[part 1 of 5: packages /E3_1_2_Premium to /Cluster]
AUTOSAR XML (schema 4-3-0)
package /E3_1_2_Premium
  system System: pnc-vector-length=7, pnc-vector-offset=1
package /ECU
  ecu instance BMC_HV:  # HV Batterie Management Control DFL-Kürzel: Hybrid_01
    associated-com-i-pdu-group=[BMC_HV_XIX_HCP5_CANFD01_Tx, BMC_HV_XIX_HCP5_CANFD01_Rx, BMC_HV_XIX_BMC_CAN01_Tx, BMC_HV_XIX_BMC_CAN01_Rx, BMC_HV_XIX_PNC_01_CarWakeUp_Tx, BMC_HV_XIX_PNC_02_Basefunction_Powertrain_Rx, BMC_HV_XIX_PNC_07_Basefunction_CrossSection_Rx, BMC_HV_XIX_PNC_06_Basefunction_ComfortLight_Rx, BMC_HV_XIX_PNC_10_Powertrain_Rx, BMC_HV_XIX_PNC_11_Chassis_Rx, BMC_HV_XIX_PNC_13_Airbag_Rx, BMC_HV_XIX_PNC_24_ThermoManagement_Rx, BMC_HV_XIX_PNC_26_HighVoltage_Charging_Tx, BMC_HV_XIX_PNC_26_HighVoltage_Charging_Rx, BMC_HV_XIX_PNC_30_EnergyManagement_Tx, BMC_HV_XIX_PNC_30_EnergyManagement_Rx, BMC_HV_XIX_PNC_27_Timemaster_Timer_Rx, BMC_HV_XIX_PNC_40_Diagnosis_Energy_Tx, BMC_HV_XIX_PNC_40_Diagnosis_Energy_Rx, PduGroup_afac5c56b3b64c7983bb0f7ebfc92c5a_Tx, PduGroup_7d6a32fb6b5340f18c0d3a0826764630_Tx, PduGroup_bd14174e250b400999f7534078763f9f_Rx]
    diagnostic-address=140
    pn-reset-time=0.5
    pnc-prepare-sleep-timer=0
    sleep-mode-supported=true
    wake-up-over-bus-supported=true
    can communication controller CT_HCP5_CANFD01: wake-up-by-controller-supported=true, can-controller-attributes=can-controller-configuration-requirements={can-controller-fd-requirements={max-number-of-time-quanta-per-bit=20, max-sample-point=70, max-sync-jump-width=30, max-trcv-delay-compensation-offset=3.5E-7, min-number-of-time-quanta-per-bit=20, min-sample-point=70, min-sync-jump-width=30, min-trcv-delay-compensation-offset=3.5E-7, tx-bit-rate-switch=true}, max-number-of-time-quanta-per-bit=80, max-sample-point=80, max-sync-jump-width=20, min-number-of-time-quanta-per-bit=80, min-sample-point=80, min-sync-jump-width=20}
    can communication controller CT_BMC_CAN01: wake-up-by-controller-supported=true, can-controller-attributes=can-controller-configuration-requirements={max-number-of-time-quanta-per-bit=20, max-sample-point=84, max-sync-jump-width=20, min-number-of-time-quanta-per-bit=10, min-sample-point=80, min-sync-jump-width=20}
    can communication connector CN_HCP5_CANFD01: comm-controller=CT_HCP5_CANFD01, pnc-gateway-type=NONE
    can communication connector CN_BMC_CAN01: comm-controller=CT_BMC_CAN01
package /Cluster
  can cluster HCP5_CANFD01: baudrate=500000, protocol-name=CAN, protocol-version=2.0, bus-off-recovery={bor-counter-l-1-to-l-2=1, bor-time-l-1=0.05, bor-time-l-2=0.2}, can-fd-baudrate=2000000  # HV
    can physical channel CHNL: comm-connectors=CN_HCP5_CANFD01
      frame Airbag_10_XIX_HCP5_CANFD01: id 0x11F, to BMC_HV, frame-length=20, can-addressing-mode=STANDARD, can-frame-rx-behavior=CAN-FD, can-frame-tx-behavior=CAN-FD
        pdu Airbag_10_XIX_HCP5_CANFD01: length=16, minimum-delay=0.01, transmission-mode-true-timing={cyclic-timing={time-offset=0, time-period=0.04}, event-controlled-timing={number-of-repetitions=5, repetition-period=0.01}}, unused-bit-pattern=0
          signal Airbag_10_CRC_XIX_Airbag_10_XIX_HCP5_CANFD01: start 0, 8 bit, little-endian, data-type-policy=OVERRIDE, i-signal-type=PRIMITIVE, init-value=0, base-type=BT_Airbag_10_CRC, compu-method=CM_Airbag_10_CRC, data-constr=DC_Airbag_10_CRC, transfer-property=PENDING  # Für MLB: Berechnung siehe Lastenheft "Kommunikationsabsicherung für FlexRay und CAN" Ab MQB und MLBevo: Berechnung siehe Lastenheft "End-to-End Kommunikationsabsicherung" Endwerte siehe Begleitdokument "S-PDU Kennungsfolgen"
          signal Airbag_10_BZ_XIX_Airbag_10_XIX_HCP5_CANFD01: start 8, 4 bit, little-endian, data-type-policy=OVERRIDE, i-signal-type=PRIMITIVE, init-value=0, base-type=BT_Airbag_10_BZ, compu-method=CM_Airbag_10_BZ, data-constr=DC_Airbag_10_BZ, transfer-property=PENDING  # 4bit-Botschaftszaehler, wird in jeder Sendebotschaft inkrementiert
          signal AB_VRU_Crash_XIX_Airbag_10_XIX_HCP5_CANFD01: start 12, 1 bit, little-endian, data-type-policy=OVERRIDE, i-signal-type=PRIMITIVE, init-value=0, base-type=BT_AB_VRU_Crash, compu-method=CM_AB_VRU_Crash, data-constr=DC_AB_VRU_Crash, transfer-property=TRIGGERED-ON-CHANGE  # Anprall eines Passanten erkannt
          signal AB_Lampe_XIX_Airbag_10_XIX_HCP5_CANFD01: start 13, 1 bit, little-endian, data-type-policy=OVERRIDE, i-signal-type=PRIMITIVE, init-value=1, base-type=BT_AB_Lampe, compu-method=CM_AB_Lampe, data-constr=DC_AB_Lampe, transfer-property=PENDING  # Sicherheitswarnlampe im Kombi wird vom Airbag-SG angesteuert; Zustand der Lampe wird auf dem CAN-Bus ausgegeben (auch Blinkinformation).
          signal AB_Front_Crash_XIX_Airbag_10_XIX_HCP5_CANFD01: start 14, 1 bit, little-endian, data-type-policy=OVERRIDE, i-signal-type=PRIMITIVE, init-value=0, base-type=BT_AB_Front_Crash, compu-method=CM_AB_Front_Crash, data-constr=DC_AB_Front_Crash, transfer-property=TRIGGERED-ON-CHANGE  # Bit wird bei Überschreitung der Gurtstraffer-, US- und RdW-Schwelle gesetzt
          signal AB_Heck_Crash_XIX_Airbag_10_XIX_HCP5_CANFD01: start 15, 1 bit, little-endian, data-type-policy=OVERRIDE, i-signal-type=PRIMITIVE, init-value=0, base-type=BT_AB_Heck_Crash, compu-method=CM_AB_Heck_Crash, data-constr=DC_AB_Heck_Crash, transfer-property=TRIGGERED-ON-CHANGE  # Wird für alle neu anlaufenden Projekte umgesetzt: AB8.4, Audi8/VW8
          signal AB_SF_Crash_XIX_Airbag_10_XIX_HCP5_CANFD01: start 16, 1 bit, little-endian, data-type-policy=OVERRIDE, i-signal-type=PRIMITIVE, init-value=0, base-type=BT_AB_SF_Crash, compu-method=CM_AB_SF_Crash, data-constr=DC_AB_SF_Crash, transfer-property=TRIGGERED-ON-CHANGE  # Z.Zt. nur in Verbindung mit Crash-Intensität >= 100b (Kraftstoffpumpenabschaltung) verwendet.
          signal AB_SB_Crash_XIX_Airbag_10_XIX_HCP5_CANFD01: start 17, 1 bit, little-endian, data-type-policy=OVERRIDE, i-signal-type=PRIMITIVE, init-value=0, base-type=BT_AB_SB_Crash, compu-method=CM_AB_SB_Crash, data-constr=DC_AB_SB_Crash, transfer-property=TRIGGERED-ON-CHANGE  # Z.Zt. nur in Verbindung mit Crash-Intensität >= 100b (Kraftstoffpumpenabschaltung) verwendet.
          signal AB_Rollover_Crash_XIX_Airbag_10_XIX_HCP5_CANFD01: start 18, 1 bit, little-endian, data-type-policy=OVERRIDE, i-signal-type=PRIMITIVE, init-value=0, base-type=BT_AB_Rollover_Crash, compu-method=CM_AB_Rollover_Crash, data-constr=DC_AB_Rollover_Crash, transfer-property=TRIGGERED-ON-CHANGE  # Wird im B6/B7 Cabrio und New Beetle Cabrio bedient.
          signal AB_Crash_Int_XIX_Airbag_10_XIX_HCP5_CANFD01: start 19, 3 bit, little-endian, data-type-policy=OVERRIDE, i-signal-type=PRIMITIVE, init-value=0, base-type=BT_AB_Crash_Int, compu-method=CM_AB_Crash_Int, data-constr=DC_AB_Crash_Int, transfer-property=TRIGGERED-ON-CHANGE  # Crash_Intensität_1 = fahrzeugabhängige Reaktionen im Crash Crash_Intensität_2 = fahrzeugabhängige Reaktionen im Crash Crash_Intensität_3 = fahrzeugabhängige Reaktionen im Crash Die jeweiligen fahrzeugabhängigen Reaktionen im Crash sind in einem separaten Doors Modul im Airbag-SG beschrieben. Die Information bleibt bei jeder Schwellwert-überschreitung für ~10 s bestehen (Achtung: Energiereserve bei abgetrennter Batterie reicht worstcase nur für 150 ms)
          signal AB_Systemfehler_XIX_Airbag_10_XIX_HCP5_CANFD01: start 22, 1 bit, little-endian, data-type-policy=OVERRIDE, i-signal-type=PRIMITIVE, init-value=0, base-type=BT_AB_Systemfehler, compu-method=CM_AB_Systemfehler, data-constr=DC_AB_Systemfehler, transfer-property=PENDING  # Systemfehler Ggf. wird Warnlampe dauernd eingeschaltet.
          signal AB_Stellgliedtest_XIX_Airbag_10_XIX_HCP5_CANFD01: start 23, 1 bit, little-endian, data-type-policy=OVERRIDE, i-signal-type=PRIMITIVE, init-value=0, base-type=BT_AB_Stellgliedtest, compu-method=CM_AB_Stellgliedtest, data-constr=DC_AB_Stellgliedtest, transfer-property=PENDING  # Information, ob Airbag im Stellgliedtest ist, um eine Notrufauflösung beim Stellgliedtest zu verhindern
          signal AB_Erh_Auf_VB_XIX_Airbag_10_XIX_HCP5_CANFD01: start 24, 2 bit, little-endian, data-type-policy=OVERRIDE, i-signal-type=PRIMITIVE, init-value=0, base-type=BT_AB_Erh_Auf_VB, compu-method=CM_AB_Erh_Auf_VB, data-constr=DC_AB_Erh_Auf_VB, transfer-property=PENDING  # Der Fahrer soll bei einem Statuswechsel des Beifahrerairbags (ausgelöst durch die Beifahrerinsassenerkennung oder den Schlüsselschloßschalter) aufmerksam gemacht werden durch eine Anzeige im Kombi. Nur Audi: gültig für: AB2 (4-Türer AU352), B7, C6, D3
          signal AB_Gurtwarn_VF_XIX_Airbag_10_XIX_HCP5_CANFD01: start 26, 1 bit, little-endian, data-type-policy=OVERRIDE, i-signal-type=PRIMITIVE, init-value=0, base-type=BT_AB_Gurtwarn_VF, compu-method=CM_AB_Gurtwarn_VF, data-constr=DC_AB_Gurtwarn_VF, transfer-property=TRIGGERED-ON-CHANGE-WITHOUT-REPETITION  # Fahrer hat Gurt nicht gesteckt, Anzeige im Kombi
          signal AB_Gurtwarn_VB_XIX_Airbag_10_XIX_HCP5_CANFD01: start 27, 1 bit, little-endian, data-type-policy=OVERRIDE, i-signal-type=PRIMITIVE, init-value=0, base-type=BT_AB_Gurtwarn_VB, compu-method=CM_AB_Gurtwarn_VB, data-constr=DC_AB_Gurtwarn_VB, transfer-property=TRIGGERED-ON-CHANGE-WITHOUT-REPETITION  # Beifahrer hat Gurt nicht gesteckt, Anzeige im Kombi
          signal AB_Anzeige_Fussg_XIX_Airbag_10_XIX_HCP5_CANFD01: start 28, 2 bit, little-endian, data-type-policy=OVERRIDE, i-signal-type=PRIMITIVE, init-value=0, base-type=BT_AB_Anzeige_Fussg, compu-method=CM_AB_Anzeige_Fussg, data-constr=DC_AB_Anzeige_Fussg, transfer-property=PENDING  # Anzeige für ausgelöste Fussgängerschutz-Aktuatorik
          signal AB_Belegung_VB_XIX_Airbag_10_XIX_HCP5_CANFD01: start 30, 2 bit, little-endian, data-type-policy=OVERRIDE, i-signal-type=PRIMITIVE, init-value=0, base-type=BT_AB_Belegung_VB, invalid-value=Invalid_AB_Belegung_VB_XIX_Airbag_10_XIX_HCP5_CANFD01:1, compu-method=CM_AB_Belegung_VB, data-constr=DC_AB_Belegung_VB, transfer-property=TRIGGERED-ON-CHANGE-WITHOUT-REPETITION  # Belegungserkennung vorne Beifahrer. Wird in US-Steuergeräten über Bladder-Matte bedient, optional bei RdW, falls SBE_EuroNCAP entschieden wird.
          signal AB_Versorgungsspannung_XIX_Airbag_10_XIX_HCP5_CANFD01: start 32, 1 bit, little-endian, data-type-policy=OVERRIDE, i-signal-type=PRIMITIVE, init-value=0, base-type=BT_AB_Versorgungsspannung, compu-method=CM_AB_Versorgungsspannung, data-constr=DC_AB_Versorgungsspannung, transfer-property=TRIGGERED-ON-CHANGE-WITHOUT-REPETITION  # Übertragung der Plausibilitätsinformation Kl.15-Last vs. Kl.15-CAN. Bedienung im Fall Kl.15-Last "EIN" und Kl.15-CAN "AUS" mit Ausgabe Warnung/Akustik im Kombi.
          signal AB_Sitzpos_Sens_BF_XIX_Airbag_10_XIX_HCP5_CANFD01: start 33, 2 bit, little-endian, data-type-policy=OVERRIDE, i-signal-type=PRIMITIVE, init-value=0, base-type=BT_AB_Sitzpos_Sens_BF, invalid-value=Invalid_AB_Sitzpos_Sens_BF_XIX_Airbag_10_XIX_HCP5_CANFD01:1, compu-method=CM_AB_Sitzpos_Sens_BF, data-constr=DC_AB_Sitzpos_Sens_BF, transfer-property=PENDING  # Ausgabe Sitzposition Beifahrer
          signal AB_Sitzpos_Sens_FA_XIX_Airbag_10_XIX_HCP5_CANFD01: start 35, 2 bit, little-endian, data-type-policy=OVERRIDE, i-signal-type=PRIMITIVE, init-value=0, base-type=BT_AB_Sitzpos_Sens_FA, invalid-value=Invalid_AB_Sitzpos_Sens_FA_XIX_Airbag_10_XIX_HCP5_CANFD01:1, compu-method=CM_AB_Sitzpos_Sens_FA, data-constr=DC_AB_Sitzpos_Sens_FA, transfer-property=PENDING  # Ausgabe Sitzposition Fahrer
          signal AB_Gurtschloss_FA_ext_XIX_Airbag_10_XIX_HCP5_CANFD01: start 37, 3 bit, little-endian, data-type-policy=OVERRIDE, i-signal-type=PRIMITIVE, init-value=6, base-type=BT_AB_Gurtschloss_FA_ext, invalid-value=Invalid_AB_Gurtschloss_FA_ext_XIX_Airbag_10_XIX_HCP5_CANFD01:7, compu-method=CM_AB_Gurtschloss_FA_ext, data-constr=DC_AB_Gurtschloss_FA_ext, transfer-property=TRIGGERED-ON-CHANGE-WITHOUT-REPETITION  # Das Ergebnis der Basisfunktion "Plausibilisierung Gurtschloss" des Verlassenskonzepts wird im Signal dargestellt.
          signal AB_Gurtschloss_FA_ext_aktiv_XIX_Airbag_10_XIX_HCP5_CANFD01: start 40, 1 bit, little-endian, data-type-policy=OVERRIDE, i-signal-type=PRIMITIVE, init-value=0, base-type=BT_AB_Gurtschloss_FA_ext_aktiv, compu-method=CM_AB_Gurtschloss_FA_ext_aktiv, data-constr=DC_AB_Gurtschloss_FA_ext_aktiv, transfer-property=TRIGGERED-ON-CHANGE-WITHOUT-REPETITION  # Über dieses Signal wird signalisiert ob die Erweiterte Gurtdiagnose (Ergebnis wird im Signal AB_Gurtschloss_FA_ext dargestellt) aktiviert oder deaktiviert ist.
          signal AB_Gurtschloss_BF_XIX_Airbag_10_XIX_HCP5_CANFD01: start 41, 2 bit, little-endian, data-type-policy=OVERRIDE, i-signal-type=PRIMITIVE, init-value=1, base-type=BT_AB_Gurtschloss_BF, compu-method=CM_AB_Gurtschloss_BF, data-constr=DC_AB_Gurtschloss_BF, transfer-property=TRIGGERED-ON-CHANGE-WITHOUT-REPETITION  # Gurtschlossstatus Beifahrerseite
          signal AB_Gurtschloss_FA_XIX_Airbag_10_XIX_HCP5_CANFD01: start 43, 2 bit, little-endian, data-type-policy=OVERRIDE, i-signal-type=PRIMITIVE, init-value=1, base-type=BT_AB_Gurtschloss_FA, compu-method=CM_AB_Gurtschloss_FA, data-constr=DC_AB_Gurtschloss_FA, transfer-property=TRIGGERED-ON-CHANGE-WITHOUT-REPETITION  # Gurtschlosstatatus Fahrerseite
          signal AB_Gurtschloss_Reihe3_BF_XIX_Airbag_10_XIX_HCP5_CANFD01: start 45, 2 bit, little-endian, data-type-policy=OVERRIDE, i-signal-type=PRIMITIVE, init-value=1, base-type=BT_AB_Gurtschloss_Reihe3_BF, compu-method=CM_AB_Gurtschloss_Reihe3_BF, data-constr=DC_AB_Gurtschloss_Reihe3_BF, transfer-property=TRIGGERED-ON-CHANGE-WITHOUT-REPETITION  # Gurtschlossstatus 3. Reihe Beifahrerseite, Mehrausstattung
          signal AB_Gurtschloss_Reihe2_BF_XIX_Airbag_10_XIX_HCP5_CANFD01: start 47, 2 bit, little-endian, data-type-policy=OVERRIDE, i-signal-type=PRIMITIVE, init-value=1, base-type=BT_AB_Gurtschloss_Reihe2_BF, compu-method=CM_AB_Gurtschloss_Reihe2_BF, data-constr=DC_AB_Gurtschloss_Reihe2_BF, transfer-property=TRIGGERED-ON-CHANGE-WITHOUT-REPETITION  # Gurtschlossstatus 2. Reihe Beifahrerseite, Mehrausstattung
          signal AB_Gurtschloss_Reihe2_FA_XIX_Airbag_10_XIX_HCP5_CANFD01: start 49, 2 bit, little-endian, data-type-policy=OVERRIDE, i-signal-type=PRIMITIVE, init-value=1, base-type=BT_AB_Gurtschloss_Reihe2_FA, compu-method=CM_AB_Gurtschloss_Reihe2_FA, data-constr=DC_AB_Gurtschloss_Reihe2_FA, transfer-property=TRIGGERED-ON-CHANGE-WITHOUT-REPETITION  # Gurtschlossstatus 2. Reihe Fahrerseite, Mehrausstattung
          signal AB_Gurtschloss_Reihe2_MI_XIX_Airbag_10_XIX_HCP5_CANFD01: start 51, 2 bit, little-endian, data-type-policy=OVERRIDE, i-signal-type=PRIMITIVE, init-value=1, base-type=BT_AB_Gurtschloss_Reihe2_MI, compu-method=CM_AB_Gurtschloss_Reihe2_MI, data-constr=DC_AB_Gurtschloss_Reihe2_MI, transfer-property=TRIGGERED-ON-CHANGE-WITHOUT-REPETITION  # Gurtschlossstatus 2. Reihe Mitte, Mehrausstattung
          signal AB_Gurtschloss_Reihe4_FA_XIX_Airbag_10_XIX_HCP5_CANFD01: start 53, 2 bit, little-endian, data-type-policy=OVERRIDE, i-signal-type=PRIMITIVE, init-value=1, base-type=BT_AB_Gurtschloss_Reihe4_FA, compu-method=CM_AB_Gurtschloss_Reihe4_FA, data-constr=DC_AB_Gurtschloss_Reihe4_FA, transfer-property=TRIGGERED-ON-CHANGE-WITHOUT-REPETITION  # Gurtschlossstatus 4. Reihe Fahrerseite, Mehrausstattung
          signal AB_Gurtschloss_Reihe3_FA_XIX_Airbag_10_XIX_HCP5_CANFD01: start 55, 2 bit, little-endian, data-type-policy=OVERRIDE, i-signal-type=PRIMITIVE, init-value=1, base-type=BT_AB_Gurtschloss_Reihe3_FA, compu-method=CM_AB_Gurtschloss_Reihe3_FA, data-constr=DC_AB_Gurtschloss_Reihe3_FA, transfer-property=TRIGGERED-ON-CHANGE-WITHOUT-REPETITION  # Gurtschlossstatus 3. Reihe Fahrerseite, Mehrausstattung
          signal AB_Gurtschloss_Reihe3_MI_XIX_Airbag_10_XIX_HCP5_CANFD01: start 57, 2 bit, little-endian, data-type-policy=OVERRIDE, i-signal-type=PRIMITIVE, init-value=1, base-type=BT_AB_Gurtschloss_Reihe3_MI, compu-method=CM_AB_Gurtschloss_Reihe3_MI, data-constr=DC_AB_Gurtschloss_Reihe3_MI, transfer-property=TRIGGERED-ON-CHANGE-WITHOUT-REPETITION  # Gurtschlossstatus 3. Reihe Mitte, Mehrausstattung
          signal AB_Gurtschloss_Reihe4_BF_XIX_Airbag_10_XIX_HCP5_CANFD01: start 59, 2 bit, little-endian, data-type-policy=OVERRIDE, i-signal-type=PRIMITIVE, init-value=1, base-type=BT_AB_Gurtschloss_Reihe4_BF, compu-method=CM_AB_Gurtschloss_Reihe4_BF, data-constr=DC_AB_Gurtschloss_Reihe4_BF, transfer-property=TRIGGERED-ON-CHANGE-WITHOUT-REPETITION  # Gurtschlossstatus 4. Reihe Beifahrerseite, Mehrausstattung
          signal AB_Gurtwarn_Reihe2_MI_XIX_Airbag_10_XIX_HCP5_CANFD01: start 61, 2 bit, little-endian, data-type-policy=OVERRIDE, i-signal-type=PRIMITIVE, init-value=0, base-type=BT_AB_Gurtwarn_Reihe2_MI, compu-method=CM_AB_Gurtwarn_Reihe2_MI, data-constr=DC_AB_Gurtwarn_Reihe2_MI, transfer-property=TRIGGERED-ON-CHANGE-WITHOUT-REPETITION  # Status Gurtwarnung 2. Sitzreihe Mitte
          signal AB_Gurtschloss_Reihe4_MI_XIX_Airbag_10_XIX_HCP5_CANFD01: start 63, 2 bit, little-endian, data-type-policy=OVERRIDE, i-signal-type=PRIMITIVE, init-value=1, base-type=BT_AB_Gurtschloss_Reihe4_MI, compu-method=CM_AB_Gurtschloss_Reihe4_MI, data-constr=DC_AB_Gurtschloss_Reihe4_MI, transfer-property=TRIGGERED-ON-CHANGE-WITHOUT-REPETITION  # Gurtschlossstatus 4. Reihe Mitte, Mehrausstattung
          signal AB_Gurtwarn_Reihe2_BF_XIX_Airbag_10_XIX_HCP5_CANFD01: start 65, 2 bit, little-endian, data-type-policy=OVERRIDE, i-signal-type=PRIMITIVE, init-value=0, base-type=BT_AB_Gurtwarn_Reihe2_BF, compu-method=CM_AB_Gurtwarn_Reihe2_BF, data-constr=DC_AB_Gurtwarn_Reihe2_BF, transfer-property=TRIGGERED-ON-CHANGE-WITHOUT-REPETITION  # Status Gurtwarnung 2. Sitzreihe Beifahrerseite
          signal AB_Gurtwarn_Reihe2_FA_XIX_Airbag_10_XIX_HCP5_CANFD01: start 67, 2 bit, little-endian, data-type-policy=OVERRIDE, i-signal-type=PRIMITIVE, init-value=0, base-type=BT_AB_Gurtwarn_Reihe2_FA, compu-method=CM_AB_Gurtwarn_Reihe2_FA, data-constr=DC_AB_Gurtwarn_Reihe2_FA, transfer-property=TRIGGERED-ON-CHANGE-WITHOUT-REPETITION  # Status Gurtwarnung 2. Sitzreihe Fahrerseite
          signal AB_Belegung_VF_ext_aktiv_XIX_Airbag_10_XIX_HCP5_CANFD01: start 69, 1 bit, little-endian, data-type-policy=OVERRIDE, i-signal-type=PRIMITIVE, init-value=0, base-type=BT_AB_Belegung_VF_ext_aktiv, compu-method=CM_AB_Belegung_VF_ext_aktiv, data-constr=DC_AB_Belegung_VF_ext_aktiv, transfer-property=PENDING  # Kennzeichnet aktive Funktion "Erweiterte Sitzbelegdiagnose" für Signal AB_Belegung_VF_ext
          signal AB_Belegung_VF_ext_XIX_Airbag_10_XIX_HCP5_CANFD01: start 70, 3 bit, little-endian, data-type-policy=OVERRIDE, i-signal-type=PRIMITIVE, init-value=6, base-type=BT_AB_Belegung_VF_ext, invalid-value=Invalid_AB_Belegung_VF_ext_XIX_Airbag_10_XIX_HCP5_CANFD01:7, compu-method=CM_AB_Belegung_VF_ext, data-constr=DC_AB_Belegung_VF_ext, transfer-property=TRIGGERED-ON-CHANGE-WITHOUT-REPETITION  # Das Signal kommuniziert den Status des Sitzbelegsensors Fahrer incl. dauerhafter Zustände mit Signalqualität ASIL A.
          signal AB_Abschaltanf_SIH_BF_XIX_Airbag_10_XIX_HCP5_CANFD01: start 73, 1 bit, little-endian, data-type-policy=OVERRIDE, i-signal-type=PRIMITIVE, init-value=0, base-type=BT_AB_Abschaltanf_SIH_BF, compu-method=CM_AB_Abschaltanf_SIH_BF, data-constr=DC_AB_Abschaltanf_SIH_BF, transfer-property=TRIGGERED-ON-CHANGE-WITHOUT-REPETITION  # Die Insassenerkennung auf der Beifahrerseite fordert bei Übertemperatur eine Abschaltung der Sitzheizung an. Die Übertemperatur kann bei niederohmigen Nebenschlüssen der Sitzheizungsmatte als Folge von zu hohem resultierenden Strom auftreten.
          signal AB_Gurtwarn_Reihe3_BF_XIX_Airbag_10_XIX_HCP5_CANFD01: start 74, 2 bit, little-endian, data-type-policy=OVERRIDE, i-signal-type=PRIMITIVE, init-value=0, base-type=BT_AB_Gurtwarn_Reihe3_BF, compu-method=CM_AB_Gurtwarn_Reihe3_BF, data-constr=DC_AB_Gurtwarn_Reihe3_BF, transfer-property=TRIGGERED-ON-CHANGE-WITHOUT-REPETITION  # Status Gurtwarnung 3. Sitzreihe Beifahrerseite
          signal AB_Gurtwarn_Reihe3_FA_XIX_Airbag_10_XIX_HCP5_CANFD01: start 76, 2 bit, little-endian, data-type-policy=OVERRIDE, i-signal-type=PRIMITIVE, init-value=0, base-type=BT_AB_Gurtwarn_Reihe3_FA, compu-method=CM_AB_Gurtwarn_Reihe3_FA, data-constr=DC_AB_Gurtwarn_Reihe3_FA, transfer-property=TRIGGERED-ON-CHANGE-WITHOUT-REPETITION  # Status Gurtwarnung 3. Sitzreihe Fahrerseite
          signal AB_Gurtwarn_Reihe3_MI_XIX_Airbag_10_XIX_HCP5_CANFD01: start 78, 2 bit, little-endian, data-type-policy=OVERRIDE, i-signal-type=PRIMITIVE, init-value=0, base-type=BT_AB_Gurtwarn_Reihe3_MI, compu-method=CM_AB_Gurtwarn_Reihe3_MI, data-constr=DC_AB_Gurtwarn_Reihe3_MI, transfer-property=TRIGGERED-ON-CHANGE-WITHOUT-REPETITION  # Status Gurtwarnung 3. Sitzreihe Mitte
          signal AB_PSS_SollZustand_XIX_Airbag_10_XIX_HCP5_CANFD01: start 80, 1 bit, little-endian, data-type-policy=OVERRIDE, i-signal-type=PRIMITIVE, init-value=0, base-type=BT_AB_PSS_SollZustand, compu-method=CM_AB_PSS_SollZustand, data-constr=DC_AB_PSS_SollZustand, transfer-property=TRIGGERED-ON-CHANGE  # Erwartete Auslösefähigkeit
          signal AB_EDR_Trigger_XIX_Airbag_10_XIX_HCP5_CANFD01: start 81, 2 bit, little-endian, data-type-policy=OVERRIDE, i-signal-type=PRIMITIVE, init-value=0, base-type=BT_AB_EDR_Trigger, compu-method=CM_AB_EDR_Trigger, data-constr=DC_AB_EDR_Trigger, transfer-property=TRIGGERED-ON-CHANGE-WITHOUT-REPETITION  # Triggerbedingung zur dezentralen Aufzeichnung unfallrelevanter Daten im Event Data Recorder
          signal AB_Deaktivierung_HV_XIX_Airbag_10_XIX_HCP5_CANFD01: start 83, 3 bit, little-endian, data-type-policy=OVERRIDE, i-signal-type=PRIMITIVE, init-value=0, base-type=BT_AB_Deaktivierung_HV, invalid-value=Invalid_AB_Deaktivierung_HV_XIX_Airbag_10_XIX_HCP5_CANFD01:7, compu-method=CM_AB_Deaktivierung_HV, data-constr=DC_AB_Deaktivierung_HV, transfer-property=TRIGGERED, to BMC_HV(timeout 0.5 s)  # Deaktivierung des HV-Systems und der HV-Teilnehmer im Crash (u.a. Hybrid- und Elektrofahrzeuge)
          signal AB_Belegung_VF_XIX_Airbag_10_XIX_HCP5_CANFD01: start 86, 2 bit, little-endian, data-type-policy=OVERRIDE, i-signal-type=PRIMITIVE, init-value=0, base-type=BT_AB_Belegung_VF, invalid-value=Invalid_AB_Belegung_VF_XIX_Airbag_10_XIX_HCP5_CANFD01:1, compu-method=CM_AB_Belegung_VF, data-constr=DC_AB_Belegung_VF, transfer-property=TRIGGERED-ON-CHANGE-WITHOUT-REPETITION  # Belegungserkennung vorne Fahrer.
          signal AB_SBR_hinten_verbau_XIX_Airbag_10_XIX_HCP5_CANFD01: start 88, 2 bit, little-endian, data-type-policy=OVERRIDE, i-signal-type=PRIMITIVE, init-value=3, base-type=BT_AB_SBR_hinten_verbau, compu-method=CM_AB_SBR_hinten_verbau, data-constr=DC_AB_SBR_hinten_verbau, transfer-property=PENDING  # Verbauinformation Sitzbelegungssensor hinten (2. und 3. Sitzreihe)
          signal MKB_ScndCllsnMtgtn_StAbo_XIX_Airbag_10_XIX_HCP5_CANFD01: start 90, 1 bit, little-endian, data-type-policy=OVERRIDE, i-signal-type=PRIMITIVE, init-value=0, base-type=BT_MKB_ScndCllsnMtgtn_StAbo, compu-method=CM_MKB_ScndCllsnMtgtn_StAbo, data-constr=DC_MKB_ScndCllsnMtgtn_StAbo, transfer-property=TRIGGERED-ON-CHANGE  # Request to abort second collision mitigation
          signal MKB_ScndCllsnMtgtn_StReq_XIX_Airbag_10_XIX_HCP5_CANFD01: start 91, 1 bit, little-endian, data-type-policy=OVERRIDE, i-signal-type=PRIMITIVE, init-value=0, base-type=BT_MKB_ScndCllsnMtgtn_StReq, compu-method=CM_MKB_ScndCllsnMtgtn_StReq, data-constr=DC_MKB_ScndCllsnMtgtn_StReq, transfer-property=TRIGGERED-ON-CHANGE  # Request to trigger second collision mitigation
          signal AB_DeltaV_X_eCall_XIX_Airbag_10_XIX_HCP5_CANFD01: start 92, 8 bit, little-endian, data-type-policy=OVERRIDE, i-signal-type=PRIMITIVE, init-value=0, base-type=BT_AB_DeltaV_X_eCall, compu-method=CM_AB_DeltaV_X_eCall, data-constr=DC_AB_DeltaV_X_eCall, unit=Unit_Unit_KiloMeterPerHour, transfer-property=TRIGGERED-ON-CHANGE-WITHOUT-REPETITION  # Transmission of the DeltaV longitudinal during Crash (0-250ms) as additional information for eCall
          signal AB_DeltaV_Y_eCall_XIX_Airbag_10_XIX_HCP5_CANFD01: start 100, 8 bit, little-endian, data-type-policy=OVERRIDE, i-signal-type=PRIMITIVE, init-value=0, base-type=BT_AB_DeltaV_Y_eCall, compu-method=CM_AB_DeltaV_Y_eCall, data-constr=DC_AB_DeltaV_Y_eCall, unit=Unit_Unit_KiloMeterPerHour, transfer-property=TRIGGERED-ON-CHANGE-WITHOUT-REPETITION  # Transmission of the DeltaV lateral during Crash (0-250ms) as additional information for eCall
      frame BMC_CMC_Temperatur_01_XIX_HCP5_CANFD01: id 0x1A55562A, from BMC_HV, frame-length=64, can-addressing-mode=EXTENDED, can-frame-rx-behavior=CAN-FD, can-frame-tx-behavior=CAN-FD
        pdu BMC_CMC_Temperatur_01_XIX_HCP5_CANFD01: length=64, transmission-mode-true-timing=cyclic-timing={time-offset=0, time-period=1}, unused-bit-pattern=0
          signal BMC_CMC_Temperatur_001_XIX_BMC_CMC_Temperatur_01_XIX_HCP5_CANFD01: start 16, 8 bit, little-endian, data-type-policy=OVERRIDE, i-signal-type=PRIMITIVE, init-value=254, base-type=BT_BMC_CMC_Temperatur_001, invalid-value=Invalid_BMC_CMC_Temperatur_001_XIX_BMC_CMC_Temperatur_01_XIX_HCP5_CANFD01:255, compu-method=CM_BMC_CMC_Temperatur_001, data-constr=DC_BMC_CMC_Temperatur_001, unit=Unit_Unit_DegreCelsi, transfer-property=PENDING  # Temperatur Zellmodul fuer die Uebertragung per RTM
          signal BMC_CMC_Temperatur_002_XIX_BMC_CMC_Temperatur_01_XIX_HCP5_CANFD01: start 24, 8 bit, little-endian, data-type-policy=OVERRIDE, i-signal-type=PRIMITIVE, init-value=254, base-type=BT_BMC_CMC_Temperatur_002, invalid-value=Invalid_BMC_CMC_Temperatur_002_XIX_BMC_CMC_Temperatur_01_XIX_HCP5_CANFD01:255, compu-method=CM_BMC_CMC_Temperatur_002, data-constr=DC_BMC_CMC_Temperatur_002, unit=Unit_Unit_DegreCelsi, transfer-property=PENDING  # Temperatur Zellmodul fuer die Uebertragung per RTM
          signal BMC_CMC_Temperatur_003_XIX_BMC_CMC_Temperatur_01_XIX_HCP5_CANFD01: start 32, 8 bit, little-endian, data-type-policy=OVERRIDE, i-signal-type=PRIMITIVE, init-value=254, base-type=BT_BMC_CMC_Temperatur_003, invalid-value=Invalid_BMC_CMC_Temperatur_003_XIX_BMC_CMC_Temperatur_01_XIX_HCP5_CANFD01:255, compu-method=CM_BMC_CMC_Temperatur_003, data-constr=DC_BMC_CMC_Temperatur_003, unit=Unit_Unit_DegreCelsi, transfer-property=PENDING  # Temperatur Zellmodul fuer die Uebertragung per RTM
          signal BMC_CMC_Temperatur_004_XIX_BMC_CMC_Temperatur_01_XIX_HCP5_CANFD01: start 40, 8 bit, little-endian, data-type-policy=OVERRIDE, i-signal-type=PRIMITIVE, init-value=254, base-type=BT_BMC_CMC_Temperatur_004, invalid-value=Invalid_BMC_CMC_Temperatur_004_XIX_BMC_CMC_Temperatur_01_XIX_HCP5_CANFD01:255, compu-method=CM_BMC_CMC_Temperatur_004, data-constr=DC_BMC_CMC_Temperatur_004, unit=Unit_Unit_DegreCelsi, transfer-property=PENDING  # Temperatur Zellmodul fuer die Uebertragung per RTM
          signal BMC_CMC_Temperatur_005_XIX_BMC_CMC_Temperatur_01_XIX_HCP5_CANFD01: start 48, 8 bit, little-endian, data-type-policy=OVERRIDE, i-signal-type=PRIMITIVE, init-value=254, base-type=BT_BMC_CMC_Temperatur_005, invalid-value=Invalid_BMC_CMC_Temperatur_005_XIX_BMC_CMC_Temperatur_01_XIX_HCP5_CANFD01:255, compu-method=CM_BMC_CMC_Temperatur_005, data-constr=DC_BMC_CMC_Temperatur_005, unit=Unit_Unit_DegreCelsi, transfer-property=PENDING  # Temperatur Zellmodul fuer die Uebertragung per RTM
          signal BMC_CMC_Temperatur_006_XIX_BMC_CMC_Temperatur_01_XIX_HCP5_CANFD01: start 56, 8 bit, little-endian, data-type-policy=OVERRIDE, i-signal-type=PRIMITIVE, init-value=254, base-type=BT_BMC_CMC_Temperatur_006, invalid-value=Invalid_BMC_CMC_Temperatur_006_XIX_BMC_CMC_Temperatur_01_XIX_HCP5_CANFD01:255, compu-method=CM_BMC_CMC_Temperatur_006, data-constr=DC_BMC_CMC_Temperatur_006, unit=Unit_Unit_DegreCelsi, transfer-property=PENDING  # Temperatur Zellmodul fuer die Uebertragung per RTM
          signal BMC_CMC_Temperatur_007_XIX_BMC_CMC_Temperatur_01_XIX_HCP5_CANFD01: start 64, 8 bit, little-endian, data-type-policy=OVERRIDE, i-signal-type=PRIMITIVE, init-value=254, base-type=BT_BMC_CMC_Temperatur_007, invalid-value=Invalid_BMC_CMC_Temperatur_007_XIX_BMC_CMC_Temperatur_01_XIX_HCP5_CANFD01:255, compu-method=CM_BMC_CMC_Temperatur_007, data-constr=DC_BMC_CMC_Temperatur_007, unit=Unit_Unit_DegreCelsi, transfer-property=PENDING  # Temperatur Zellmodul fuer die Uebertragung per RTM
          signal BMC_CMC_Temperatur_008_XIX_BMC_CMC_Temperatur_01_XIX_HCP5_CANFD01: start 72, 8 bit, little-endian, data-type-policy=OVERRIDE, i-signal-type=PRIMITIVE, init-value=254, base-type=BT_BMC_CMC_Temperatur_008, invalid-value=Invalid_BMC_CMC_Temperatur_008_XIX_BMC_CMC_Temperatur_01_XIX_HCP5_CANFD01:255, compu-method=CM_BMC_CMC_Temperatur_008, data-constr=DC_BMC_CMC_Temperatur_008, unit=Unit_Unit_DegreCelsi, transfer-property=PENDING  # Temperatur Zellmodul fuer die Uebertragung per RTM
          signal BMC_CMC_Temperatur_009_XIX_BMC_CMC_Temperatur_01_XIX_HCP5_CANFD01: start 80, 8 bit, little-endian, data-type-policy=OVERRIDE, i-signal-type=PRIMITIVE, init-value=254, base-type=BT_BMC_CMC_Temperatur_009, invalid-value=Invalid_BMC_CMC_Temperatur_009_XIX_BMC_CMC_Temperatur_01_XIX_HCP5_CANFD01:255, compu-method=CM_BMC_CMC_Temperatur_009, data-constr=DC_BMC_CMC_Temperatur_009, unit=Unit_Unit_DegreCelsi, transfer-property=PENDING  # Temperatur Zellmodul fuer die Uebertragung per RTM
          signal BMC_CMC_Temperatur_010_XIX_BMC_CMC_Temperatur_01_XIX_HCP5_CANFD01: start 88, 8 bit, little-endian, data-type-policy=OVERRIDE, i-signal-type=PRIMITIVE, init-value=254, base-type=BT_BMC_CMC_Temperatur_010, invalid-value=Invalid_BMC_CMC_Temperatur_010_XIX_BMC_CMC_Temperatur_01_XIX_HCP5_CANFD01:255, compu-method=CM_BMC_CMC_Temperatur_010, data-constr=DC_BMC_CMC_Temperatur_010, unit=Unit_Unit_DegreCelsi, transfer-property=PENDING  # Temperatur Zellmodul fuer die Uebertragung per RTM
          signal BMC_CMC_Temperatur_011_XIX_BMC_CMC_Temperatur_01_XIX_HCP5_CANFD01: start 96, 8 bit, little-endian, data-type-policy=OVERRIDE, i-signal-type=PRIMITIVE, init-value=254, base-type=BT_BMC_CMC_Temperatur_011, invalid-value=Invalid_BMC_CMC_Temperatur_011_XIX_BMC_CMC_Temperatur_01_XIX_HCP5_CANFD01:255, compu-method=CM_BMC_CMC_Temperatur_011, data-constr=DC_BMC_CMC_Temperatur_011, unit=Unit_Unit_DegreCelsi, transfer-property=PENDING  # Temperatur Zellmodul fuer die Uebertragung per RTM
          signal BMC_CMC_Temperatur_012_XIX_BMC_CMC_Temperatur_01_XIX_HCP5_CANFD01: start 104, 8 bit, little-endian, data-type-policy=OVERRIDE, i-signal-type=PRIMITIVE, init-value=254, base-type=BT_BMC_CMC_Temperatur_012, invalid-value=Invalid_BMC_CMC_Temperatur_012_XIX_BMC_CMC_Temperatur_01_XIX_HCP5_CANFD01:255, compu-method=CM_BMC_CMC_Temperatur_012, data-constr=DC_BMC_CMC_Temperatur_012, unit=Unit_Unit_DegreCelsi, transfer-property=PENDING  # Temperatur Zellmodul fuer die Uebertragung per RTM
          signal BMC_CMC_Temperatur_013_XIX_BMC_CMC_Temperatur_01_XIX_HCP5_CANFD01: start 112, 8 bit, little-endian, data-type-policy=OVERRIDE, i-signal-type=PRIMITIVE, init-value=254, base-type=BT_BMC_CMC_Temperatur_013, invalid-value=Invalid_BMC_CMC_Temperatur_013_XIX_BMC_CMC_Temperatur_01_XIX_HCP5_CANFD01:255, compu-method=CM_BMC_CMC_Temperatur_013, data-constr=DC_BMC_CMC_Temperatur_013, unit=Unit_Unit_DegreCelsi, transfer-property=PENDING  # Temperatur Zellmodul fuer die Uebertragung per RTM
          signal BMC_CMC_Temperatur_014_XIX_BMC_CMC_Temperatur_01_XIX_HCP5_CANFD01: start 120, 8 bit, little-endian, data-type-policy=OVERRIDE, i-signal-type=PRIMITIVE, init-value=254, base-type=BT_BMC_CMC_Temperatur_014, invalid-value=Invalid_BMC_CMC_Temperatur_014_XIX_BMC_CMC_Temperatur_01_XIX_HCP5_CANFD01:255, compu-method=CM_BMC_CMC_Temperatur_014, data-constr=DC_BMC_CMC_Temperatur_014, unit=Unit_Unit_DegreCelsi, transfer-property=PENDING  # Temperatur Zellmodul fuer die Uebertragung per RTM
          signal BMC_CMC_Temperatur_015_XIX_BMC_CMC_Temperatur_01_XIX_HCP5_CANFD01: start 128, 8 bit, little-endian, data-type-policy=OVERRIDE, i-signal-type=PRIMITIVE, init-value=254, base-type=BT_BMC_CMC_Temperatur_015, invalid-value=Invalid_BMC_CMC_Temperatur_015_XIX_BMC_CMC_Temperatur_01_XIX_HCP5_CANFD01:255, compu-method=CM_BMC_CMC_Temperatur_015, data-constr=DC_BMC_CMC_Temperatur_015, unit=Unit_Unit_DegreCelsi, transfer-property=PENDING  # Temperatur Zellmodul fuer die Uebertragung per RTM
          signal BMC_CMC_Temperatur_016_XIX_BMC_CMC_Temperatur_01_XIX_HCP5_CANFD01: start 136, 8 bit, little-endian, data-type-policy=OVERRIDE, i-signal-type=PRIMITIVE, init-value=254, base-type=BT_BMC_CMC_Temperatur_016, invalid-value=Invalid_BMC_CMC_Temperatur_016_XIX_BMC_CMC_Temperatur_01_XIX_HCP5_CANFD01:255, compu-method=CM_BMC_CMC_Temperatur_016, data-constr=DC_BMC_CMC_Temperatur_016, unit=Unit_Unit_DegreCelsi, transfer-property=PENDING  # Temperatur Zellmodul fuer die Uebertragung per RTM
          signal BMC_CMC_Temperatur_017_XIX_BMC_CMC_Temperatur_01_XIX_HCP5_CANFD01: start 144, 8 bit, little-endian, data-type-policy=OVERRIDE, i-signal-type=PRIMITIVE, init-value=254, base-type=BT_BMC_CMC_Temperatur_017, invalid-value=Invalid_BMC_CMC_Temperatur_017_XIX_BMC_CMC_Temperatur_01_XIX_HCP5_CANFD01:255, compu-method=CM_BMC_CMC_Temperatur_017, data-constr=DC_BMC_CMC_Temperatur_017, unit=Unit_Unit_DegreCelsi, transfer-property=PENDING  # Temperatur Zellmodul fuer die Uebertragung per RTM
          signal BMC_CMC_Temperatur_018_XIX_BMC_CMC_Temperatur_01_XIX_HCP5_CANFD01: start 152, 8 bit, little-endian, data-type-policy=OVERRIDE, i-signal-type=PRIMITIVE, init-value=254, base-type=BT_BMC_CMC_Temperatur_018, invalid-value=Invalid_BMC_CMC_Temperatur_018_XIX_BMC_CMC_Temperatur_01_XIX_HCP5_CANFD01:255, compu-method=CM_BMC_CMC_Temperatur_018, data-constr=DC_BMC_CMC_Temperatur_018, unit=Unit_Unit_DegreCelsi, transfer-property=PENDING  # Temperatur Zellmodul fuer die Uebertragung per RTM
          signal BMC_CMC_Temperatur_019_XIX_BMC_CMC_Temperatur_01_XIX_HCP5_CANFD01: start 160, 8 bit, little-endian, data-type-policy=OVERRIDE, i-signal-type=PRIMITIVE, init-value=254, base-type=BT_BMC_CMC_Temperatur_019, invalid-value=Invalid_BMC_CMC_Temperatur_019_XIX_BMC_CMC_Temperatur_01_XIX_HCP5_CANFD01:255, compu-method=CM_BMC_CMC_Temperatur_019, data-constr=DC_BMC_CMC_Temperatur_019, unit=Unit_Unit_DegreCelsi, transfer-property=PENDING  # Temperatur Zellmodul fuer die Uebertragung per RTM
          signal BMC_CMC_Temperatur_020_XIX_BMC_CMC_Temperatur_01_XIX_HCP5_CANFD01: start 168, 8 bit, little-endian, data-type-policy=OVERRIDE, i-signal-type=PRIMITIVE, init-value=254, base-type=BT_BMC_CMC_Temperatur_020, invalid-value=Invalid_BMC_CMC_Temperatur_020_XIX_BMC_CMC_Temperatur_01_XIX_HCP5_CANFD01:255, compu-method=CM_BMC_CMC_Temperatur_020, data-constr=DC_BMC_CMC_Temperatur_020, unit=Unit_Unit_DegreCelsi, transfer-property=PENDING  # Temperatur Zellmodul fuer die Uebertragung per RTM
          signal BMC_CMC_Temperatur_021_XIX_BMC_CMC_Temperatur_01_XIX_HCP5_CANFD01: start 176, 8 bit, little-endian, data-type-policy=OVERRIDE, i-signal-type=PRIMITIVE, init-value=254, base-type=BT_BMC_CMC_Temperatur_021, invalid-value=Invalid_BMC_CMC_Temperatur_021_XIX_BMC_CMC_Temperatur_01_XIX_HCP5_CANFD01:255, compu-method=CM_BMC_CMC_Temperatur_021, data-constr=DC_BMC_CMC_Temperatur_021, unit=Unit_Unit_DegreCelsi, transfer-property=PENDING  # Temperatur Zellmodul fuer die Uebertragung per RTM
          signal BMC_CMC_Temperatur_022_XIX_BMC_CMC_Temperatur_01_XIX_HCP5_CANFD01: start 184, 8 bit, little-endian, data-type-policy=OVERRIDE, i-signal-type=PRIMITIVE, init-value=254, base-type=BT_BMC_CMC_Temperatur_022, invalid-value=Invalid_BMC_CMC_Temperatur_022_XIX_BMC_CMC_Temperatur_01_XIX_HCP5_CANFD01:255, compu-method=CM_BMC_CMC_Temperatur_022, data-constr=DC_BMC_CMC_Temperatur_022, unit=Unit_Unit_DegreCelsi, transfer-property=PENDING  # Temperatur Zellmodul fuer die Uebertragung per RTM
          signal BMC_CMC_Temperatur_023_XIX_BMC_CMC_Temperatur_01_XIX_HCP5_CANFD01: start 192, 8 bit, little-endian, data-type-policy=OVERRIDE, i-signal-type=PRIMITIVE, init-value=254, base-type=BT_BMC_CMC_Temperatur_023, invalid-value=Invalid_BMC_CMC_Temperatur_023_XIX_BMC_CMC_Temperatur_01_XIX_HCP5_CANFD01:255, compu-method=CM_BMC_CMC_Temperatur_023, data-constr=DC_BMC_CMC_Temperatur_023, unit=Unit_Unit_DegreCelsi, transfer-property=PENDING  # Temperatur Zellmodul fuer die Uebertragung per RTM
          signal BMC_CMC_Temperatur_024_XIX_BMC_CMC_Temperatur_01_XIX_HCP5_CANFD01: start 200, 8 bit, little-endian, data-type-policy=OVERRIDE, i-signal-type=PRIMITIVE, init-value=254, base-type=BT_BMC_CMC_Temperatur_024, invalid-value=Invalid_BMC_CMC_Temperatur_024_XIX_BMC_CMC_Temperatur_01_XIX_HCP5_CANFD01:255, compu-method=CM_BMC_CMC_Temperatur_024, data-constr=DC_BMC_CMC_Temperatur_024, unit=Unit_Unit_DegreCelsi, transfer-property=PENDING  # Temperatur Zellmodul fuer die Uebertragung per RTM
          signal BMC_CMC_Temperatur_025_XIX_BMC_CMC_Temperatur_01_XIX_HCP5_CANFD01: start 208, 8 bit, little-endian, data-type-policy=OVERRIDE, i-signal-type=PRIMITIVE, init-value=254, base-type=BT_BMC_CMC_Temperatur_025, invalid-value=Invalid_BMC_CMC_Temperatur_025_XIX_BMC_CMC_Temperatur_01_XIX_HCP5_CANFD01:255, compu-method=CM_BMC_CMC_Temperatur_025, data-constr=DC_BMC_CMC_Temperatur_025, unit=Unit_Unit_DegreCelsi, transfer-property=PENDING  # Temperatur Zellmodul fuer die Uebertragung per RTM
          signal BMC_CMC_Temperatur_026_XIX_BMC_CMC_Temperatur_01_XIX_HCP5_CANFD01: start 216, 8 bit, little-endian, data-type-policy=OVERRIDE, i-signal-type=PRIMITIVE, init-value=254, base-type=BT_BMC_CMC_Temperatur_026, invalid-value=Invalid_BMC_CMC_Temperatur_026_XIX_BMC_CMC_Temperatur_01_XIX_HCP5_CANFD01:255, compu-method=CM_BMC_CMC_Temperatur_026, data-constr=DC_BMC_CMC_Temperatur_026, unit=Unit_Unit_DegreCelsi, transfer-property=PENDING  # Temperatur Zellmodul fuer die Uebertragung per RTM
          signal BMC_CMC_Temperatur_027_XIX_BMC_CMC_Temperatur_01_XIX_HCP5_CANFD01: start 224, 8 bit, little-endian, data-type-policy=OVERRIDE, i-signal-type=PRIMITIVE, init-value=254, base-type=BT_BMC_CMC_Temperatur_027, invalid-value=Invalid_BMC_CMC_Temperatur_027_XIX_BMC_CMC_Temperatur_01_XIX_HCP5_CANFD01:255, compu-method=CM_BMC_CMC_Temperatur_027, data-constr=DC_BMC_CMC_Temperatur_027, unit=Unit_Unit_DegreCelsi, transfer-property=PENDING  # Temperatur Zellmodul fuer die Uebertragung per RTM
          signal BMC_CMC_Temperatur_028_XIX_BMC_CMC_Temperatur_01_XIX_HCP5_CANFD01: start 232, 8 bit, little-endian, data-type-policy=OVERRIDE, i-signal-type=PRIMITIVE, init-value=254, base-type=BT_BMC_CMC_Temperatur_028, invalid-value=Invalid_BMC_CMC_Temperatur_028_XIX_BMC_CMC_Temperatur_01_XIX_HCP5_CANFD01:255, compu-method=CM_BMC_CMC_Temperatur_028, data-constr=DC_BMC_CMC_Temperatur_028, unit=Unit_Unit_DegreCelsi, transfer-property=PENDING  # Temperatur Zellmodul fuer die Uebertragung per RTM
          signal BMC_CMC_Temperatur_029_XIX_BMC_CMC_Temperatur_01_XIX_HCP5_CANFD01: start 240, 8 bit, little-endian, data-type-policy=OVERRIDE, i-signal-type=PRIMITIVE, init-value=254, base-type=BT_BMC_CMC_Temperatur_029, invalid-value=Invalid_BMC_CMC_Temperatur_029_XIX_BMC_CMC_Temperatur_01_XIX_HCP5_CANFD01:255, compu-method=CM_BMC_CMC_Temperatur_029, data-constr=DC_BMC_CMC_Temperatur_029, unit=Unit_Unit_DegreCelsi, transfer-property=PENDING  # Temperatur Zellmodul fuer die Uebertragung per RTM
          signal BMC_CMC_Temperatur_030_XIX_BMC_CMC_Temperatur_01_XIX_HCP5_CANFD01: start 248, 8 bit, little-endian, data-type-policy=OVERRIDE, i-signal-type=PRIMITIVE, init-value=254, base-type=BT_BMC_CMC_Temperatur_030, invalid-value=Invalid_BMC_CMC_Temperatur_030_XIX_BMC_CMC_Temperatur_01_XIX_HCP5_CANFD01:255, compu-method=CM_BMC_CMC_Temperatur_030, data-constr=DC_BMC_CMC_Temperatur_030, unit=Unit_Unit_DegreCelsi, transfer-property=PENDING  # Temperatur Zellmodul fuer die Uebertragung per RTM
          signal BMC_CMC_Temperatur_031_XIX_BMC_CMC_Temperatur_01_XIX_HCP5_CANFD01: start 256, 8 bit, little-endian, data-type-policy=OVERRIDE, i-signal-type=PRIMITIVE, init-value=254, base-type=BT_BMC_CMC_Temperatur_031, invalid-value=Invalid_BMC_CMC_Temperatur_031_XIX_BMC_CMC_Temperatur_01_XIX_HCP5_CANFD01:255, compu-method=CM_BMC_CMC_Temperatur_031, data-constr=DC_BMC_CMC_Temperatur_031, unit=Unit_Unit_DegreCelsi, transfer-property=PENDING  # Temperatur Zellmodul fuer die Uebertragung per RTM
          signal BMC_CMC_Temperatur_032_XIX_BMC_CMC_Temperatur_01_XIX_HCP5_CANFD01: start 264, 8 bit, little-endian, data-type-policy=OVERRIDE, i-signal-type=PRIMITIVE, init-value=254, base-type=BT_BMC_CMC_Temperatur_032, invalid-value=Invalid_BMC_CMC_Temperatur_032_XIX_BMC_CMC_Temperatur_01_XIX_HCP5_CANFD01:255, compu-method=CM_BMC_CMC_Temperatur_032, data-constr=DC_BMC_CMC_Temperatur_032, unit=Unit_Unit_DegreCelsi, transfer-property=PENDING  # Temperatur Zellmodul fuer die Uebertragung per RTM
          signal BMC_CMC_Temperatur_033_XIX_BMC_CMC_Temperatur_01_XIX_HCP5_CANFD01: start 272, 8 bit, little-endian, data-type-policy=OVERRIDE, i-signal-type=PRIMITIVE, init-value=254, base-type=BT_BMC_CMC_Temperatur_033, invalid-value=Invalid_BMC_CMC_Temperatur_033_XIX_BMC_CMC_Temperatur_01_XIX_HCP5_CANFD01:255, compu-method=CM_BMC_CMC_Temperatur_033, data-constr=DC_BMC_CMC_Temperatur_033, unit=Unit_Unit_DegreCelsi, transfer-property=PENDING  # Temperatur Zellmodul fuer die Uebertragung per RTM
          signal BMC_CMC_Temperatur_034_XIX_BMC_CMC_Temperatur_01_XIX_HCP5_CANFD01: start 280, 8 bit, little-endian, data-type-policy=OVERRIDE, i-signal-type=PRIMITIVE, init-value=254, base-type=BT_BMC_CMC_Temperatur_034, invalid-value=Invalid_BMC_CMC_Temperatur_034_XIX_BMC_CMC_Temperatur_01_XIX_HCP5_CANFD01:255, compu-method=CM_BMC_CMC_Temperatur_034, data-constr=DC_BMC_CMC_Temperatur_034, unit=Unit_Unit_DegreCelsi, transfer-property=PENDING  # Temperatur Zellmodul fuer die Uebertragung per RTM
          signal BMC_CMC_Temperatur_035_XIX_BMC_CMC_Temperatur_01_XIX_HCP5_CANFD01: start 288, 8 bit, little-endian, data-type-policy=OVERRIDE, i-signal-type=PRIMITIVE, init-value=254, base-type=BT_BMC_CMC_Temperatur_035, invalid-value=Invalid_BMC_CMC_Temperatur_035_XIX_BMC_CMC_Temperatur_01_XIX_HCP5_CANFD01:255, compu-method=CM_BMC_CMC_Temperatur_035, data-constr=DC_BMC_CMC_Temperatur_035, unit=Unit_Unit_DegreCelsi, transfer-property=PENDING  # Temperatur Zellmodul fuer die Uebertragung per RTM
          signal BMC_CMC_Temperatur_036_XIX_BMC_CMC_Temperatur_01_XIX_HCP5_CANFD01: start 296, 8 bit, little-endian, data-type-policy=OVERRIDE, i-signal-type=PRIMITIVE, init-value=254, base-type=BT_BMC_CMC_Temperatur_036, invalid-value=Invalid_BMC_CMC_Temperatur_036_XIX_BMC_CMC_Temperatur_01_XIX_HCP5_CANFD01:255, compu-method=CM_BMC_CMC_Temperatur_036, data-constr=DC_BMC_CMC_Temperatur_036, unit=Unit_Unit_DegreCelsi, transfer-property=PENDING  # Temperatur Zellmodul fuer die Uebertragung per RTM
          signal BMC_CMC_Temperatur_037_XIX_BMC_CMC_Temperatur_01_XIX_HCP5_CANFD01: start 304, 8 bit, little-endian, data-type-policy=OVERRIDE, i-signal-type=PRIMITIVE, init-value=254, base-type=BT_BMC_CMC_Temperatur_037, invalid-value=Invalid_BMC_CMC_Temperatur_037_XIX_BMC_CMC_Temperatur_01_XIX_HCP5_CANFD01:255, compu-method=CM_BMC_CMC_Temperatur_037, data-constr=DC_BMC_CMC_Temperatur_037, unit=Unit_Unit_DegreCelsi, transfer-property=PENDING  # Temperatur Zellmodul fuer die Uebertragung per RTM
          signal BMC_CMC_Temperatur_038_XIX_BMC_CMC_Temperatur_01_XIX_HCP5_CANFD01: start 312, 8 bit, little-endian, data-type-policy=OVERRIDE, i-signal-type=PRIMITIVE, init-value=254, base-type=BT_BMC_CMC_Temperatur_038, invalid-value=Invalid_BMC_CMC_Temperatur_038_XIX_BMC_CMC_Temperatur_01_XIX_HCP5_CANFD01:255, compu-method=CM_BMC_CMC_Temperatur_038, data-constr=DC_BMC_CMC_Temperatur_038, unit=Unit_Unit_DegreCelsi, transfer-property=PENDING  # Temperatur Zellmodul fuer die Uebertragung per RTM
          signal BMC_CMC_Temperatur_039_XIX_BMC_CMC_Temperatur_01_XIX_HCP5_CANFD01: start 320, 8 bit, little-endian, data-type-policy=OVERRIDE, i-signal-type=PRIMITIVE, init-value=254, base-type=BT_BMC_CMC_Temperatur_039, invalid-value=Invalid_BMC_CMC_Temperatur_039_XIX_BMC_CMC_Temperatur_01_XIX_HCP5_CANFD01:255, compu-method=CM_BMC_CMC_Temperatur_039, data-constr=DC_BMC_CMC_Temperatur_039, unit=Unit_Unit_DegreCelsi, transfer-property=PENDING  # Temperatur Zellmodul fuer die Uebertragung per RTM
          signal BMC_CMC_Temperatur_040_XIX_BMC_CMC_Temperatur_01_XIX_HCP5_CANFD01: start 328, 8 bit, little-endian, data-type-policy=OVERRIDE, i-signal-type=PRIMITIVE, init-value=254, base-type=BT_BMC_CMC_Temperatur_040, invalid-value=Invalid_BMC_CMC_Temperatur_040_XIX_BMC_CMC_Temperatur_01_XIX_HCP5_CANFD01:255, compu-method=CM_BMC_CMC_Temperatur_040, data-constr=DC_BMC_CMC_Temperatur_040, unit=Unit_Unit_DegreCelsi, transfer-property=PENDING  # Temperatur Zellmodul fuer die Uebertragung per RTM
          signal BMC_CMC_Temperatur_041_XIX_BMC_CMC_Temperatur_01_XIX_HCP5_CANFD01: start 336, 8 bit, little-endian, data-type-policy=OVERRIDE, i-signal-type=PRIMITIVE, init-value=254, base-type=BT_BMC_CMC_Temperatur_041, invalid-value=Invalid_BMC_CMC_Temperatur_041_XIX_BMC_CMC_Temperatur_01_XIX_HCP5_CANFD01:255, compu-method=CM_BMC_CMC_Temperatur_041, data-constr=DC_BMC_CMC_Temperatur_041, unit=Unit_Unit_DegreCelsi, transfer-property=PENDING  # Temperatur Zellmodul fuer die Uebertragung per RTM
          signal BMC_CMC_Temperatur_042_XIX_BMC_CMC_Temperatur_01_XIX_HCP5_CANFD01: start 344, 8 bit, little-endian, data-type-policy=OVERRIDE, i-signal-type=PRIMITIVE, init-value=254, base-type=BT_BMC_CMC_Temperatur_042, invalid-value=Invalid_BMC_CMC_Temperatur_042_XIX_BMC_CMC_Temperatur_01_XIX_HCP5_CANFD01:255, compu-method=CM_BMC_CMC_Temperatur_042, data-constr=DC_BMC_CMC_Temperatur_042, unit=Unit_Unit_DegreCelsi, transfer-property=PENDING  # Temperatur Zellmodul fuer die Uebertragung per RTM
          signal BMC_CMC_Temperatur_043_XIX_BMC_CMC_Temperatur_01_XIX_HCP5_CANFD01: start 352, 8 bit, little-endian, data-type-policy=OVERRIDE, i-signal-type=PRIMITIVE, init-value=254, base-type=BT_BMC_CMC_Temperatur_043, invalid-value=Invalid_BMC_CMC_Temperatur_043_XIX_BMC_CMC_Temperatur_01_XIX_HCP5_CANFD01:255, compu-method=CM_BMC_CMC_Temperatur_043, data-constr=DC_BMC_CMC_Temperatur_043, unit=Unit_Unit_DegreCelsi, transfer-property=PENDING  # Temperatur Zellmodul fuer die Uebertragung per RTM
          signal BMC_CMC_Temperatur_044_XIX_BMC_CMC_Temperatur_01_XIX_HCP5_CANFD01: start 360, 8 bit, little-endian, data-type-policy=OVERRIDE, i-signal-type=PRIMITIVE, init-value=254, base-type=BT_BMC_CMC_Temperatur_044, invalid-value=Invalid_BMC_CMC_Temperatur_044_XIX_BMC_CMC_Temperatur_01_XIX_HCP5_CANFD01:255, compu-method=CM_BMC_CMC_Temperatur_044, data-constr=DC_BMC_CMC_Temperatur_044, unit=Unit_Unit_DegreCelsi, transfer-property=PENDING  # Temperatur Zellmodul fuer die Uebertragung per RTM
          signal BMC_CMC_Temperatur_045_XIX_BMC_CMC_Temperatur_01_XIX_HCP5_CANFD01: start 368, 8 bit, little-endian, data-type-policy=OVERRIDE, i-signal-type=PRIMITIVE, init-value=254, base-type=BT_BMC_CMC_Temperatur_045, invalid-value=Invalid_BMC_CMC_Temperatur_045_XIX_BMC_CMC_Temperatur_01_XIX_HCP5_CANFD01:255, compu-method=CM_BMC_CMC_Temperatur_045, data-constr=DC_BMC_CMC_Temperatur_045, unit=Unit_Unit_DegreCelsi, transfer-property=PENDING  # Temperatur Zellmodul fuer die Uebertragung per RTM
          signal BMC_CMC_Temperatur_046_XIX_BMC_CMC_Temperatur_01_XIX_HCP5_CANFD01: start 376, 8 bit, little-endian, data-type-policy=OVERRIDE, i-signal-type=PRIMITIVE, init-value=254, base-type=BT_BMC_CMC_Temperatur_046, invalid-value=Invalid_BMC_CMC_Temperatur_046_XIX_BMC_CMC_Temperatur_01_XIX_HCP5_CANFD01:255, compu-method=CM_BMC_CMC_Temperatur_046, data-constr=DC_BMC_CMC_Temperatur_046, unit=Unit_Unit_DegreCelsi, transfer-property=PENDING  # Temperatur Zellmodul fuer die Uebertragung per RTM
          signal BMC_CMC_Temperatur_047_XIX_BMC_CMC_Temperatur_01_XIX_HCP5_CANFD01: start 384, 8 bit, little-endian, data-type-policy=OVERRIDE, i-signal-type=PRIMITIVE, init-value=254, base-type=BT_BMC_CMC_Temperatur_047, invalid-value=Invalid_BMC_CMC_Temperatur_047_XIX_BMC_CMC_Temperatur_01_XIX_HCP5_CANFD01:255, compu-method=CM_BMC_CMC_Temperatur_047, data-constr=DC_BMC_CMC_Temperatur_047, unit=Unit_Unit_DegreCelsi, transfer-property=PENDING  # Temperatur Zellmodul fuer die Uebertragung per RTM
          signal BMC_CMC_Temperatur_048_XIX_BMC_CMC_Temperatur_01_XIX_HCP5_CANFD01: start 392, 8 bit, little-endian, data-type-policy=OVERRIDE, i-signal-type=PRIMITIVE, init-value=254, base-type=BT_BMC_CMC_Temperatur_048, invalid-value=Invalid_BMC_CMC_Temperatur_048_XIX_BMC_CMC_Temperatur_01_XIX_HCP5_CANFD01:255, compu-method=CM_BMC_CMC_Temperatur_048, data-constr=DC_BMC_CMC_Temperatur_048, unit=Unit_Unit_DegreCelsi, transfer-property=PENDING  # Temperatur Zellmodul fuer die Uebertragung per RTM
          signal BMC_CMC_Temperatur_049_XIX_BMC_CMC_Temperatur_01_XIX_HCP5_CANFD01: start 400, 8 bit, little-endian, data-type-policy=OVERRIDE, i-signal-type=PRIMITIVE, init-value=254, base-type=BT_BMC_CMC_Temperatur_049, invalid-value=Invalid_BMC_CMC_Temperatur_049_XIX_BMC_CMC_Temperatur_01_XIX_HCP5_CANFD01:255, compu-method=CM_BMC_CMC_Temperatur_049, data-constr=DC_BMC_CMC_Temperatur_049, unit=Unit_Unit_DegreCelsi, transfer-property=PENDING  # Temperatur Zellmodul fuer die Uebertragung per RTM
          signal BMC_CMC_Temperatur_050_XIX_BMC_CMC_Temperatur_01_XIX_HCP5_CANFD01: start 408, 8 bit, little-endian, data-type-policy=OVERRIDE, i-signal-type=PRIMITIVE, init-value=254, base-type=BT_BMC_CMC_Temperatur_050, invalid-value=Invalid_BMC_CMC_Temperatur_050_XIX_BMC_CMC_Temperatur_01_XIX_HCP5_CANFD01:255, compu-method=CM_BMC_CMC_Temperatur_050, data-constr=DC_BMC_CMC_Temperatur_050, unit=Unit_Unit_DegreCelsi, transfer-property=PENDING  # Temperatur Zellmodul fuer die Uebertragung per RTM
          signal BMC_CMC_Temperatur_051_XIX_BMC_CMC_Temperatur_01_XIX_HCP5_CANFD01: start 416, 8 bit, little-endian, data-type-policy=OVERRIDE, i-signal-type=PRIMITIVE, init-value=254, base-type=BT_BMC_CMC_Temperatur_051, invalid-value=Invalid_BMC_CMC_Temperatur_051_XIX_BMC_CMC_Temperatur_01_XIX_HCP5_CANFD01:255, compu-method=CM_BMC_CMC_Temperatur_051, data-constr=DC_BMC_CMC_Temperatur_051, unit=Unit_Unit_DegreCelsi, transfer-property=PENDING  # Temperatur Zellmodul fuer die Uebertragung per RTM
          signal BMC_CMC_Temperatur_052_XIX_BMC_CMC_Temperatur_01_XIX_HCP5_CANFD01: start 424, 8 bit, little-endian, data-type-policy=OVERRIDE, i-signal-type=PRIMITIVE, init-value=254, base-type=BT_BMC_CMC_Temperatur_052, invalid-value=Invalid_BMC_CMC_Temperatur_052_XIX_BMC_CMC_Temperatur_01_XIX_HCP5_CANFD01:255, compu-method=CM_BMC_CMC_Temperatur_052, data-constr=DC_BMC_CMC_Temperatur_052, unit=Unit_Unit_DegreCelsi, transfer-property=PENDING  # Temperatur Zellmodul fuer die Uebertragung per RTM
          signal BMC_CMC_Temperatur_053_XIX_BMC_CMC_Temperatur_01_XIX_HCP5_CANFD01: start 432, 8 bit, little-endian, data-type-policy=OVERRIDE, i-signal-type=PRIMITIVE, init-value=254, base-type=BT_BMC_CMC_Temperatur_053, invalid-value=Invalid_BMC_CMC_Temperatur_053_XIX_BMC_CMC_Temperatur_01_XIX_HCP5_CANFD01:255, compu-method=CM_BMC_CMC_Temperatur_053, data-constr=DC_BMC_CMC_Temperatur_053, unit=Unit_Unit_DegreCelsi, transfer-property=PENDING  # Temperatur Zellmodul fuer die Uebertragung per RTM
          signal BMC_CMC_Temperatur_054_XIX_BMC_CMC_Temperatur_01_XIX_HCP5_CANFD01: start 440, 8 bit, little-endian, data-type-policy=OVERRIDE, i-signal-type=PRIMITIVE, init-value=254, base-type=BT_BMC_CMC_Temperatur_054, invalid-value=Invalid_BMC_CMC_Temperatur_054_XIX_BMC_CMC_Temperatur_01_XIX_HCP5_CANFD01:255, compu-method=CM_BMC_CMC_Temperatur_054, data-constr=DC_BMC_CMC_Temperatur_054, unit=Unit_Unit_DegreCelsi, transfer-property=PENDING  # Temperatur Zellmodul fuer die Uebertragung per RTM
          signal BMC_CMC_Temperatur_055_XIX_BMC_CMC_Temperatur_01_XIX_HCP5_CANFD01: start 448, 8 bit, little-endian, data-type-policy=OVERRIDE, i-signal-type=PRIMITIVE, init-value=254, base-type=BT_BMC_CMC_Temperatur_055, invalid-value=Invalid_BMC_CMC_Temperatur_055_XIX_BMC_CMC_Temperatur_01_XIX_HCP5_CANFD01:255, compu-method=CM_BMC_CMC_Temperatur_055, data-constr=DC_BMC_CMC_Temperatur_055, unit=Unit_Unit_DegreCelsi, transfer-property=PENDING  # Temperatur Zellmodul fuer die Uebertragung per RTM
          signal BMC_CMC_Temperatur_056_XIX_BMC_CMC_Temperatur_01_XIX_HCP5_CANFD01: start 456, 8 bit, little-endian, data-type-policy=OVERRIDE, i-signal-type=PRIMITIVE, init-value=254, base-type=BT_BMC_CMC_Temperatur_056, invalid-value=Invalid_BMC_CMC_Temperatur_056_XIX_BMC_CMC_Temperatur_01_XIX_HCP5_CANFD01:255, compu-method=CM_BMC_CMC_Temperatur_056, data-constr=DC_BMC_CMC_Temperatur_056, unit=Unit_Unit_DegreCelsi, transfer-property=PENDING  # Temperatur Zellmodul fuer die Uebertragung per RTM
          signal BMC_CMC_Temperatur_057_XIX_BMC_CMC_Temperatur_01_XIX_HCP5_CANFD01: start 464, 8 bit, little-endian, data-type-policy=OVERRIDE, i-signal-type=PRIMITIVE, init-value=254, base-type=BT_BMC_CMC_Temperatur_057, invalid-value=Invalid_BMC_CMC_Temperatur_057_XIX_BMC_CMC_Temperatur_01_XIX_HCP5_CANFD01:255, compu-method=CM_BMC_CMC_Temperatur_057, data-constr=DC_BMC_CMC_Temperatur_057, unit=Unit_Unit_DegreCelsi, transfer-property=PENDING  # Temperatur Zellmodul fuer die Uebertragung per RTM
          signal BMC_CMC_Temperatur_058_XIX_BMC_CMC_Temperatur_01_XIX_HCP5_CANFD01: start 472, 8 bit, little-endian, data-type-policy=OVERRIDE, i-signal-type=PRIMITIVE, init-value=254, base-type=BT_BMC_CMC_Temperatur_058, invalid-value=Invalid_BMC_CMC_Temperatur_058_XIX_BMC_CMC_Temperatur_01_XIX_HCP5_CANFD01:255, compu-method=CM_BMC_CMC_Temperatur_058, data-constr=DC_BMC_CMC_Temperatur_058, unit=Unit_Unit_DegreCelsi, transfer-property=PENDING  # Temperatur Zellmodul fuer die Uebertragung per RTM
          signal BMC_CMC_Temperatur_01_Messzeit_XIX_BMC_CMC_Temperatur_01_XIX_HCP5_CANFD01: start 480, 8 bit, little-endian, data-type-policy=OVERRIDE, i-signal-type=PRIMITIVE, init-value=254, base-type=BT_BMC_CMC_Temperatur_01_Messzeit, invalid-value=Invalid_BMC_CMC_Temperatur_01_Messzeit_XIX_BMC_CMC_Temperatur_01_XIX_HCP5_CANFD01:255, compu-method=CM_BMC_CMC_Temperatur_01_Messzeit, data-constr=DC_BMC_CMC_Temperatur_01_Messzeit, unit=Unit_Unit_None, transfer-property=PENDING  # Messzeit zu Botschaft BMC_CMC_Temperatur_01
      frame BMC_CMC_Temperatur_02_XIX_HCP5_CANFD01: id 0x1A55562B, from BMC_HV, frame-length=24, can-addressing-mode=EXTENDED, can-frame-rx-behavior=CAN-FD, can-frame-tx-behavior=CAN-FD
        pdu BMC_CMC_Temperatur_02_XIX_HCP5_CANFD01: length=24, transmission-mode-true-timing=cyclic-timing={time-offset=0, time-period=1}, unused-bit-pattern=0
          signal BMC_CMC_Temperatur_059_XIX_BMC_CMC_Temperatur_02_XIX_HCP5_CANFD01: start 16, 8 bit, little-endian, data-type-policy=OVERRIDE, i-signal-type=PRIMITIVE, init-value=254, base-type=BT_BMC_CMC_Temperatur_059, invalid-value=Invalid_BMC_CMC_Temperatur_059_XIX_BMC_CMC_Temperatur_02_XIX_HCP5_CANFD01:255, compu-method=CM_BMC_CMC_Temperatur_059, data-constr=DC_BMC_CMC_Temperatur_059, unit=Unit_Unit_DegreCelsi, transfer-property=PENDING  # Temperatur Zellmodul fuer die Uebertragung per RTM
          signal BMC_CMC_Temperatur_060_XIX_BMC_CMC_Temperatur_02_XIX_HCP5_CANFD01: start 24, 8 bit, little-endian, data-type-policy=OVERRIDE, i-signal-type=PRIMITIVE, init-value=254, base-type=BT_BMC_CMC_Temperatur_060, invalid-value=Invalid_BMC_CMC_Temperatur_060_XIX_BMC_CMC_Temperatur_02_XIX_HCP5_CANFD01:255, compu-method=CM_BMC_CMC_Temperatur_060, data-constr=DC_BMC_CMC_Temperatur_060, unit=Unit_Unit_DegreCelsi, transfer-property=PENDING  # Temperatur Zellmodul fuer die Uebertragung per RTM
          signal BMC_CMC_Temperatur_061_XIX_BMC_CMC_Temperatur_02_XIX_HCP5_CANFD01: start 32, 8 bit, little-endian, data-type-policy=OVERRIDE, i-signal-type=PRIMITIVE, init-value=254, base-type=BT_BMC_CMC_Temperatur_061, invalid-value=Invalid_BMC_CMC_Temperatur_061_XIX_BMC_CMC_Temperatur_02_XIX_HCP5_CANFD01:255, compu-method=CM_BMC_CMC_Temperatur_061, data-constr=DC_BMC_CMC_Temperatur_061, unit=Unit_Unit_DegreCelsi, transfer-property=PENDING  # Temperatur Zellmodul fuer die Uebertragung per RTM
          signal BMC_CMC_Temperatur_062_XIX_BMC_CMC_Temperatur_02_XIX_HCP5_CANFD01: start 40, 8 bit, little-endian, data-type-policy=OVERRIDE, i-signal-type=PRIMITIVE, init-value=254, base-type=BT_BMC_CMC_Temperatur_062, invalid-value=Invalid_BMC_CMC_Temperatur_062_XIX_BMC_CMC_Temperatur_02_XIX_HCP5_CANFD01:255, compu-method=CM_BMC_CMC_Temperatur_062, data-constr=DC_BMC_CMC_Temperatur_062, unit=Unit_Unit_DegreCelsi, transfer-property=PENDING  # Temperatur Zellmodul fuer die Uebertragung per RTM
          signal BMC_CMC_Temperatur_063_XIX_BMC_CMC_Temperatur_02_XIX_HCP5_CANFD01: start 48, 8 bit, little-endian, data-type-policy=OVERRIDE, i-signal-type=PRIMITIVE, init-value=254, base-type=BT_BMC_CMC_Temperatur_063, invalid-value=Invalid_BMC_CMC_Temperatur_063_XIX_BMC_CMC_Temperatur_02_XIX_HCP5_CANFD01:255, compu-method=CM_BMC_CMC_Temperatur_063, data-constr=DC_BMC_CMC_Temperatur_063, unit=Unit_Unit_DegreCelsi, transfer-property=PENDING  # Temperatur Zellmodul fuer die Uebertragung per RTM
          signal BMC_CMC_Temperatur_064_XIX_BMC_CMC_Temperatur_02_XIX_HCP5_CANFD01: start 56, 8 bit, little-endian, data-type-policy=OVERRIDE, i-signal-type=PRIMITIVE, init-value=254, base-type=BT_BMC_CMC_Temperatur_064, invalid-value=Invalid_BMC_CMC_Temperatur_064_XIX_BMC_CMC_Temperatur_02_XIX_HCP5_CANFD01:255, compu-method=CM_BMC_CMC_Temperatur_064, data-constr=DC_BMC_CMC_Temperatur_064, unit=Unit_Unit_DegreCelsi, transfer-property=PENDING  # Temperatur Zellmodul fuer die Uebertragung per RTM
          signal BMC_CMC_Temperatur_065_XIX_BMC_CMC_Temperatur_02_XIX_HCP5_CANFD01: start 64, 8 bit, little-endian, data-type-policy=OVERRIDE, i-signal-type=PRIMITIVE, init-value=254, base-type=BT_BMC_CMC_Temperatur_065, invalid-value=Invalid_BMC_CMC_Temperatur_065_XIX_BMC_CMC_Temperatur_02_XIX_HCP5_CANFD01:255, compu-method=CM_BMC_CMC_Temperatur_065, data-constr=DC_BMC_CMC_Temperatur_065, unit=Unit_Unit_DegreCelsi, transfer-property=PENDING  # Temperatur Zellmodul fuer die Uebertragung per RTM
          signal BMC_CMC_Temperatur_066_XIX_BMC_CMC_Temperatur_02_XIX_HCP5_CANFD01: start 72, 8 bit, little-endian, data-type-policy=OVERRIDE, i-signal-type=PRIMITIVE, init-value=254, base-type=BT_BMC_CMC_Temperatur_066, invalid-value=Invalid_BMC_CMC_Temperatur_066_XIX_BMC_CMC_Temperatur_02_XIX_HCP5_CANFD01:255, compu-method=CM_BMC_CMC_Temperatur_066, data-constr=DC_BMC_CMC_Temperatur_066, unit=Unit_Unit_DegreCelsi, transfer-property=PENDING  # Temperatur Zellmodul fuer die Uebertragung per RTM
          signal BMC_CMC_Temperatur_067_XIX_BMC_CMC_Temperatur_02_XIX_HCP5_CANFD01: start 80, 8 bit, little-endian, data-type-policy=OVERRIDE, i-signal-type=PRIMITIVE, init-value=254, base-type=BT_BMC_CMC_Temperatur_067, invalid-value=Invalid_BMC_CMC_Temperatur_067_XIX_BMC_CMC_Temperatur_02_XIX_HCP5_CANFD01:255, compu-method=CM_BMC_CMC_Temperatur_067, data-constr=DC_BMC_CMC_Temperatur_067, unit=Unit_Unit_DegreCelsi, transfer-property=PENDING  # Temperatur Zellmodul fuer die Uebertragung per RTM
          signal BMC_CMC_Temperatur_068_XIX_BMC_CMC_Temperatur_02_XIX_HCP5_CANFD01: start 88, 8 bit, little-endian, data-type-policy=OVERRIDE, i-signal-type=PRIMITIVE, init-value=254, base-type=BT_BMC_CMC_Temperatur_068, invalid-value=Invalid_BMC_CMC_Temperatur_068_XIX_BMC_CMC_Temperatur_02_XIX_HCP5_CANFD01:255, compu-method=CM_BMC_CMC_Temperatur_068, data-constr=DC_BMC_CMC_Temperatur_068, unit=Unit_Unit_DegreCelsi, transfer-property=PENDING  # Temperatur Zellmodul fuer die Uebertragung per RTM
          signal BMC_CMC_Temperatur_069_XIX_BMC_CMC_Temperatur_02_XIX_HCP5_CANFD01: start 96, 8 bit, little-endian, data-type-policy=OVERRIDE, i-signal-type=PRIMITIVE, init-value=254, base-type=BT_BMC_CMC_Temperatur_069, invalid-value=Invalid_BMC_CMC_Temperatur_069_XIX_BMC_CMC_Temperatur_02_XIX_HCP5_CANFD01:255, compu-method=CM_BMC_CMC_Temperatur_069, data-constr=DC_BMC_CMC_Temperatur_069, unit=Unit_Unit_DegreCelsi, transfer-property=PENDING  # Temperatur Zellmodul fuer die Uebertragung per RTM
          signal BMC_CMC_Temperatur_070_XIX_BMC_CMC_Temperatur_02_XIX_HCP5_CANFD01: start 104, 8 bit, little-endian, data-type-policy=OVERRIDE, i-signal-type=PRIMITIVE, init-value=254, base-type=BT_BMC_CMC_Temperatur_070, invalid-value=Invalid_BMC_CMC_Temperatur_070_XIX_BMC_CMC_Temperatur_02_XIX_HCP5_CANFD01:255, compu-method=CM_BMC_CMC_Temperatur_070, data-constr=DC_BMC_CMC_Temperatur_070, unit=Unit_Unit_DegreCelsi, transfer-property=PENDING  # Temperatur Zellmodul fuer die Uebertragung per RTM
          signal BMC_CMC_Temperatur_071_XIX_BMC_CMC_Temperatur_02_XIX_HCP5_CANFD01: start 112, 8 bit, little-endian, data-type-policy=OVERRIDE, i-signal-type=PRIMITIVE, init-value=254, base-type=BT_BMC_CMC_Temperatur_071, invalid-value=Invalid_BMC_CMC_Temperatur_071_XIX_BMC_CMC_Temperatur_02_XIX_HCP5_CANFD01:255, compu-method=CM_BMC_CMC_Temperatur_071, data-constr=DC_BMC_CMC_Temperatur_071, unit=Unit_Unit_DegreCelsi, transfer-property=PENDING  # Temperatur Zellmodul fuer die Uebertragung per RTM
          signal BMC_CMC_Temperatur_072_XIX_BMC_CMC_Temperatur_02_XIX_HCP5_CANFD01: start 120, 8 bit, little-endian, data-type-policy=OVERRIDE, i-signal-type=PRIMITIVE, init-value=254, base-type=BT_BMC_CMC_Temperatur_072, invalid-value=Invalid_BMC_CMC_Temperatur_072_XIX_BMC_CMC_Temperatur_02_XIX_HCP5_CANFD01:255, compu-method=CM_BMC_CMC_Temperatur_072, data-constr=DC_BMC_CMC_Temperatur_072, unit=Unit_Unit_DegreCelsi, transfer-property=PENDING  # Temperatur Zellmodul fuer die Uebertragung per RTM
          signal BMC_CMC_Temperatur_02_Messzeit_XIX_BMC_CMC_Temperatur_02_XIX_HCP5_CANFD01: start 128, 8 bit, little-endian, data-type-policy=OVERRIDE, i-signal-type=PRIMITIVE, init-value=254, base-type=BT_BMC_CMC_Temperatur_02_Messzeit, invalid-value=Invalid_BMC_CMC_Temperatur_02_Messzeit_XIX_BMC_CMC_Temperatur_02_XIX_HCP5_CANFD01:255, compu-method=CM_BMC_CMC_Temperatur_02_Messzeit, data-constr=DC_BMC_CMC_Temperatur_02_Messzeit, unit=Unit_Unit_None, transfer-property=PENDING  # Messzeit zu Botschaft BMC_CMC_Temperatur_02
      frame BMC_CMC_Temperatur_03_XIX_HCP5_CANFD01: id 0x1A55566C, from BMC_HV, frame-length=64, can-addressing-mode=EXTENDED, can-frame-rx-behavior=CAN-FD, can-frame-tx-behavior=CAN-FD
        pdu BMC_CMC_Temperatur_03_XIX_HCP5_CANFD01: length=64, transmission-mode-true-timing=cyclic-timing={time-offset=0, time-period=1}, unused-bit-pattern=0
          signal BMC_CMC_Temperatur_073_XIX_BMC_CMC_Temperatur_03_XIX_HCP5_CANFD01: start 16, 8 bit, little-endian, data-type-policy=OVERRIDE, i-signal-type=PRIMITIVE, init-value=254, base-type=BT_BMC_CMC_Temperatur_073, invalid-value=Invalid_BMC_CMC_Temperatur_073_XIX_BMC_CMC_Temperatur_03_XIX_HCP5_CANFD01:255, compu-method=CM_BMC_CMC_Temperatur_073, data-constr=DC_BMC_CMC_Temperatur_073, unit=Unit_Unit_DegreCelsi, transfer-property=PENDING  # Temperatur Zellmodul fuer die Uebertragung per RTM
          signal BMC_CMC_Temperatur_074_XIX_BMC_CMC_Temperatur_03_XIX_HCP5_CANFD01: start 24, 8 bit, little-endian, data-type-policy=OVERRIDE, i-signal-type=PRIMITIVE, init-value=254, base-type=BT_BMC_CMC_Temperatur_074, invalid-value=Invalid_BMC_CMC_Temperatur_074_XIX_BMC_CMC_Temperatur_03_XIX_HCP5_CANFD01:255, compu-method=CM_BMC_CMC_Temperatur_074, data-constr=DC_BMC_CMC_Temperatur_074, unit=Unit_Unit_DegreCelsi, transfer-property=PENDING  # Temperatur Zellmodul fuer die Uebertragung per RTM
          signal BMC_CMC_Temperatur_075_XIX_BMC_CMC_Temperatur_03_XIX_HCP5_CANFD01: start 32, 8 bit, little-endian, data-type-policy=OVERRIDE, i-signal-type=PRIMITIVE, init-value=254, base-type=BT_BMC_CMC_Temperatur_075, invalid-value=Invalid_BMC_CMC_Temperatur_075_XIX_BMC_CMC_Temperatur_03_XIX_HCP5_CANFD01:255, compu-method=CM_BMC_CMC_Temperatur_075, data-constr=DC_BMC_CMC_Temperatur_075, unit=Unit_Unit_DegreCelsi, transfer-property=PENDING  # Temperatur Zellmodul fuer die Uebertragung per RTM
          signal BMC_CMC_Temperatur_076_XIX_BMC_CMC_Temperatur_03_XIX_HCP5_CANFD01: start 40, 8 bit, little-endian, data-type-policy=OVERRIDE, i-signal-type=PRIMITIVE, init-value=254, base-type=BT_BMC_CMC_Temperatur_076, invalid-value=Invalid_BMC_CMC_Temperatur_076_XIX_BMC_CMC_Temperatur_03_XIX_HCP5_CANFD01:255, compu-method=CM_BMC_CMC_Temperatur_076, data-constr=DC_BMC_CMC_Temperatur_076, unit=Unit_Unit_DegreCelsi, transfer-property=PENDING  # Temperatur Zellmodul fuer die Uebertragung per RTM
          signal BMC_CMC_Temperatur_077_XIX_BMC_CMC_Temperatur_03_XIX_HCP5_CANFD01: start 48, 8 bit, little-endian, data-type-policy=OVERRIDE, i-signal-type=PRIMITIVE, init-value=254, base-type=BT_BMC_CMC_Temperatur_077, invalid-value=Invalid_BMC_CMC_Temperatur_077_XIX_BMC_CMC_Temperatur_03_XIX_HCP5_CANFD01:255, compu-method=CM_BMC_CMC_Temperatur_077, data-constr=DC_BMC_CMC_Temperatur_077, unit=Unit_Unit_DegreCelsi, transfer-property=PENDING  # Temperatur Zellmodul fuer die Uebertragung per RTM
          signal BMC_CMC_Temperatur_078_XIX_BMC_CMC_Temperatur_03_XIX_HCP5_CANFD01: start 56, 8 bit, little-endian, data-type-policy=OVERRIDE, i-signal-type=PRIMITIVE, init-value=254, base-type=BT_BMC_CMC_Temperatur_078, invalid-value=Invalid_BMC_CMC_Temperatur_078_XIX_BMC_CMC_Temperatur_03_XIX_HCP5_CANFD01:255, compu-method=CM_BMC_CMC_Temperatur_078, data-constr=DC_BMC_CMC_Temperatur_078, unit=Unit_Unit_DegreCelsi, transfer-property=PENDING  # Temperatur Zellmodul fuer die Uebertragung per RTM
          signal BMC_CMC_Temperatur_079_XIX_BMC_CMC_Temperatur_03_XIX_HCP5_CANFD01: start 64, 8 bit, little-endian, data-type-policy=OVERRIDE, i-signal-type=PRIMITIVE, init-value=254, base-type=BT_BMC_CMC_Temperatur_079, invalid-value=Invalid_BMC_CMC_Temperatur_079_XIX_BMC_CMC_Temperatur_03_XIX_HCP5_CANFD01:255, compu-method=CM_BMC_CMC_Temperatur_079, data-constr=DC_BMC_CMC_Temperatur_079, unit=Unit_Unit_DegreCelsi, transfer-property=PENDING  # Temperatur Zellmodul fuer die Uebertragung per RTM
          signal BMC_CMC_Temperatur_080_XIX_BMC_CMC_Temperatur_03_XIX_HCP5_CANFD01: start 72, 8 bit, little-endian, data-type-policy=OVERRIDE, i-signal-type=PRIMITIVE, init-value=254, base-type=BT_BMC_CMC_Temperatur_080, invalid-value=Invalid_BMC_CMC_Temperatur_080_XIX_BMC_CMC_Temperatur_03_XIX_HCP5_CANFD01:255, compu-method=CM_BMC_CMC_Temperatur_080, data-constr=DC_BMC_CMC_Temperatur_080, unit=Unit_Unit_DegreCelsi, transfer-property=PENDING  # Temperatur Zellmodul fuer die Uebertragung per RTM
          signal BMC_CMC_Temperatur_081_XIX_BMC_CMC_Temperatur_03_XIX_HCP5_CANFD01: start 80, 8 bit, little-endian, data-type-policy=OVERRIDE, i-signal-type=PRIMITIVE, init-value=254, base-type=BT_BMC_CMC_Temperatur_081, invalid-value=Invalid_BMC_CMC_Temperatur_081_XIX_BMC_CMC_Temperatur_03_XIX_HCP5_CANFD01:255, compu-method=CM_BMC_CMC_Temperatur_081, data-constr=DC_BMC_CMC_Temperatur_081, unit=Unit_Unit_DegreCelsi, transfer-property=PENDING  # Temperatur Zellmodul fuer die Uebertragung per RTM
          signal BMC_CMC_Temperatur_082_XIX_BMC_CMC_Temperatur_03_XIX_HCP5_CANFD01: start 88, 8 bit, little-endian, data-type-policy=OVERRIDE, i-signal-type=PRIMITIVE, init-value=254, base-type=BT_BMC_CMC_Temperatur_082, invalid-value=Invalid_BMC_CMC_Temperatur_082_XIX_BMC_CMC_Temperatur_03_XIX_HCP5_CANFD01:255, compu-method=CM_BMC_CMC_Temperatur_082, data-constr=DC_BMC_CMC_Temperatur_082, unit=Unit_Unit_DegreCelsi, transfer-property=PENDING  # Temperatur Zellmodul fuer die Uebertragung per RTM
          signal BMC_CMC_Temperatur_083_XIX_BMC_CMC_Temperatur_03_XIX_HCP5_CANFD01: start 96, 8 bit, little-endian, data-type-policy=OVERRIDE, i-signal-type=PRIMITIVE, init-value=254, base-type=BT_BMC_CMC_Temperatur_083, invalid-value=Invalid_BMC_CMC_Temperatur_083_XIX_BMC_CMC_Temperatur_03_XIX_HCP5_CANFD01:255, compu-method=CM_BMC_CMC_Temperatur_083, data-constr=DC_BMC_CMC_Temperatur_083, unit=Unit_Unit_DegreCelsi, transfer-property=PENDING  # Temperatur Zellmodul fuer die Uebertragung per RTM
          signal BMC_CMC_Temperatur_084_XIX_BMC_CMC_Temperatur_03_XIX_HCP5_CANFD01: start 104, 8 bit, little-endian, data-type-policy=OVERRIDE, i-signal-type=PRIMITIVE, init-value=254, base-type=BT_BMC_CMC_Temperatur_084, invalid-value=Invalid_BMC_CMC_Temperatur_084_XIX_BMC_CMC_Temperatur_03_XIX_HCP5_CANFD01:255, compu-method=CM_BMC_CMC_Temperatur_084, data-constr=DC_BMC_CMC_Temperatur_084, unit=Unit_Unit_DegreCelsi, transfer-property=PENDING  # Temperatur Zellmodul fuer die Uebertragung per RTM
          signal BMC_CMC_Temperatur_085_XIX_BMC_CMC_Temperatur_03_XIX_HCP5_CANFD01: start 112, 8 bit, little-endian, data-type-policy=OVERRIDE, i-signal-type=PRIMITIVE, init-value=254, base-type=BT_BMC_CMC_Temperatur_085, invalid-value=Invalid_BMC_CMC_Temperatur_085_XIX_BMC_CMC_Temperatur_03_XIX_HCP5_CANFD01:255, compu-method=CM_BMC_CMC_Temperatur_085, data-constr=DC_BMC_CMC_Temperatur_085, unit=Unit_Unit_DegreCelsi, transfer-property=PENDING  # Temperatur Zellmodul fuer die Uebertragung per RTM
          signal BMC_CMC_Temperatur_086_XIX_BMC_CMC_Temperatur_03_XIX_HCP5_CANFD01: start 120, 8 bit, little-endian, data-type-policy=OVERRIDE, i-signal-type=PRIMITIVE, init-value=254, base-type=BT_BMC_CMC_Temperatur_086, invalid-value=Invalid_BMC_CMC_Temperatur_086_XIX_BMC_CMC_Temperatur_03_XIX_HCP5_CANFD01:255, compu-method=CM_BMC_CMC_Temperatur_086, data-constr=DC_BMC_CMC_Temperatur_086, unit=Unit_Unit_DegreCelsi, transfer-property=PENDING  # Temperatur Zellmodul fuer die Uebertragung per RTM
          signal BMC_CMC_Temperatur_087_XIX_BMC_CMC_Temperatur_03_XIX_HCP5_CANFD01: start 128, 8 bit, little-endian, data-type-policy=OVERRIDE, i-signal-type=PRIMITIVE, init-value=254, base-type=BT_BMC_CMC_Temperatur_087, invalid-value=Invalid_BMC_CMC_Temperatur_087_XIX_BMC_CMC_Temperatur_03_XIX_HCP5_CANFD01:255, compu-method=CM_BMC_CMC_Temperatur_087, data-constr=DC_BMC_CMC_Temperatur_087, unit=Unit_Unit_DegreCelsi, transfer-property=PENDING  # Temperatur Zellmodul fuer die Uebertragung per RTM
          signal BMC_CMC_Temperatur_088_XIX_BMC_CMC_Temperatur_03_XIX_HCP5_CANFD01: start 136, 8 bit, little-endian, data-type-policy=OVERRIDE, i-signal-type=PRIMITIVE, init-value=254, base-type=BT_BMC_CMC_Temperatur_088, invalid-value=Invalid_BMC_CMC_Temperatur_088_XIX_BMC_CMC_Temperatur_03_XIX_HCP5_CANFD01:255, compu-method=CM_BMC_CMC_Temperatur_088, data-constr=DC_BMC_CMC_Temperatur_088, unit=Unit_Unit_DegreCelsi, transfer-property=PENDING  # Temperatur Zellmodul fuer die Uebertragung per RTM
          signal BMC_CMC_Temperatur_089_XIX_BMC_CMC_Temperatur_03_XIX_HCP5_CANFD01: start 144, 8 bit, little-endian, data-type-policy=OVERRIDE, i-signal-type=PRIMITIVE, init-value=254, base-type=BT_BMC_CMC_Temperatur_089, invalid-value=Invalid_BMC_CMC_Temperatur_089_XIX_BMC_CMC_Temperatur_03_XIX_HCP5_CANFD01:255, compu-method=CM_BMC_CMC_Temperatur_089, data-constr=DC_BMC_CMC_Temperatur_089, unit=Unit_Unit_DegreCelsi, transfer-property=PENDING  # Temperatur Zellmodul fuer die Uebertragung per RTM
          signal BMC_CMC_Temperatur_090_XIX_BMC_CMC_Temperatur_03_XIX_HCP5_CANFD01: start 152, 8 bit, little-endian, data-type-policy=OVERRIDE, i-signal-type=PRIMITIVE, init-value=254, base-type=BT_BMC_CMC_Temperatur_090, invalid-value=Invalid_BMC_CMC_Temperatur_090_XIX_BMC_CMC_Temperatur_03_XIX_HCP5_CANFD01:255, compu-method=CM_BMC_CMC_Temperatur_090, data-constr=DC_BMC_CMC_Temperatur_090, unit=Unit_Unit_DegreCelsi, transfer-property=PENDING  # Temperatur Zellmodul fuer die Uebertragung per RTM
          signal BMC_CMC_Temperatur_091_XIX_BMC_CMC_Temperatur_03_XIX_HCP5_CANFD01: start 160, 8 bit, little-endian, data-type-policy=OVERRIDE, i-signal-type=PRIMITIVE, init-value=254, base-type=BT_BMC_CMC_Temperatur_091, invalid-value=Invalid_BMC_CMC_Temperatur_091_XIX_BMC_CMC_Temperatur_03_XIX_HCP5_CANFD01:255, compu-method=CM_BMC_CMC_Temperatur_091, data-constr=DC_BMC_CMC_Temperatur_091, unit=Unit_Unit_DegreCelsi, transfer-property=PENDING  # Temperatur Zellmodul fuer die Uebertragung per RTM
          signal BMC_CMC_Temperatur_092_XIX_BMC_CMC_Temperatur_03_XIX_HCP5_CANFD01: start 168, 8 bit, little-endian, data-type-policy=OVERRIDE, i-signal-type=PRIMITIVE, init-value=254, base-type=BT_BMC_CMC_Temperatur_092, invalid-value=Invalid_BMC_CMC_Temperatur_092_XIX_BMC_CMC_Temperatur_03_XIX_HCP5_CANFD01:255, compu-method=CM_BMC_CMC_Temperatur_092, data-constr=DC_BMC_CMC_Temperatur_092, unit=Unit_Unit_DegreCelsi, transfer-property=PENDING  # Temperatur Zellmodul fuer die Uebertragung per RTM
          signal BMC_CMC_Temperatur_093_XIX_BMC_CMC_Temperatur_03_XIX_HCP5_CANFD01: start 176, 8 bit, little-endian, data-type-policy=OVERRIDE, i-signal-type=PRIMITIVE, init-value=254, base-type=BT_BMC_CMC_Temperatur_093, invalid-value=Invalid_BMC_CMC_Temperatur_093_XIX_BMC_CMC_Temperatur_03_XIX_HCP5_CANFD01:255, compu-method=CM_BMC_CMC_Temperatur_093, data-constr=DC_BMC_CMC_Temperatur_093, unit=Unit_Unit_DegreCelsi, transfer-property=PENDING  # Temperatur Zellmodul fuer die Uebertragung per RTM
          signal BMC_CMC_Temperatur_094_XIX_BMC_CMC_Temperatur_03_XIX_HCP5_CANFD01: start 184, 8 bit, little-endian, data-type-policy=OVERRIDE, i-signal-type=PRIMITIVE, init-value=254, base-type=BT_BMC_CMC_Temperatur_094, invalid-value=Invalid_BMC_CMC_Temperatur_094_XIX_BMC_CMC_Temperatur_03_XIX_HCP5_CANFD01:255, compu-method=CM_BMC_CMC_Temperatur_094, data-constr=DC_BMC_CMC_Temperatur_094, unit=Unit_Unit_DegreCelsi, transfer-property=PENDING  # Temperatur Zellmodul fuer die Uebertragung per RTM
          signal BMC_CMC_Temperatur_095_XIX_BMC_CMC_Temperatur_03_XIX_HCP5_CANFD01: start 192, 8 bit, little-endian, data-type-policy=OVERRIDE, i-signal-type=PRIMITIVE, init-value=254, base-type=BT_BMC_CMC_Temperatur_095, invalid-value=Invalid_BMC_CMC_Temperatur_095_XIX_BMC_CMC_Temperatur_03_XIX_HCP5_CANFD01:255, compu-method=CM_BMC_CMC_Temperatur_095, data-constr=DC_BMC_CMC_Temperatur_095, unit=Unit_Unit_DegreCelsi, transfer-property=PENDING  # Temperatur Zellmodul fuer die Uebertragung per RTM
          signal BMC_CMC_Temperatur_096_XIX_BMC_CMC_Temperatur_03_XIX_HCP5_CANFD01: start 200, 8 bit, little-endian, data-type-policy=OVERRIDE, i-signal-type=PRIMITIVE, init-value=254, base-type=BT_BMC_CMC_Temperatur_096, invalid-value=Invalid_BMC_CMC_Temperatur_096_XIX_BMC_CMC_Temperatur_03_XIX_HCP5_CANFD01:255, compu-method=CM_BMC_CMC_Temperatur_096, data-constr=DC_BMC_CMC_Temperatur_096, unit=Unit_Unit_DegreCelsi, transfer-property=PENDING  # Temperatur Zellmodul fuer die Uebertragung per RTM
          signal BMC_CMC_Temperatur_03_Messzeit_XIX_BMC_CMC_Temperatur_03_XIX_HCP5_CANFD01: start 480, 8 bit, little-endian, data-type-policy=OVERRIDE, i-signal-type=PRIMITIVE, init-value=254, base-type=BT_BMC_CMC_Temperatur_03_Messzeit, invalid-value=Invalid_BMC_CMC_Temperatur_03_Messzeit_XIX_BMC_CMC_Temperatur_03_XIX_HCP5_CANFD01:255, compu-method=CM_BMC_CMC_Temperatur_03_Messzeit, data-constr=DC_BMC_CMC_Temperatur_03_Messzeit, unit=Unit_Unit_None, transfer-property=PENDING  # Messzeit zu Botschaft BMC_CMC_Temperatur_03
      frame BMC_CMC_Zellspannung_01_XIX_HCP5_CANFD01: id 0x1A55562C, from BMC_HV, frame-length=64, can-addressing-mode=EXTENDED, can-frame-rx-behavior=CAN-FD, can-frame-tx-behavior=CAN-FD
        pdu BMC_CMC_Zellspannung_01_XIX_HCP5_CANFD01: length=64, transmission-mode-true-timing=cyclic-timing={time-offset=0, time-period=1}, unused-bit-pattern=0
          signal BMC_CMC_Zellspannung_001_XIX_BMC_CMC_Zellspannung_01_XIX_HCP5_CANFD01: start 12, 12 bit, little-endian, data-type-policy=OVERRIDE, i-signal-type=PRIMITIVE, init-value=4094, base-type=BT_BMC_CMC_Zellspannung_001, invalid-value=Invalid_BMC_CMC_Zellspannung_001_XIX_BMC_CMC_Zellspannung_01_XIX_HCP5_CANFD01:4095, compu-method=CM_BMC_CMC_Zellspannung_001, data-constr=DC_BMC_CMC_Zellspannung_001, unit=Unit_Unit_MilliVolt, transfer-property=PENDING  # Einzelzellspannung zur Uebertragung per RTM
          signal BMC_CMC_Zellspannung_002_XIX_BMC_CMC_Zellspannung_01_XIX_HCP5_CANFD01: start 24, 12 bit, little-endian, data-type-policy=OVERRIDE, i-signal-type=PRIMITIVE, init-value=4094, base-type=BT_BMC_CMC_Zellspannung_002, invalid-value=Invalid_BMC_CMC_Zellspannung_002_XIX_BMC_CMC_Zellspannung_01_XIX_HCP5_CANFD01:4095, compu-method=CM_BMC_CMC_Zellspannung_002, data-constr=DC_BMC_CMC_Zellspannung_002, unit=Unit_Unit_MilliVolt, transfer-property=PENDING  # Einzelzellspannung zur Uebertragung per RTM
          signal BMC_CMC_Zellspannung_003_XIX_BMC_CMC_Zellspannung_01_XIX_HCP5_CANFD01: start 36, 12 bit, little-endian, data-type-policy=OVERRIDE, i-signal-type=PRIMITIVE, init-value=4094, base-type=BT_BMC_CMC_Zellspannung_003, invalid-value=Invalid_BMC_CMC_Zellspannung_003_XIX_BMC_CMC_Zellspannung_01_XIX_HCP5_CANFD01:4095, compu-method=CM_BMC_CMC_Zellspannung_003, data-constr=DC_BMC_CMC_Zellspannung_003, unit=Unit_Unit_MilliVolt, transfer-property=PENDING  # Einzelzellspannung zur Uebertragung per RTM
          signal BMC_CMC_Zellspannung_004_XIX_BMC_CMC_Zellspannung_01_XIX_HCP5_CANFD01: start 48, 12 bit, little-endian, data-type-policy=OVERRIDE, i-signal-type=PRIMITIVE, init-value=4094, base-type=BT_BMC_CMC_Zellspannung_004, invalid-value=Invalid_BMC_CMC_Zellspannung_004_XIX_BMC_CMC_Zellspannung_01_XIX_HCP5_CANFD01:4095, compu-method=CM_BMC_CMC_Zellspannung_004, data-constr=DC_BMC_CMC_Zellspannung_004, unit=Unit_Unit_MilliVolt, transfer-property=PENDING  # Einzelzellspannung zur Uebertragung per RTM
          signal BMC_CMC_Zellspannung_005_XIX_BMC_CMC_Zellspannung_01_XIX_HCP5_CANFD01: start 60, 12 bit, little-endian, data-type-policy=OVERRIDE, i-signal-type=PRIMITIVE, init-value=4094, base-type=BT_BMC_CMC_Zellspannung_005, invalid-value=Invalid_BMC_CMC_Zellspannung_005_XIX_BMC_CMC_Zellspannung_01_XIX_HCP5_CANFD01:4095, compu-method=CM_BMC_CMC_Zellspannung_005, data-constr=DC_BMC_CMC_Zellspannung_005, unit=Unit_Unit_MilliVolt, transfer-property=PENDING  # Einzelzellspannung zur Uebertragung per RTM
          signal BMC_CMC_Zellspannung_006_XIX_BMC_CMC_Zellspannung_01_XIX_HCP5_CANFD01: start 72, 12 bit, little-endian, data-type-policy=OVERRIDE, i-signal-type=PRIMITIVE, init-value=4094, base-type=BT_BMC_CMC_Zellspannung_006, invalid-value=Invalid_BMC_CMC_Zellspannung_006_XIX_BMC_CMC_Zellspannung_01_XIX_HCP5_CANFD01:4095, compu-method=CM_BMC_CMC_Zellspannung_006, data-constr=DC_BMC_CMC_Zellspannung_006, unit=Unit_Unit_MilliVolt, transfer-property=PENDING  # Einzelzellspannung zur Uebertragung per RTM
          signal BMC_CMC_Zellspannung_007_XIX_BMC_CMC_Zellspannung_01_XIX_HCP5_CANFD01: start 84, 12 bit, little-endian, data-type-policy=OVERRIDE, i-signal-type=PRIMITIVE, init-value=4094, base-type=BT_BMC_CMC_Zellspannung_007, invalid-value=Invalid_BMC_CMC_Zellspannung_007_XIX_BMC_CMC_Zellspannung_01_XIX_HCP5_CANFD01:4095, compu-method=CM_BMC_CMC_Zellspannung_007, data-constr=DC_BMC_CMC_Zellspannung_007, unit=Unit_Unit_MilliVolt, transfer-property=PENDING  # Einzelzellspannung zur Uebertragung per RTM
          signal BMC_CMC_Zellspannung_008_XIX_BMC_CMC_Zellspannung_01_XIX_HCP5_CANFD01: start 96, 12 bit, little-endian, data-type-policy=OVERRIDE, i-signal-type=PRIMITIVE, init-value=4094, base-type=BT_BMC_CMC_Zellspannung_008, invalid-value=Invalid_BMC_CMC_Zellspannung_008_XIX_BMC_CMC_Zellspannung_01_XIX_HCP5_CANFD01:4095, compu-method=CM_BMC_CMC_Zellspannung_008, data-constr=DC_BMC_CMC_Zellspannung_008, unit=Unit_Unit_MilliVolt, transfer-property=PENDING  # Einzelzellspannung zur Uebertragung per RTM
          signal BMC_CMC_Zellspannung_009_XIX_BMC_CMC_Zellspannung_01_XIX_HCP5_CANFD01: start 108, 12 bit, little-endian, data-type-policy=OVERRIDE, i-signal-type=PRIMITIVE, init-value=4094, base-type=BT_BMC_CMC_Zellspannung_009, invalid-value=Invalid_BMC_CMC_Zellspannung_009_XIX_BMC_CMC_Zellspannung_01_XIX_HCP5_CANFD01:4095, compu-method=CM_BMC_CMC_Zellspannung_009, data-constr=DC_BMC_CMC_Zellspannung_009, unit=Unit_Unit_MilliVolt, transfer-property=PENDING  # Einzelzellspannung zur Uebertragung per RTM
          signal BMC_CMC_Zellspannung_010_XIX_BMC_CMC_Zellspannung_01_XIX_HCP5_CANFD01: start 120, 12 bit, little-endian, data-type-policy=OVERRIDE, i-signal-type=PRIMITIVE, init-value=4094, base-type=BT_BMC_CMC_Zellspannung_010, invalid-value=Invalid_BMC_CMC_Zellspannung_010_XIX_BMC_CMC_Zellspannung_01_XIX_HCP5_CANFD01:4095, compu-method=CM_BMC_CMC_Zellspannung_010, data-constr=DC_BMC_CMC_Zellspannung_010, unit=Unit_Unit_MilliVolt, transfer-property=PENDING  # Einzelzellspannung zur Uebertragung per RTM
          signal BMC_CMC_Zellspannung_011_XIX_BMC_CMC_Zellspannung_01_XIX_HCP5_CANFD01: start 132, 12 bit, little-endian, data-type-policy=OVERRIDE, i-signal-type=PRIMITIVE, init-value=4094, base-type=BT_BMC_CMC_Zellspannung_011, invalid-value=Invalid_BMC_CMC_Zellspannung_011_XIX_BMC_CMC_Zellspannung_01_XIX_HCP5_CANFD01:4095, compu-method=CM_BMC_CMC_Zellspannung_011, data-constr=DC_BMC_CMC_Zellspannung_011, unit=Unit_Unit_MilliVolt, transfer-property=PENDING  # Einzelzellspannung zur Uebertragung per RTM
          signal BMC_CMC_Zellspannung_012_XIX_BMC_CMC_Zellspannung_01_XIX_HCP5_CANFD01: start 144, 12 bit, little-endian, data-type-policy=OVERRIDE, i-signal-type=PRIMITIVE, init-value=4094, base-type=BT_BMC_CMC_Zellspannung_012, invalid-value=Invalid_BMC_CMC_Zellspannung_012_XIX_BMC_CMC_Zellspannung_01_XIX_HCP5_CANFD01:4095, compu-method=CM_BMC_CMC_Zellspannung_012, data-constr=DC_BMC_CMC_Zellspannung_012, unit=Unit_Unit_MilliVolt, transfer-property=PENDING  # Einzelzellspannung zur Uebertragung per RTM
          signal BMC_CMC_Zellspannung_013_XIX_BMC_CMC_Zellspannung_01_XIX_HCP5_CANFD01: start 156, 12 bit, little-endian, data-type-policy=OVERRIDE, i-signal-type=PRIMITIVE, init-value=4094, base-type=BT_BMC_CMC_Zellspannung_013, invalid-value=Invalid_BMC_CMC_Zellspannung_013_XIX_BMC_CMC_Zellspannung_01_XIX_HCP5_CANFD01:4095, compu-method=CM_BMC_CMC_Zellspannung_013, data-constr=DC_BMC_CMC_Zellspannung_013, unit=Unit_Unit_MilliVolt, transfer-property=PENDING  # Einzelzellspannung zur Uebertragung per RTM
          signal BMC_CMC_Zellspannung_014_XIX_BMC_CMC_Zellspannung_01_XIX_HCP5_CANFD01: start 168, 12 bit, little-endian, data-type-policy=OVERRIDE, i-signal-type=PRIMITIVE, init-value=4094, base-type=BT_BMC_CMC_Zellspannung_014, invalid-value=Invalid_BMC_CMC_Zellspannung_014_XIX_BMC_CMC_Zellspannung_01_XIX_HCP5_CANFD01:4095, compu-method=CM_BMC_CMC_Zellspannung_014, data-constr=DC_BMC_CMC_Zellspannung_014, unit=Unit_Unit_MilliVolt, transfer-property=PENDING  # Einzelzellspannung zur Uebertragung per RTM
          signal BMC_CMC_Zellspannung_015_XIX_BMC_CMC_Zellspannung_01_XIX_HCP5_CANFD01: start 180, 12 bit, little-endian, data-type-policy=OVERRIDE, i-signal-type=PRIMITIVE, init-value=4094, base-type=BT_BMC_CMC_Zellspannung_015, invalid-value=Invalid_BMC_CMC_Zellspannung_015_XIX_BMC_CMC_Zellspannung_01_XIX_HCP5_CANFD01:4095, compu-method=CM_BMC_CMC_Zellspannung_015, data-constr=DC_BMC_CMC_Zellspannung_015, unit=Unit_Unit_MilliVolt, transfer-property=PENDING  # Einzelzellspannung zur Uebertragung per RTM
          signal BMC_CMC_Zellspannung_016_XIX_BMC_CMC_Zellspannung_01_XIX_HCP5_CANFD01: start 192, 12 bit, little-endian, data-type-policy=OVERRIDE, i-signal-type=PRIMITIVE, init-value=4094, base-type=BT_BMC_CMC_Zellspannung_016, invalid-value=Invalid_BMC_CMC_Zellspannung_016_XIX_BMC_CMC_Zellspannung_01_XIX_HCP5_CANFD01:4095, compu-method=CM_BMC_CMC_Zellspannung_016, data-constr=DC_BMC_CMC_Zellspannung_016, unit=Unit_Unit_MilliVolt, transfer-property=PENDING  # Einzelzellspannung zur Uebertragung per RTM
          signal BMC_CMC_Zellspannung_017_XIX_BMC_CMC_Zellspannung_01_XIX_HCP5_CANFD01: start 204, 12 bit, little-endian, data-type-policy=OVERRIDE, i-signal-type=PRIMITIVE, init-value=4094, base-type=BT_BMC_CMC_Zellspannung_017, invalid-value=Invalid_BMC_CMC_Zellspannung_017_XIX_BMC_CMC_Zellspannung_01_XIX_HCP5_CANFD01:4095, compu-method=CM_BMC_CMC_Zellspannung_017, data-constr=DC_BMC_CMC_Zellspannung_017, unit=Unit_Unit_MilliVolt, transfer-property=PENDING  # Einzelzellspannung zur Uebertragung per RTM
          signal BMC_CMC_Zellspannung_018_XIX_BMC_CMC_Zellspannung_01_XIX_HCP5_CANFD01: start 216, 12 bit, little-endian, data-type-policy=OVERRIDE, i-signal-type=PRIMITIVE, init-value=4094, base-type=BT_BMC_CMC_Zellspannung_018, invalid-value=Invalid_BMC_CMC_Zellspannung_018_XIX_BMC_CMC_Zellspannung_01_XIX_HCP5_CANFD01:4095, compu-method=CM_BMC_CMC_Zellspannung_018, data-constr=DC_BMC_CMC_Zellspannung_018, unit=Unit_Unit_MilliVolt, transfer-property=PENDING  # Einzelzellspannung zur Uebertragung per RTM
          signal BMC_CMC_Zellspannung_019_XIX_BMC_CMC_Zellspannung_01_XIX_HCP5_CANFD01: start 228, 12 bit, little-endian, data-type-policy=OVERRIDE, i-signal-type=PRIMITIVE, init-value=4094, base-type=BT_BMC_CMC_Zellspannung_019, invalid-value=Invalid_BMC_CMC_Zellspannung_019_XIX_BMC_CMC_Zellspannung_01_XIX_HCP5_CANFD01:4095, compu-method=CM_BMC_CMC_Zellspannung_019, data-constr=DC_BMC_CMC_Zellspannung_019, unit=Unit_Unit_MilliVolt, transfer-property=PENDING  # Einzelzellspannung zur Uebertragung per RTM
          signal BMC_CMC_Zellspannung_020_XIX_BMC_CMC_Zellspannung_01_XIX_HCP5_CANFD01: start 240, 12 bit, little-endian, data-type-policy=OVERRIDE, i-signal-type=PRIMITIVE, init-value=4094, base-type=BT_BMC_CMC_Zellspannung_020, invalid-value=Invalid_BMC_CMC_Zellspannung_020_XIX_BMC_CMC_Zellspannung_01_XIX_HCP5_CANFD01:4095, compu-method=CM_BMC_CMC_Zellspannung_020, data-constr=DC_BMC_CMC_Zellspannung_020, unit=Unit_Unit_MilliVolt, transfer-property=PENDING  # Einzelzellspannung zur Uebertragung per RTM
          signal BMC_CMC_Zellspannung_021_XIX_BMC_CMC_Zellspannung_01_XIX_HCP5_CANFD01: start 252, 12 bit, little-endian, data-type-policy=OVERRIDE, i-signal-type=PRIMITIVE, init-value=4094, base-type=BT_BMC_CMC_Zellspannung_021, invalid-value=Invalid_BMC_CMC_Zellspannung_021_XIX_BMC_CMC_Zellspannung_01_XIX_HCP5_CANFD01:4095, compu-method=CM_BMC_CMC_Zellspannung_021, data-constr=DC_BMC_CMC_Zellspannung_021, unit=Unit_Unit_MilliVolt, transfer-property=PENDING  # Einzelzellspannung zur Uebertragung per RTM
          signal BMC_CMC_Zellspannung_022_XIX_BMC_CMC_Zellspannung_01_XIX_HCP5_CANFD01: start 264, 12 bit, little-endian, data-type-policy=OVERRIDE, i-signal-type=PRIMITIVE, init-value=4094, base-type=BT_BMC_CMC_Zellspannung_022, invalid-value=Invalid_BMC_CMC_Zellspannung_022_XIX_BMC_CMC_Zellspannung_01_XIX_HCP5_CANFD01:4095, compu-method=CM_BMC_CMC_Zellspannung_022, data-constr=DC_BMC_CMC_Zellspannung_022, unit=Unit_Unit_MilliVolt, transfer-property=PENDING  # Einzelzellspannung zur Uebertragung per RTM
          signal BMC_CMC_Zellspannung_023_XIX_BMC_CMC_Zellspannung_01_XIX_HCP5_CANFD01: start 276, 12 bit, little-endian, data-type-policy=OVERRIDE, i-signal-type=PRIMITIVE, init-value=4094, base-type=BT_BMC_CMC_Zellspannung_023, invalid-value=Invalid_BMC_CMC_Zellspannung_023_XIX_BMC_CMC_Zellspannung_01_XIX_HCP5_CANFD01:4095, compu-method=CM_BMC_CMC_Zellspannung_023, data-constr=DC_BMC_CMC_Zellspannung_023, unit=Unit_Unit_MilliVolt, transfer-property=PENDING  # Einzelzellspannung zur Uebertragung per RTM
          signal BMC_CMC_Zellspannung_024_XIX_BMC_CMC_Zellspannung_01_XIX_HCP5_CANFD01: start 288, 12 bit, little-endian, data-type-policy=OVERRIDE, i-signal-type=PRIMITIVE, init-value=4094, base-type=BT_BMC_CMC_Zellspannung_024, invalid-value=Invalid_BMC_CMC_Zellspannung_024_XIX_BMC_CMC_Zellspannung_01_XIX_HCP5_CANFD01:4095, compu-method=CM_BMC_CMC_Zellspannung_024, data-constr=DC_BMC_CMC_Zellspannung_024, unit=Unit_Unit_MilliVolt, transfer-property=PENDING  # Einzelzellspannung zur Uebertragung per RTM
          signal BMC_CMC_Zellspannung_025_XIX_BMC_CMC_Zellspannung_01_XIX_HCP5_CANFD01: start 300, 12 bit, little-endian, data-type-policy=OVERRIDE, i-signal-type=PRIMITIVE, init-value=4094, base-type=BT_BMC_CMC_Zellspannung_025, invalid-value=Invalid_BMC_CMC_Zellspannung_025_XIX_BMC_CMC_Zellspannung_01_XIX_HCP5_CANFD01:4095, compu-method=CM_BMC_CMC_Zellspannung_025, data-constr=DC_BMC_CMC_Zellspannung_025, unit=Unit_Unit_MilliVolt, transfer-property=PENDING  # Einzelzellspannung zur Uebertragung per RTM
          signal BMC_CMC_Zellspannung_026_XIX_BMC_CMC_Zellspannung_01_XIX_HCP5_CANFD01: start 312, 12 bit, little-endian, data-type-policy=OVERRIDE, i-signal-type=PRIMITIVE, init-value=4094, base-type=BT_BMC_CMC_Zellspannung_026, invalid-value=Invalid_BMC_CMC_Zellspannung_026_XIX_BMC_CMC_Zellspannung_01_XIX_HCP5_CANFD01:4095, compu-method=CM_BMC_CMC_Zellspannung_026, data-constr=DC_BMC_CMC_Zellspannung_026, unit=Unit_Unit_MilliVolt, transfer-property=PENDING  # Einzelzellspannung zur Uebertragung per RTM
          signal BMC_CMC_Zellspannung_027_XIX_BMC_CMC_Zellspannung_01_XIX_HCP5_CANFD01: start 324, 12 bit, little-endian, data-type-policy=OVERRIDE, i-signal-type=PRIMITIVE, init-value=4094, base-type=BT_BMC_CMC_Zellspannung_027, invalid-value=Invalid_BMC_CMC_Zellspannung_027_XIX_BMC_CMC_Zellspannung_01_XIX_HCP5_CANFD01:4095, compu-method=CM_BMC_CMC_Zellspannung_027, data-constr=DC_BMC_CMC_Zellspannung_027, unit=Unit_Unit_MilliVolt, transfer-property=PENDING  # Einzelzellspannung zur Uebertragung per RTM
          signal BMC_CMC_Zellspannung_028_XIX_BMC_CMC_Zellspannung_01_XIX_HCP5_CANFD01: start 336, 12 bit, little-endian, data-type-policy=OVERRIDE, i-signal-type=PRIMITIVE, init-value=4094, base-type=BT_BMC_CMC_Zellspannung_028, invalid-value=Invalid_BMC_CMC_Zellspannung_028_XIX_BMC_CMC_Zellspannung_01_XIX_HCP5_CANFD01:4095, compu-method=CM_BMC_CMC_Zellspannung_028, data-constr=DC_BMC_CMC_Zellspannung_028, unit=Unit_Unit_MilliVolt, transfer-property=PENDING  # Einzelzellspannung zur Uebertragung per RTM
          signal BMC_CMC_Zellspannung_029_XIX_BMC_CMC_Zellspannung_01_XIX_HCP5_CANFD01: start 348, 12 bit, little-endian, data-type-policy=OVERRIDE, i-signal-type=PRIMITIVE, init-value=4094, base-type=BT_BMC_CMC_Zellspannung_029, invalid-value=Invalid_BMC_CMC_Zellspannung_029_XIX_BMC_CMC_Zellspannung_01_XIX_HCP5_CANFD01:4095, compu-method=CM_BMC_CMC_Zellspannung_029, data-constr=DC_BMC_CMC_Zellspannung_029, unit=Unit_Unit_MilliVolt, transfer-property=PENDING  # Einzelzellspannung zur Uebertragung per RTM
          signal BMC_CMC_Zellspannung_030_XIX_BMC_CMC_Zellspannung_01_XIX_HCP5_CANFD01: start 360, 12 bit, little-endian, data-type-policy=OVERRIDE, i-signal-type=PRIMITIVE, init-value=4094, base-type=BT_BMC_CMC_Zellspannung_030, invalid-value=Invalid_BMC_CMC_Zellspannung_030_XIX_BMC_CMC_Zellspannung_01_XIX_HCP5_CANFD01:4095, compu-method=CM_BMC_CMC_Zellspannung_030, data-constr=DC_BMC_CMC_Zellspannung_030, unit=Unit_Unit_MilliVolt, transfer-property=PENDING  # Einzelzellspannung zur Uebertragung per RTM
          signal BMC_CMC_Zellspannung_031_XIX_BMC_CMC_Zellspannung_01_XIX_HCP5_CANFD01: start 372, 12 bit, little-endian, data-type-policy=OVERRIDE, i-signal-type=PRIMITIVE, init-value=4094, base-type=BT_BMC_CMC_Zellspannung_031, invalid-value=Invalid_BMC_CMC_Zellspannung_031_XIX_BMC_CMC_Zellspannung_01_XIX_HCP5_CANFD01:4095, compu-method=CM_BMC_CMC_Zellspannung_031, data-constr=DC_BMC_CMC_Zellspannung_031, unit=Unit_Unit_MilliVolt, transfer-property=PENDING  # Einzelzellspannung zur Uebertragung per RTM
          signal BMC_CMC_Zellspannung_032_XIX_BMC_CMC_Zellspannung_01_XIX_HCP5_CANFD01: start 384, 12 bit, little-endian, data-type-policy=OVERRIDE, i-signal-type=PRIMITIVE, init-value=4094, base-type=BT_BMC_CMC_Zellspannung_032, invalid-value=Invalid_BMC_CMC_Zellspannung_032_XIX_BMC_CMC_Zellspannung_01_XIX_HCP5_CANFD01:4095, compu-method=CM_BMC_CMC_Zellspannung_032, data-constr=DC_BMC_CMC_Zellspannung_032, unit=Unit_Unit_MilliVolt, transfer-property=PENDING  # Einzelzellspannung zur Uebertragung per RTM
          signal BMC_CMC_Zellspannung_033_XIX_BMC_CMC_Zellspannung_01_XIX_HCP5_CANFD01: start 396, 12 bit, little-endian, data-type-policy=OVERRIDE, i-signal-type=PRIMITIVE, init-value=4094, base-type=BT_BMC_CMC_Zellspannung_033, invalid-value=Invalid_BMC_CMC_Zellspannung_033_XIX_BMC_CMC_Zellspannung_01_XIX_HCP5_CANFD01:4095, compu-method=CM_BMC_CMC_Zellspannung_033, data-constr=DC_BMC_CMC_Zellspannung_033, unit=Unit_Unit_MilliVolt, transfer-property=PENDING  # Einzelzellspannung zur Uebertragung per RTM
          signal BMC_CMC_Zellspannung_034_XIX_BMC_CMC_Zellspannung_01_XIX_HCP5_CANFD01: start 408, 12 bit, little-endian, data-type-policy=OVERRIDE, i-signal-type=PRIMITIVE, init-value=4094, base-type=BT_BMC_CMC_Zellspannung_034, invalid-value=Invalid_BMC_CMC_Zellspannung_034_XIX_BMC_CMC_Zellspannung_01_XIX_HCP5_CANFD01:4095, compu-method=CM_BMC_CMC_Zellspannung_034, data-constr=DC_BMC_CMC_Zellspannung_034, unit=Unit_Unit_MilliVolt, transfer-property=PENDING  # Einzelzellspannung zur Uebertragung per RTM
          signal BMC_CMC_Zellspannung_035_XIX_BMC_CMC_Zellspannung_01_XIX_HCP5_CANFD01: start 420, 12 bit, little-endian, data-type-policy=OVERRIDE, i-signal-type=PRIMITIVE, init-value=4094, base-type=BT_BMC_CMC_Zellspannung_035, invalid-value=Invalid_BMC_CMC_Zellspannung_035_XIX_BMC_CMC_Zellspannung_01_XIX_HCP5_CANFD01:4095, compu-method=CM_BMC_CMC_Zellspannung_035, data-constr=DC_BMC_CMC_Zellspannung_035, unit=Unit_Unit_MilliVolt, transfer-property=PENDING  # Einzelzellspannung zur Uebertragung per RTM
          signal BMC_CMC_Zellspannung_036_XIX_BMC_CMC_Zellspannung_01_XIX_HCP5_CANFD01: start 432, 12 bit, little-endian, data-type-policy=OVERRIDE, i-signal-type=PRIMITIVE, init-value=4094, base-type=BT_BMC_CMC_Zellspannung_036, invalid-value=Invalid_BMC_CMC_Zellspannung_036_XIX_BMC_CMC_Zellspannung_01_XIX_HCP5_CANFD01:4095, compu-method=CM_BMC_CMC_Zellspannung_036, data-constr=DC_BMC_CMC_Zellspannung_036, unit=Unit_Unit_MilliVolt, transfer-property=PENDING  # Einzelzellspannung zur Uebertragung per RTM
          signal BMC_CMC_Zellspannung_037_XIX_BMC_CMC_Zellspannung_01_XIX_HCP5_CANFD01: start 444, 12 bit, little-endian, data-type-policy=OVERRIDE, i-signal-type=PRIMITIVE, init-value=4094, base-type=BT_BMC_CMC_Zellspannung_037, invalid-value=Invalid_BMC_CMC_Zellspannung_037_XIX_BMC_CMC_Zellspannung_01_XIX_HCP5_CANFD01:4095, compu-method=CM_BMC_CMC_Zellspannung_037, data-constr=DC_BMC_CMC_Zellspannung_037, unit=Unit_Unit_MilliVolt, transfer-property=PENDING  # Einzelzellspannung zur Uebertragung per RTM
          signal BMC_CMC_Zellspannung_038_XIX_BMC_CMC_Zellspannung_01_XIX_HCP5_CANFD01: start 456, 12 bit, little-endian, data-type-policy=OVERRIDE, i-signal-type=PRIMITIVE, init-value=4094, base-type=BT_BMC_CMC_Zellspannung_038, invalid-value=Invalid_BMC_CMC_Zellspannung_038_XIX_BMC_CMC_Zellspannung_01_XIX_HCP5_CANFD01:4095, compu-method=CM_BMC_CMC_Zellspannung_038, data-constr=DC_BMC_CMC_Zellspannung_038, unit=Unit_Unit_MilliVolt, transfer-property=PENDING  # Einzelzellspannung zur Uebertragung per RTM
          signal BMC_CMC_Zellspannung_039_XIX_BMC_CMC_Zellspannung_01_XIX_HCP5_CANFD01: start 468, 12 bit, little-endian, data-type-policy=OVERRIDE, i-signal-type=PRIMITIVE, init-value=4094, base-type=BT_BMC_CMC_Zellspannung_039, invalid-value=Invalid_BMC_CMC_Zellspannung_039_XIX_BMC_CMC_Zellspannung_01_XIX_HCP5_CANFD01:4095, compu-method=CM_BMC_CMC_Zellspannung_039, data-constr=DC_BMC_CMC_Zellspannung_039, unit=Unit_Unit_MilliVolt, transfer-property=PENDING  # Einzelzellspannung zur Uebertragung per RTM
          signal BMC_CMC_Zellspannung_01_Messzeit_XIX_BMC_CMC_Zellspannung_01_XIX_HCP5_CANFD01: start 480, 8 bit, little-endian, data-type-policy=OVERRIDE, i-signal-type=PRIMITIVE, init-value=254, base-type=BT_BMC_CMC_Zellspannung_01_Messzeit, invalid-value=Invalid_BMC_CMC_Zellspannung_01_Messzeit_XIX_BMC_CMC_Zellspannung_01_XIX_HCP5_CANFD01:255, compu-method=CM_BMC_CMC_Zellspannung_01_Messzeit, data-constr=DC_BMC_CMC_Zellspannung_01_Messzeit, unit=Unit_Unit_None, transfer-property=PENDING  # Messzeit zu Botschaft BMC_CMC_Zellspannung_01
      frame BMC_CMC_Zellspannung_02_XIX_HCP5_CANFD01: id 0x1A55562D, from BMC_HV, frame-length=64, can-addressing-mode=EXTENDED, can-frame-rx-behavior=CAN-FD, can-frame-tx-behavior=CAN-FD
        pdu BMC_CMC_Zellspannung_02_XIX_HCP5_CANFD01: length=64, transmission-mode-true-timing=cyclic-timing={time-offset=0, time-period=1}, unused-bit-pattern=0
          signal BMC_CMC_Zellspannung_040_XIX_BMC_CMC_Zellspannung_02_XIX_HCP5_CANFD01: start 12, 12 bit, little-endian, data-type-policy=OVERRIDE, i-signal-type=PRIMITIVE, init-value=4094, base-type=BT_BMC_CMC_Zellspannung_040, invalid-value=Invalid_BMC_CMC_Zellspannung_040_XIX_BMC_CMC_Zellspannung_02_XIX_HCP5_CANFD01:4095, compu-method=CM_BMC_CMC_Zellspannung_040, data-constr=DC_BMC_CMC_Zellspannung_040, unit=Unit_Unit_MilliVolt, transfer-property=PENDING  # Einzelzellspannung zur Uebertragung per RTM
          signal BMC_CMC_Zellspannung_041_XIX_BMC_CMC_Zellspannung_02_XIX_HCP5_CANFD01: start 24, 12 bit, little-endian, data-type-policy=OVERRIDE, i-signal-type=PRIMITIVE, init-value=4094, base-type=BT_BMC_CMC_Zellspannung_041, invalid-value=Invalid_BMC_CMC_Zellspannung_041_XIX_BMC_CMC_Zellspannung_02_XIX_HCP5_CANFD01:4095, compu-method=CM_BMC_CMC_Zellspannung_041, data-constr=DC_BMC_CMC_Zellspannung_041, unit=Unit_Unit_MilliVolt, transfer-property=PENDING  # Einzelzellspannung zur Uebertragung per RTM
          signal BMC_CMC_Zellspannung_042_XIX_BMC_CMC_Zellspannung_02_XIX_HCP5_CANFD01: start 36, 12 bit, little-endian, data-type-policy=OVERRIDE, i-signal-type=PRIMITIVE, init-value=4094, base-type=BT_BMC_CMC_Zellspannung_042, invalid-value=Invalid_BMC_CMC_Zellspannung_042_XIX_BMC_CMC_Zellspannung_02_XIX_HCP5_CANFD01:4095, compu-method=CM_BMC_CMC_Zellspannung_042, data-constr=DC_BMC_CMC_Zellspannung_042, unit=Unit_Unit_MilliVolt, transfer-property=PENDING  # Einzelzellspannung zur Uebertragung per RTM
          signal BMC_CMC_Zellspannung_043_XIX_BMC_CMC_Zellspannung_02_XIX_HCP5_CANFD01: start 48, 12 bit, little-endian, data-type-policy=OVERRIDE, i-signal-type=PRIMITIVE, init-value=4094, base-type=BT_BMC_CMC_Zellspannung_043, invalid-value=Invalid_BMC_CMC_Zellspannung_043_XIX_BMC_CMC_Zellspannung_02_XIX_HCP5_CANFD01:4095, compu-method=CM_BMC_CMC_Zellspannung_043, data-constr=DC_BMC_CMC_Zellspannung_043, unit=Unit_Unit_MilliVolt, transfer-property=PENDING  # Einzelzellspannung zur Uebertragung per RTM
          signal BMC_CMC_Zellspannung_044_XIX_BMC_CMC_Zellspannung_02_XIX_HCP5_CANFD01: start 60, 12 bit, little-endian, data-type-policy=OVERRIDE, i-signal-type=PRIMITIVE, init-value=4094, base-type=BT_BMC_CMC_Zellspannung_044, invalid-value=Invalid_BMC_CMC_Zellspannung_044_XIX_BMC_CMC_Zellspannung_02_XIX_HCP5_CANFD01:4095, compu-method=CM_BMC_CMC_Zellspannung_044, data-constr=DC_BMC_CMC_Zellspannung_044, unit=Unit_Unit_MilliVolt, transfer-property=PENDING  # Einzelzellspannung zur Uebertragung per RTM
          signal BMC_CMC_Zellspannung_045_XIX_BMC_CMC_Zellspannung_02_XIX_HCP5_CANFD01: start 72, 12 bit, little-endian, data-type-policy=OVERRIDE, i-signal-type=PRIMITIVE, init-value=4094, base-type=BT_BMC_CMC_Zellspannung_045, invalid-value=Invalid_BMC_CMC_Zellspannung_045_XIX_BMC_CMC_Zellspannung_02_XIX_HCP5_CANFD01:4095, compu-method=CM_BMC_CMC_Zellspannung_045, data-constr=DC_BMC_CMC_Zellspannung_045, unit=Unit_Unit_MilliVolt, transfer-property=PENDING  # Einzelzellspannung zur Uebertragung per RTM
          signal BMC_CMC_Zellspannung_046_XIX_BMC_CMC_Zellspannung_02_XIX_HCP5_CANFD01: start 84, 12 bit, little-endian, data-type-policy=OVERRIDE, i-signal-type=PRIMITIVE, init-value=4094, base-type=BT_BMC_CMC_Zellspannung_046, invalid-value=Invalid_BMC_CMC_Zellspannung_046_XIX_BMC_CMC_Zellspannung_02_XIX_HCP5_CANFD01:4095, compu-method=CM_BMC_CMC_Zellspannung_046, data-constr=DC_BMC_CMC_Zellspannung_046, unit=Unit_Unit_MilliVolt, transfer-property=PENDING  # Einzelzellspannung zur Uebertragung per RTM
          signal BMC_CMC_Zellspannung_047_XIX_BMC_CMC_Zellspannung_02_XIX_HCP5_CANFD01: start 96, 12 bit, little-endian, data-type-policy=OVERRIDE, i-signal-type=PRIMITIVE, init-value=4094, base-type=BT_BMC_CMC_Zellspannung_047, invalid-value=Invalid_BMC_CMC_Zellspannung_047_XIX_BMC_CMC_Zellspannung_02_XIX_HCP5_CANFD01:4095, compu-method=CM_BMC_CMC_Zellspannung_047, data-constr=DC_BMC_CMC_Zellspannung_047, unit=Unit_Unit_MilliVolt, transfer-property=PENDING  # Einzelzellspannung zur Uebertragung per RTM
          signal BMC_CMC_Zellspannung_048_XIX_BMC_CMC_Zellspannung_02_XIX_HCP5_CANFD01: start 108, 12 bit, little-endian, data-type-policy=OVERRIDE, i-signal-type=PRIMITIVE, init-value=4094, base-type=BT_BMC_CMC_Zellspannung_048, invalid-value=Invalid_BMC_CMC_Zellspannung_048_XIX_BMC_CMC_Zellspannung_02_XIX_HCP5_CANFD01:4095, compu-method=CM_BMC_CMC_Zellspannung_048, data-constr=DC_BMC_CMC_Zellspannung_048, unit=Unit_Unit_MilliVolt, transfer-property=PENDING  # Einzelzellspannung zur Uebertragung per RTM
          signal BMC_CMC_Zellspannung_049_XIX_BMC_CMC_Zellspannung_02_XIX_HCP5_CANFD01: start 120, 12 bit, little-endian, data-type-policy=OVERRIDE, i-signal-type=PRIMITIVE, init-value=4094, base-type=BT_BMC_CMC_Zellspannung_049, invalid-value=Invalid_BMC_CMC_Zellspannung_049_XIX_BMC_CMC_Zellspannung_02_XIX_HCP5_CANFD01:4095, compu-method=CM_BMC_CMC_Zellspannung_049, data-constr=DC_BMC_CMC_Zellspannung_049, unit=Unit_Unit_MilliVolt, transfer-property=PENDING  # Einzelzellspannung zur Uebertragung per RTM
          signal BMC_CMC_Zellspannung_050_XIX_BMC_CMC_Zellspannung_02_XIX_HCP5_CANFD01: start 132, 12 bit, little-endian, data-type-policy=OVERRIDE, i-signal-type=PRIMITIVE, init-value=4094, base-type=BT_BMC_CMC_Zellspannung_050, invalid-value=Invalid_BMC_CMC_Zellspannung_050_XIX_BMC_CMC_Zellspannung_02_XIX_HCP5_CANFD01:4095, compu-method=CM_BMC_CMC_Zellspannung_050, data-constr=DC_BMC_CMC_Zellspannung_050, unit=Unit_Unit_MilliVolt, transfer-property=PENDING  # Einzelzellspannung zur Uebertragung per RTM
          signal BMC_CMC_Zellspannung_051_XIX_BMC_CMC_Zellspannung_02_XIX_HCP5_CANFD01: start 144, 12 bit, little-endian, data-type-policy=OVERRIDE, i-signal-type=PRIMITIVE, init-value=4094, base-type=BT_BMC_CMC_Zellspannung_051, invalid-value=Invalid_BMC_CMC_Zellspannung_051_XIX_BMC_CMC_Zellspannung_02_XIX_HCP5_CANFD01:4095, compu-method=CM_BMC_CMC_Zellspannung_051, data-constr=DC_BMC_CMC_Zellspannung_051, unit=Unit_Unit_MilliVolt, transfer-property=PENDING  # Einzelzellspannung zur Uebertragung per RTM
          signal BMC_CMC_Zellspannung_052_XIX_BMC_CMC_Zellspannung_02_XIX_HCP5_CANFD01: start 156, 12 bit, little-endian, data-type-policy=OVERRIDE, i-signal-type=PRIMITIVE, init-value=4094, base-type=BT_BMC_CMC_Zellspannung_052, invalid-value=Invalid_BMC_CMC_Zellspannung_052_XIX_BMC_CMC_Zellspannung_02_XIX_HCP5_CANFD01:4095, compu-method=CM_BMC_CMC_Zellspannung_052, data-constr=DC_BMC_CMC_Zellspannung_052, unit=Unit_Unit_MilliVolt, transfer-property=PENDING  # Einzelzellspannung zur Uebertragung per RTM
          signal BMC_CMC_Zellspannung_053_XIX_BMC_CMC_Zellspannung_02_XIX_HCP5_CANFD01: start 168, 12 bit, little-endian, data-type-policy=OVERRIDE, i-signal-type=PRIMITIVE, init-value=4094, base-type=BT_BMC_CMC_Zellspannung_053, invalid-value=Invalid_BMC_CMC_Zellspannung_053_XIX_BMC_CMC_Zellspannung_02_XIX_HCP5_CANFD01:4095, compu-method=CM_BMC_CMC_Zellspannung_053, data-constr=DC_BMC_CMC_Zellspannung_053, unit=Unit_Unit_MilliVolt, transfer-property=PENDING  # Einzelzellspannung zur Uebertragung per RTM
          signal BMC_CMC_Zellspannung_054_XIX_BMC_CMC_Zellspannung_02_XIX_HCP5_CANFD01: start 180, 12 bit, little-endian, data-type-policy=OVERRIDE, i-signal-type=PRIMITIVE, init-value=4094, base-type=BT_BMC_CMC_Zellspannung_054, invalid-value=Invalid_BMC_CMC_Zellspannung_054_XIX_BMC_CMC_Zellspannung_02_XIX_HCP5_CANFD01:4095, compu-method=CM_BMC_CMC_Zellspannung_054, data-constr=DC_BMC_CMC_Zellspannung_054, unit=Unit_Unit_MilliVolt, transfer-property=PENDING  # Einzelzellspannung zur Uebertragung per RTM
          signal BMC_CMC_Zellspannung_055_XIX_BMC_CMC_Zellspannung_02_XIX_HCP5_CANFD01: start 192, 12 bit, little-endian, data-type-policy=OVERRIDE, i-signal-type=PRIMITIVE, init-value=4094, base-type=BT_BMC_CMC_Zellspannung_055, invalid-value=Invalid_BMC_CMC_Zellspannung_055_XIX_BMC_CMC_Zellspannung_02_XIX_HCP5_CANFD01:4095, compu-method=CM_BMC_CMC_Zellspannung_055, data-constr=DC_BMC_CMC_Zellspannung_055, unit=Unit_Unit_MilliVolt, transfer-property=PENDING  # Einzelzellspannung zur Uebertragung per RTM
          signal BMC_CMC_Zellspannung_056_XIX_BMC_CMC_Zellspannung_02_XIX_HCP5_CANFD01: start 204, 12 bit, little-endian, data-type-policy=OVERRIDE, i-signal-type=PRIMITIVE, init-value=4094, base-type=BT_BMC_CMC_Zellspannung_056, invalid-value=Invalid_BMC_CMC_Zellspannung_056_XIX_BMC_CMC_Zellspannung_02_XIX_HCP5_CANFD01:4095, compu-method=CM_BMC_CMC_Zellspannung_056, data-constr=DC_BMC_CMC_Zellspannung_056, unit=Unit_Unit_MilliVolt, transfer-property=PENDING  # Einzelzellspannung zur Uebertragung per RTM
          signal BMC_CMC_Zellspannung_057_XIX_BMC_CMC_Zellspannung_02_XIX_HCP5_CANFD01: start 216, 12 bit, little-endian, data-type-policy=OVERRIDE, i-signal-type=PRIMITIVE, init-value=4094, base-type=BT_BMC_CMC_Zellspannung_057, invalid-value=Invalid_BMC_CMC_Zellspannung_057_XIX_BMC_CMC_Zellspannung_02_XIX_HCP5_CANFD01:4095, compu-method=CM_BMC_CMC_Zellspannung_057, data-constr=DC_BMC_CMC_Zellspannung_057, unit=Unit_Unit_MilliVolt, transfer-property=PENDING  # Einzelzellspannung zur Uebertragung per RTM
          signal BMC_CMC_Zellspannung_058_XIX_BMC_CMC_Zellspannung_02_XIX_HCP5_CANFD01: start 228, 12 bit, little-endian, data-type-policy=OVERRIDE, i-signal-type=PRIMITIVE, init-value=4094, base-type=BT_BMC_CMC_Zellspannung_058, invalid-value=Invalid_BMC_CMC_Zellspannung_058_XIX_BMC_CMC_Zellspannung_02_XIX_HCP5_CANFD01:4095, compu-method=CM_BMC_CMC_Zellspannung_058, data-constr=DC_BMC_CMC_Zellspannung_058, unit=Unit_Unit_MilliVolt, transfer-property=PENDING  # Einzelzellspannung zur Uebertragung per RTM
          signal BMC_CMC_Zellspannung_059_XIX_BMC_CMC_Zellspannung_02_XIX_HCP5_CANFD01: start 240, 12 bit, little-endian, data-type-policy=OVERRIDE, i-signal-type=PRIMITIVE, init-value=4094, base-type=BT_BMC_CMC_Zellspannung_059, invalid-value=Invalid_BMC_CMC_Zellspannung_059_XIX_BMC_CMC_Zellspannung_02_XIX_HCP5_CANFD01:4095, compu-method=CM_BMC_CMC_Zellspannung_059, data-constr=DC_BMC_CMC_Zellspannung_059, unit=Unit_Unit_MilliVolt, transfer-property=PENDING  # Einzelzellspannung zur Uebertragung per RTM
          signal BMC_CMC_Zellspannung_060_XIX_BMC_CMC_Zellspannung_02_XIX_HCP5_CANFD01: start 252, 12 bit, little-endian, data-type-policy=OVERRIDE, i-signal-type=PRIMITIVE, init-value=4094, base-type=BT_BMC_CMC_Zellspannung_060, invalid-value=Invalid_BMC_CMC_Zellspannung_060_XIX_BMC_CMC_Zellspannung_02_XIX_HCP5_CANFD01:4095, compu-method=CM_BMC_CMC_Zellspannung_060, data-constr=DC_BMC_CMC_Zellspannung_060, unit=Unit_Unit_MilliVolt, transfer-property=PENDING  # Einzelzellspannung zur Uebertragung per RTM
          signal BMC_CMC_Zellspannung_061_XIX_BMC_CMC_Zellspannung_02_XIX_HCP5_CANFD01: start 264, 12 bit, little-endian, data-type-policy=OVERRIDE, i-signal-type=PRIMITIVE, init-value=4094, base-type=BT_BMC_CMC_Zellspannung_061, invalid-value=Invalid_BMC_CMC_Zellspannung_061_XIX_BMC_CMC_Zellspannung_02_XIX_HCP5_CANFD01:4095, compu-method=CM_BMC_CMC_Zellspannung_061, data-constr=DC_BMC_CMC_Zellspannung_061, unit=Unit_Unit_MilliVolt, transfer-property=PENDING  # Einzelzellspannung zur Uebertragung per RTM
          signal BMC_CMC_Zellspannung_062_XIX_BMC_CMC_Zellspannung_02_XIX_HCP5_CANFD01: start 276, 12 bit, little-endian, data-type-policy=OVERRIDE, i-signal-type=PRIMITIVE, init-value=4094, base-type=BT_BMC_CMC_Zellspannung_062, invalid-value=Invalid_BMC_CMC_Zellspannung_062_XIX_BMC_CMC_Zellspannung_02_XIX_HCP5_CANFD01:4095, compu-method=CM_BMC_CMC_Zellspannung_062, data-constr=DC_BMC_CMC_Zellspannung_062, unit=Unit_Unit_MilliVolt, transfer-property=PENDING  # Einzelzellspannung zur Uebertragung per RTM
          signal BMC_CMC_Zellspannung_063_XIX_BMC_CMC_Zellspannung_02_XIX_HCP5_CANFD01: start 288, 12 bit, little-endian, data-type-policy=OVERRIDE, i-signal-type=PRIMITIVE, init-value=4094, base-type=BT_BMC_CMC_Zellspannung_063, invalid-value=Invalid_BMC_CMC_Zellspannung_063_XIX_BMC_CMC_Zellspannung_02_XIX_HCP5_CANFD01:4095, compu-method=CM_BMC_CMC_Zellspannung_063, data-constr=DC_BMC_CMC_Zellspannung_063, unit=Unit_Unit_MilliVolt, transfer-property=PENDING  # Einzelzellspannung zur Uebertragung per RTM
          signal BMC_CMC_Zellspannung_064_XIX_BMC_CMC_Zellspannung_02_XIX_HCP5_CANFD01: start 300, 12 bit, little-endian, data-type-policy=OVERRIDE, i-signal-type=PRIMITIVE, init-value=4094, base-type=BT_BMC_CMC_Zellspannung_064, invalid-value=Invalid_BMC_CMC_Zellspannung_064_XIX_BMC_CMC_Zellspannung_02_XIX_HCP5_CANFD01:4095, compu-method=CM_BMC_CMC_Zellspannung_064, data-constr=DC_BMC_CMC_Zellspannung_064, unit=Unit_Unit_MilliVolt, transfer-property=PENDING  # Einzelzellspannung zur Uebertragung per RTM
          signal BMC_CMC_Zellspannung_065_XIX_BMC_CMC_Zellspannung_02_XIX_HCP5_CANFD01: start 312, 12 bit, little-endian, data-type-policy=OVERRIDE, i-signal-type=PRIMITIVE, init-value=4094, base-type=BT_BMC_CMC_Zellspannung_065, invalid-value=Invalid_BMC_CMC_Zellspannung_065_XIX_BMC_CMC_Zellspannung_02_XIX_HCP5_CANFD01:4095, compu-method=CM_BMC_CMC_Zellspannung_065, data-constr=DC_BMC_CMC_Zellspannung_065, unit=Unit_Unit_MilliVolt, transfer-property=PENDING  # Einzelzellspannung zur Uebertragung per RTM
          signal BMC_CMC_Zellspannung_066_XIX_BMC_CMC_Zellspannung_02_XIX_HCP5_CANFD01: start 324, 12 bit, little-endian, data-type-policy=OVERRIDE, i-signal-type=PRIMITIVE, init-value=4094, base-type=BT_BMC_CMC_Zellspannung_066, invalid-value=Invalid_BMC_CMC_Zellspannung_066_XIX_BMC_CMC_Zellspannung_02_XIX_HCP5_CANFD01:4095, compu-method=CM_BMC_CMC_Zellspannung_066, data-constr=DC_BMC_CMC_Zellspannung_066, unit=Unit_Unit_MilliVolt, transfer-property=PENDING  # Einzelzellspannung zur Uebertragung per RTM
          signal BMC_CMC_Zellspannung_067_XIX_BMC_CMC_Zellspannung_02_XIX_HCP5_CANFD01: start 336, 12 bit, little-endian, data-type-policy=OVERRIDE, i-signal-type=PRIMITIVE, init-value=4094, base-type=BT_BMC_CMC_Zellspannung_067, invalid-value=Invalid_BMC_CMC_Zellspannung_067_XIX_BMC_CMC_Zellspannung_02_XIX_HCP5_CANFD01:4095, compu-method=CM_BMC_CMC_Zellspannung_067, data-constr=DC_BMC_CMC_Zellspannung_067, unit=Unit_Unit_MilliVolt, transfer-property=PENDING  # Einzelzellspannung zur Uebertragung per RTM
          signal BMC_CMC_Zellspannung_068_XIX_BMC_CMC_Zellspannung_02_XIX_HCP5_CANFD01: start 348, 12 bit, little-endian, data-type-policy=OVERRIDE, i-signal-type=PRIMITIVE, init-value=4094, base-type=BT_BMC_CMC_Zellspannung_068, invalid-value=Invalid_BMC_CMC_Zellspannung_068_XIX_BMC_CMC_Zellspannung_02_XIX_HCP5_CANFD01:4095, compu-method=CM_BMC_CMC_Zellspannung_068, data-constr=DC_BMC_CMC_Zellspannung_068, unit=Unit_Unit_MilliVolt, transfer-property=PENDING  # Einzelzellspannung zur Uebertragung per RTM
          signal BMC_CMC_Zellspannung_069_XIX_BMC_CMC_Zellspannung_02_XIX_HCP5_CANFD01: start 360, 12 bit, little-endian, data-type-policy=OVERRIDE, i-signal-type=PRIMITIVE, init-value=4094, base-type=BT_BMC_CMC_Zellspannung_069, invalid-value=Invalid_BMC_CMC_Zellspannung_069_XIX_BMC_CMC_Zellspannung_02_XIX_HCP5_CANFD01:4095, compu-method=CM_BMC_CMC_Zellspannung_069, data-constr=DC_BMC_CMC_Zellspannung_069, unit=Unit_Unit_MilliVolt, transfer-property=PENDING  # Einzelzellspannung zur Uebertragung per RTM
          signal BMC_CMC_Zellspannung_070_XIX_BMC_CMC_Zellspannung_02_XIX_HCP5_CANFD01: start 372, 12 bit, little-endian, data-type-policy=OVERRIDE, i-signal-type=PRIMITIVE, init-value=4094, base-type=BT_BMC_CMC_Zellspannung_070, invalid-value=Invalid_BMC_CMC_Zellspannung_070_XIX_BMC_CMC_Zellspannung_02_XIX_HCP5_CANFD01:4095, compu-method=CM_BMC_CMC_Zellspannung_070, data-constr=DC_BMC_CMC_Zellspannung_070, unit=Unit_Unit_MilliVolt, transfer-property=PENDING  # Einzelzellspannung zur Uebertragung per RTM
          signal BMC_CMC_Zellspannung_071_XIX_BMC_CMC_Zellspannung_02_XIX_HCP5_CANFD01: start 384, 12 bit, little-endian, data-type-policy=OVERRIDE, i-signal-type=PRIMITIVE, init-value=4094, base-type=BT_BMC_CMC_Zellspannung_071, invalid-value=Invalid_BMC_CMC_Zellspannung_071_XIX_BMC_CMC_Zellspannung_02_XIX_HCP5_CANFD01:4095, compu-method=CM_BMC_CMC_Zellspannung_071, data-constr=DC_BMC_CMC_Zellspannung_071, unit=Unit_Unit_MilliVolt, transfer-property=PENDING  # Einzelzellspannung zur Uebertragung per RTM
          signal BMC_CMC_Zellspannung_072_XIX_BMC_CMC_Zellspannung_02_XIX_HCP5_CANFD01: start 396, 12 bit, little-endian, data-type-policy=OVERRIDE, i-signal-type=PRIMITIVE, init-value=4094, base-type=BT_BMC_CMC_Zellspannung_072, invalid-value=Invalid_BMC_CMC_Zellspannung_072_XIX_BMC_CMC_Zellspannung_02_XIX_HCP5_CANFD01:4095, compu-method=CM_BMC_CMC_Zellspannung_072, data-constr=DC_BMC_CMC_Zellspannung_072, unit=Unit_Unit_MilliVolt, transfer-property=PENDING  # Einzelzellspannung zur Uebertragung per RTM
          signal BMC_CMC_Zellspannung_073_XIX_BMC_CMC_Zellspannung_02_XIX_HCP5_CANFD01: start 408, 12 bit, little-endian, data-type-policy=OVERRIDE, i-signal-type=PRIMITIVE, init-value=4094, base-type=BT_BMC_CMC_Zellspannung_073, invalid-value=Invalid_BMC_CMC_Zellspannung_073_XIX_BMC_CMC_Zellspannung_02_XIX_HCP5_CANFD01:4095, compu-method=CM_BMC_CMC_Zellspannung_073, data-constr=DC_BMC_CMC_Zellspannung_073, unit=Unit_Unit_MilliVolt, transfer-property=PENDING  # Einzelzellspannung zur Uebertragung per RTM
          signal BMC_CMC_Zellspannung_074_XIX_BMC_CMC_Zellspannung_02_XIX_HCP5_CANFD01: start 420, 12 bit, little-endian, data-type-policy=OVERRIDE, i-signal-type=PRIMITIVE, init-value=4094, base-type=BT_BMC_CMC_Zellspannung_074, invalid-value=Invalid_BMC_CMC_Zellspannung_074_XIX_BMC_CMC_Zellspannung_02_XIX_HCP5_CANFD01:4095, compu-method=CM_BMC_CMC_Zellspannung_074, data-constr=DC_BMC_CMC_Zellspannung_074, unit=Unit_Unit_MilliVolt, transfer-property=PENDING  # Einzelzellspannung zur Uebertragung per RTM
          signal BMC_CMC_Zellspannung_075_XIX_BMC_CMC_Zellspannung_02_XIX_HCP5_CANFD01: start 432, 12 bit, little-endian, data-type-policy=OVERRIDE, i-signal-type=PRIMITIVE, init-value=4094, base-type=BT_BMC_CMC_Zellspannung_075, invalid-value=Invalid_BMC_CMC_Zellspannung_075_XIX_BMC_CMC_Zellspannung_02_XIX_HCP5_CANFD01:4095, compu-method=CM_BMC_CMC_Zellspannung_075, data-constr=DC_BMC_CMC_Zellspannung_075, unit=Unit_Unit_MilliVolt, transfer-property=PENDING  # Einzelzellspannung zur Uebertragung per RTM
          signal BMC_CMC_Zellspannung_076_XIX_BMC_CMC_Zellspannung_02_XIX_HCP5_CANFD01: start 444, 12 bit, little-endian, data-type-policy=OVERRIDE, i-signal-type=PRIMITIVE, init-value=4094, base-type=BT_BMC_CMC_Zellspannung_076, invalid-value=Invalid_BMC_CMC_Zellspannung_076_XIX_BMC_CMC_Zellspannung_02_XIX_HCP5_CANFD01:4095, compu-method=CM_BMC_CMC_Zellspannung_076, data-constr=DC_BMC_CMC_Zellspannung_076, unit=Unit_Unit_MilliVolt, transfer-property=PENDING  # Einzelzellspannung zur Uebertragung per RTM
          signal BMC_CMC_Zellspannung_077_XIX_BMC_CMC_Zellspannung_02_XIX_HCP5_CANFD01: start 456, 12 bit, little-endian, data-type-policy=OVERRIDE, i-signal-type=PRIMITIVE, init-value=4094, base-type=BT_BMC_CMC_Zellspannung_077, invalid-value=Invalid_BMC_CMC_Zellspannung_077_XIX_BMC_CMC_Zellspannung_02_XIX_HCP5_CANFD01:4095, compu-method=CM_BMC_CMC_Zellspannung_077, data-constr=DC_BMC_CMC_Zellspannung_077, unit=Unit_Unit_MilliVolt, transfer-property=PENDING  # Einzelzellspannung zur Uebertragung per RTM
          signal BMC_CMC_Zellspannung_078_XIX_BMC_CMC_Zellspannung_02_XIX_HCP5_CANFD01: start 468, 12 bit, little-endian, data-type-policy=OVERRIDE, i-signal-type=PRIMITIVE, init-value=4094, base-type=BT_BMC_CMC_Zellspannung_078, invalid-value=Invalid_BMC_CMC_Zellspannung_078_XIX_BMC_CMC_Zellspannung_02_XIX_HCP5_CANFD01:4095, compu-method=CM_BMC_CMC_Zellspannung_078, data-constr=DC_BMC_CMC_Zellspannung_078, unit=Unit_Unit_MilliVolt, transfer-property=PENDING  # Einzelzellspannung zur Uebertragung per RTM
          signal BMC_CMC_Zellspannung_02_Messzeit_XIX_BMC_CMC_Zellspannung_02_XIX_HCP5_CANFD01: start 480, 8 bit, little-endian, data-type-policy=OVERRIDE, i-signal-type=PRIMITIVE, init-value=254, base-type=BT_BMC_CMC_Zellspannung_02_Messzeit, invalid-value=Invalid_BMC_CMC_Zellspannung_02_Messzeit_XIX_BMC_CMC_Zellspannung_02_XIX_HCP5_CANFD01:255, compu-method=CM_BMC_CMC_Zellspannung_02_Messzeit, data-constr=DC_BMC_CMC_Zellspannung_02_Messzeit, unit=Unit_Unit_None, transfer-property=PENDING  # Messzeit zu Botschaft BMC_CMC_Zellspannung_02
      frame BMC_CMC_Zellspannung_03_XIX_HCP5_CANFD01: id 0x1A55562E, from BMC_HV, frame-length=64, can-addressing-mode=EXTENDED, can-frame-rx-behavior=CAN-FD, can-frame-tx-behavior=CAN-FD
        pdu BMC_CMC_Zellspannung_03_XIX_HCP5_CANFD01: length=64, transmission-mode-true-timing=cyclic-timing={time-offset=0, time-period=1}, unused-bit-pattern=0
          signal BMC_CMC_Zellspannung_079_XIX_BMC_CMC_Zellspannung_03_XIX_HCP5_CANFD01: start 12, 12 bit, little-endian, data-type-policy=OVERRIDE, i-signal-type=PRIMITIVE, init-value=4094, base-type=BT_BMC_CMC_Zellspannung_079, invalid-value=Invalid_BMC_CMC_Zellspannung_079_XIX_BMC_CMC_Zellspannung_03_XIX_HCP5_CANFD01:4095, compu-method=CM_BMC_CMC_Zellspannung_079, data-constr=DC_BMC_CMC_Zellspannung_079, unit=Unit_Unit_MilliVolt, transfer-property=PENDING  # Einzelzellspannung zur Uebertragung per RTM
          signal BMC_CMC_Zellspannung_080_XIX_BMC_CMC_Zellspannung_03_XIX_HCP5_CANFD01: start 24, 12 bit, little-endian, data-type-policy=OVERRIDE, i-signal-type=PRIMITIVE, init-value=4094, base-type=BT_BMC_CMC_Zellspannung_080, invalid-value=Invalid_BMC_CMC_Zellspannung_080_XIX_BMC_CMC_Zellspannung_03_XIX_HCP5_CANFD01:4095, compu-method=CM_BMC_CMC_Zellspannung_080, data-constr=DC_BMC_CMC_Zellspannung_080, unit=Unit_Unit_MilliVolt, transfer-property=PENDING  # Einzelzellspannung zur Uebertragung per RTM
          signal BMC_CMC_Zellspannung_081_XIX_BMC_CMC_Zellspannung_03_XIX_HCP5_CANFD01: start 36, 12 bit, little-endian, data-type-policy=OVERRIDE, i-signal-type=PRIMITIVE, init-value=4094, base-type=BT_BMC_CMC_Zellspannung_081, invalid-value=Invalid_BMC_CMC_Zellspannung_081_XIX_BMC_CMC_Zellspannung_03_XIX_HCP5_CANFD01:4095, compu-method=CM_BMC_CMC_Zellspannung_081, data-constr=DC_BMC_CMC_Zellspannung_081, unit=Unit_Unit_MilliVolt, transfer-property=PENDING  # Einzelzellspannung zur Uebertragung per RTM
          signal BMC_CMC_Zellspannung_082_XIX_BMC_CMC_Zellspannung_03_XIX_HCP5_CANFD01: start 48, 12 bit, little-endian, data-type-policy=OVERRIDE, i-signal-type=PRIMITIVE, init-value=4094, base-type=BT_BMC_CMC_Zellspannung_082, invalid-value=Invalid_BMC_CMC_Zellspannung_082_XIX_BMC_CMC_Zellspannung_03_XIX_HCP5_CANFD01:4095, compu-method=CM_BMC_CMC_Zellspannung_082, data-constr=DC_BMC_CMC_Zellspannung_082, unit=Unit_Unit_MilliVolt, transfer-property=PENDING  # Einzelzellspannung zur Uebertragung per RTM
          signal BMC_CMC_Zellspannung_083_XIX_BMC_CMC_Zellspannung_03_XIX_HCP5_CANFD01: start 60, 12 bit, little-endian, data-type-policy=OVERRIDE, i-signal-type=PRIMITIVE, init-value=4094, base-type=BT_BMC_CMC_Zellspannung_083, invalid-value=Invalid_BMC_CMC_Zellspannung_083_XIX_BMC_CMC_Zellspannung_03_XIX_HCP5_CANFD01:4095, compu-method=CM_BMC_CMC_Zellspannung_083, data-constr=DC_BMC_CMC_Zellspannung_083, unit=Unit_Unit_MilliVolt, transfer-property=PENDING  # Einzelzellspannung zur Uebertragung per RTM
          signal BMC_CMC_Zellspannung_084_XIX_BMC_CMC_Zellspannung_03_XIX_HCP5_CANFD01: start 72, 12 bit, little-endian, data-type-policy=OVERRIDE, i-signal-type=PRIMITIVE, init-value=4094, base-type=BT_BMC_CMC_Zellspannung_084, invalid-value=Invalid_BMC_CMC_Zellspannung_084_XIX_BMC_CMC_Zellspannung_03_XIX_HCP5_CANFD01:4095, compu-method=CM_BMC_CMC_Zellspannung_084, data-constr=DC_BMC_CMC_Zellspannung_084, unit=Unit_Unit_MilliVolt, transfer-property=PENDING  # Einzelzellspannung zur Uebertragung per RTM
          signal BMC_CMC_Zellspannung_085_XIX_BMC_CMC_Zellspannung_03_XIX_HCP5_CANFD01: start 84, 12 bit, little-endian, data-type-policy=OVERRIDE, i-signal-type=PRIMITIVE, init-value=4094, base-type=BT_BMC_CMC_Zellspannung_085, invalid-value=Invalid_BMC_CMC_Zellspannung_085_XIX_BMC_CMC_Zellspannung_03_XIX_HCP5_CANFD01:4095, compu-method=CM_BMC_CMC_Zellspannung_085, data-constr=DC_BMC_CMC_Zellspannung_085, unit=Unit_Unit_MilliVolt, transfer-property=PENDING  # Einzelzellspannung zur Uebertragung per RTM
          signal BMC_CMC_Zellspannung_086_XIX_BMC_CMC_Zellspannung_03_XIX_HCP5_CANFD01: start 96, 12 bit, little-endian, data-type-policy=OVERRIDE, i-signal-type=PRIMITIVE, init-value=4094, base-type=BT_BMC_CMC_Zellspannung_086, invalid-value=Invalid_BMC_CMC_Zellspannung_086_XIX_BMC_CMC_Zellspannung_03_XIX_HCP5_CANFD01:4095, compu-method=CM_BMC_CMC_Zellspannung_086, data-constr=DC_BMC_CMC_Zellspannung_086, unit=Unit_Unit_MilliVolt, transfer-property=PENDING  # Einzelzellspannung zur Uebertragung per RTM
          signal BMC_CMC_Zellspannung_087_XIX_BMC_CMC_Zellspannung_03_XIX_HCP5_CANFD01: start 108, 12 bit, little-endian, data-type-policy=OVERRIDE, i-signal-type=PRIMITIVE, init-value=4094, base-type=BT_BMC_CMC_Zellspannung_087, invalid-value=Invalid_BMC_CMC_Zellspannung_087_XIX_BMC_CMC_Zellspannung_03_XIX_HCP5_CANFD01:4095, compu-method=CM_BMC_CMC_Zellspannung_087, data-constr=DC_BMC_CMC_Zellspannung_087, unit=Unit_Unit_MilliVolt, transfer-property=PENDING  # Einzelzellspannung zur Uebertragung per RTM
          signal BMC_CMC_Zellspannung_088_XIX_BMC_CMC_Zellspannung_03_XIX_HCP5_CANFD01: start 120, 12 bit, little-endian, data-type-policy=OVERRIDE, i-signal-type=PRIMITIVE, init-value=4094, base-type=BT_BMC_CMC_Zellspannung_088, invalid-value=Invalid_BMC_CMC_Zellspannung_088_XIX_BMC_CMC_Zellspannung_03_XIX_HCP5_CANFD01:4095, compu-method=CM_BMC_CMC_Zellspannung_088, data-constr=DC_BMC_CMC_Zellspannung_088, unit=Unit_Unit_MilliVolt, transfer-property=PENDING  # Einzelzellspannung zur Uebertragung per RTM
          signal BMC_CMC_Zellspannung_089_XIX_BMC_CMC_Zellspannung_03_XIX_HCP5_CANFD01: start 132, 12 bit, little-endian, data-type-policy=OVERRIDE, i-signal-type=PRIMITIVE, init-value=4094, base-type=BT_BMC_CMC_Zellspannung_089, invalid-value=Invalid_BMC_CMC_Zellspannung_089_XIX_BMC_CMC_Zellspannung_03_XIX_HCP5_CANFD01:4095, compu-method=CM_BMC_CMC_Zellspannung_089, data-constr=DC_BMC_CMC_Zellspannung_089, unit=Unit_Unit_MilliVolt, transfer-property=PENDING  # Einzelzellspannung zur Uebertragung per RTM
          signal BMC_CMC_Zellspannung_090_XIX_BMC_CMC_Zellspannung_03_XIX_HCP5_CANFD01: start 144, 12 bit, little-endian, data-type-policy=OVERRIDE, i-signal-type=PRIMITIVE, init-value=4094, base-type=BT_BMC_CMC_Zellspannung_090, invalid-value=Invalid_BMC_CMC_Zellspannung_090_XIX_BMC_CMC_Zellspannung_03_XIX_HCP5_CANFD01:4095, compu-method=CM_BMC_CMC_Zellspannung_090, data-constr=DC_BMC_CMC_Zellspannung_090, unit=Unit_Unit_MilliVolt, transfer-property=PENDING  # Einzelzellspannung zur Uebertragung per RTM
          signal BMC_CMC_Zellspannung_091_XIX_BMC_CMC_Zellspannung_03_XIX_HCP5_CANFD01: start 156, 12 bit, little-endian, data-type-policy=OVERRIDE, i-signal-type=PRIMITIVE, init-value=4094, base-type=BT_BMC_CMC_Zellspannung_091, invalid-value=Invalid_BMC_CMC_Zellspannung_091_XIX_BMC_CMC_Zellspannung_03_XIX_HCP5_CANFD01:4095, compu-method=CM_BMC_CMC_Zellspannung_091, data-constr=DC_BMC_CMC_Zellspannung_091, unit=Unit_Unit_MilliVolt, transfer-property=PENDING  # Einzelzellspannung zur Uebertragung per RTM
          signal BMC_CMC_Zellspannung_092_XIX_BMC_CMC_Zellspannung_03_XIX_HCP5_CANFD01: start 168, 12 bit, little-endian, data-type-policy=OVERRIDE, i-signal-type=PRIMITIVE, init-value=4094, base-type=BT_BMC_CMC_Zellspannung_092, invalid-value=Invalid_BMC_CMC_Zellspannung_092_XIX_BMC_CMC_Zellspannung_03_XIX_HCP5_CANFD01:4095, compu-method=CM_BMC_CMC_Zellspannung_092, data-constr=DC_BMC_CMC_Zellspannung_092, unit=Unit_Unit_MilliVolt, transfer-property=PENDING  # Einzelzellspannung zur Uebertragung per RTM
          signal BMC_CMC_Zellspannung_093_XIX_BMC_CMC_Zellspannung_03_XIX_HCP5_CANFD01: start 180, 12 bit, little-endian, data-type-policy=OVERRIDE, i-signal-type=PRIMITIVE, init-value=4094, base-type=BT_BMC_CMC_Zellspannung_093, invalid-value=Invalid_BMC_CMC_Zellspannung_093_XIX_BMC_CMC_Zellspannung_03_XIX_HCP5_CANFD01:4095, compu-method=CM_BMC_CMC_Zellspannung_093, data-constr=DC_BMC_CMC_Zellspannung_093, unit=Unit_Unit_MilliVolt, transfer-property=PENDING  # Einzelzellspannung zur Uebertragung per RTM
          signal BMC_CMC_Zellspannung_094_XIX_BMC_CMC_Zellspannung_03_XIX_HCP5_CANFD01: start 192, 12 bit, little-endian, data-type-policy=OVERRIDE, i-signal-type=PRIMITIVE, init-value=4094, base-type=BT_BMC_CMC_Zellspannung_094, invalid-value=Invalid_BMC_CMC_Zellspannung_094_XIX_BMC_CMC_Zellspannung_03_XIX_HCP5_CANFD01:4095, compu-method=CM_BMC_CMC_Zellspannung_094, data-constr=DC_BMC_CMC_Zellspannung_094, unit=Unit_Unit_MilliVolt, transfer-property=PENDING  # Einzelzellspannung zur Uebertragung per RTM
          signal BMC_CMC_Zellspannung_095_XIX_BMC_CMC_Zellspannung_03_XIX_HCP5_CANFD01: start 204, 12 bit, little-endian, data-type-policy=OVERRIDE, i-signal-type=PRIMITIVE, init-value=4094, base-type=BT_BMC_CMC_Zellspannung_095, invalid-value=Invalid_BMC_CMC_Zellspannung_095_XIX_BMC_CMC_Zellspannung_03_XIX_HCP5_CANFD01:4095, compu-method=CM_BMC_CMC_Zellspannung_095, data-constr=DC_BMC_CMC_Zellspannung_095, unit=Unit_Unit_MilliVolt, transfer-property=PENDING  # Einzelzellspannung zur Uebertragung per RTM
          signal BMC_CMC_Zellspannung_096_XIX_BMC_CMC_Zellspannung_03_XIX_HCP5_CANFD01: start 216, 12 bit, little-endian, data-type-policy=OVERRIDE, i-signal-type=PRIMITIVE, init-value=4094, base-type=BT_BMC_CMC_Zellspannung_096, invalid-value=Invalid_BMC_CMC_Zellspannung_096_XIX_BMC_CMC_Zellspannung_03_XIX_HCP5_CANFD01:4095, compu-method=CM_BMC_CMC_Zellspannung_096, data-constr=DC_BMC_CMC_Zellspannung_096, unit=Unit_Unit_MilliVolt, transfer-property=PENDING  # Einzelzellspannung zur Uebertragung per RTM
          signal BMC_CMC_Zellspannung_097_XIX_BMC_CMC_Zellspannung_03_XIX_HCP5_CANFD01: start 228, 12 bit, little-endian, data-type-policy=OVERRIDE, i-signal-type=PRIMITIVE, init-value=4094, base-type=BT_BMC_CMC_Zellspannung_097, invalid-value=Invalid_BMC_CMC_Zellspannung_097_XIX_BMC_CMC_Zellspannung_03_XIX_HCP5_CANFD01:4095, compu-method=CM_BMC_CMC_Zellspannung_097, data-constr=DC_BMC_CMC_Zellspannung_097, unit=Unit_Unit_MilliVolt, transfer-property=PENDING  # Einzelzellspannung zur Uebertragung per RTM
          signal BMC_CMC_Zellspannung_098_XIX_BMC_CMC_Zellspannung_03_XIX_HCP5_CANFD01: start 240, 12 bit, little-endian, data-type-policy=OVERRIDE, i-signal-type=PRIMITIVE, init-value=4094, base-type=BT_BMC_CMC_Zellspannung_098, invalid-value=Invalid_BMC_CMC_Zellspannung_098_XIX_BMC_CMC_Zellspannung_03_XIX_HCP5_CANFD01:4095, compu-method=CM_BMC_CMC_Zellspannung_098, data-constr=DC_BMC_CMC_Zellspannung_098, unit=Unit_Unit_MilliVolt, transfer-property=PENDING  # Einzelzellspannung zur Uebertragung per RTM
          signal BMC_CMC_Zellspannung_099_XIX_BMC_CMC_Zellspannung_03_XIX_HCP5_CANFD01: start 252, 12 bit, little-endian, data-type-policy=OVERRIDE, i-signal-type=PRIMITIVE, init-value=4094, base-type=BT_BMC_CMC_Zellspannung_099, invalid-value=Invalid_BMC_CMC_Zellspannung_099_XIX_BMC_CMC_Zellspannung_03_XIX_HCP5_CANFD01:4095, compu-method=CM_BMC_CMC_Zellspannung_099, data-constr=DC_BMC_CMC_Zellspannung_099, unit=Unit_Unit_MilliVolt, transfer-property=PENDING  # Einzelzellspannung zur Uebertragung per RTM
          signal BMC_CMC_Zellspannung_100_XIX_BMC_CMC_Zellspannung_03_XIX_HCP5_CANFD01: start 264, 12 bit, little-endian, data-type-policy=OVERRIDE, i-signal-type=PRIMITIVE, init-value=4094, base-type=BT_BMC_CMC_Zellspannung_100, invalid-value=Invalid_BMC_CMC_Zellspannung_100_XIX_BMC_CMC_Zellspannung_03_XIX_HCP5_CANFD01:4095, compu-method=CM_BMC_CMC_Zellspannung_100, data-constr=DC_BMC_CMC_Zellspannung_100, unit=Unit_Unit_MilliVolt, transfer-property=PENDING  # Einzelzellspannung zur Uebertragung per RTM
          signal BMC_CMC_Zellspannung_101_XIX_BMC_CMC_Zellspannung_03_XIX_HCP5_CANFD01: start 276, 12 bit, little-endian, data-type-policy=OVERRIDE, i-signal-type=PRIMITIVE, init-value=4094, base-type=BT_BMC_CMC_Zellspannung_101, invalid-value=Invalid_BMC_CMC_Zellspannung_101_XIX_BMC_CMC_Zellspannung_03_XIX_HCP5_CANFD01:4095, compu-method=CM_BMC_CMC_Zellspannung_101, data-constr=DC_BMC_CMC_Zellspannung_101, unit=Unit_Unit_MilliVolt, transfer-property=PENDING  # Einzelzellspannung zur Uebertragung per RTM
          signal BMC_CMC_Zellspannung_102_XIX_BMC_CMC_Zellspannung_03_XIX_HCP5_CANFD01: start 288, 12 bit, little-endian, data-type-policy=OVERRIDE, i-signal-type=PRIMITIVE, init-value=4094, base-type=BT_BMC_CMC_Zellspannung_102, invalid-value=Invalid_BMC_CMC_Zellspannung_102_XIX_BMC_CMC_Zellspannung_03_XIX_HCP5_CANFD01:4095, compu-method=CM_BMC_CMC_Zellspannung_102, data-constr=DC_BMC_CMC_Zellspannung_102, unit=Unit_Unit_MilliVolt, transfer-property=PENDING  # Einzelzellspannung zur Uebertragung per RTM
          signal BMC_CMC_Zellspannung_103_XIX_BMC_CMC_Zellspannung_03_XIX_HCP5_CANFD01: start 300, 12 bit, little-endian, data-type-policy=OVERRIDE, i-signal-type=PRIMITIVE, init-value=4094, base-type=BT_BMC_CMC_Zellspannung_103, invalid-value=Invalid_BMC_CMC_Zellspannung_103_XIX_BMC_CMC_Zellspannung_03_XIX_HCP5_CANFD01:4095, compu-method=CM_BMC_CMC_Zellspannung_103, data-constr=DC_BMC_CMC_Zellspannung_103, unit=Unit_Unit_MilliVolt, transfer-property=PENDING  # Einzelzellspannung zur Uebertragung per RTM
          signal BMC_CMC_Zellspannung_104_XIX_BMC_CMC_Zellspannung_03_XIX_HCP5_CANFD01: start 312, 12 bit, little-endian, data-type-policy=OVERRIDE, i-signal-type=PRIMITIVE, init-value=4094, base-type=BT_BMC_CMC_Zellspannung_104, invalid-value=Invalid_BMC_CMC_Zellspannung_104_XIX_BMC_CMC_Zellspannung_03_XIX_HCP5_CANFD01:4095, compu-method=CM_BMC_CMC_Zellspannung_104, data-constr=DC_BMC_CMC_Zellspannung_104, unit=Unit_Unit_MilliVolt, transfer-property=PENDING  # Einzelzellspannung zur Uebertragung per RTM
          signal BMC_CMC_Zellspannung_105_XIX_BMC_CMC_Zellspannung_03_XIX_HCP5_CANFD01: start 324, 12 bit, little-endian, data-type-policy=OVERRIDE, i-signal-type=PRIMITIVE, init-value=4094, base-type=BT_BMC_CMC_Zellspannung_105, invalid-value=Invalid_BMC_CMC_Zellspannung_105_XIX_BMC_CMC_Zellspannung_03_XIX_HCP5_CANFD01:4095, compu-method=CM_BMC_CMC_Zellspannung_105, data-constr=DC_BMC_CMC_Zellspannung_105, unit=Unit_Unit_MilliVolt, transfer-property=PENDING  # Einzelzellspannung zur Uebertragung per RTM
          signal BMC_CMC_Zellspannung_106_XIX_BMC_CMC_Zellspannung_03_XIX_HCP5_CANFD01: start 336, 12 bit, little-endian, data-type-policy=OVERRIDE, i-signal-type=PRIMITIVE, init-value=4094, base-type=BT_BMC_CMC_Zellspannung_106, invalid-value=Invalid_BMC_CMC_Zellspannung_106_XIX_BMC_CMC_Zellspannung_03_XIX_HCP5_CANFD01:4095, compu-method=CM_BMC_CMC_Zellspannung_106, data-constr=DC_BMC_CMC_Zellspannung_106, unit=Unit_Unit_MilliVolt, transfer-property=PENDING  # Einzelzellspannung zur Uebertragung per RTM
          signal BMC_CMC_Zellspannung_107_XIX_BMC_CMC_Zellspannung_03_XIX_HCP5_CANFD01: start 348, 12 bit, little-endian, data-type-policy=OVERRIDE, i-signal-type=PRIMITIVE, init-value=4094, base-type=BT_BMC_CMC_Zellspannung_107, invalid-value=Invalid_BMC_CMC_Zellspannung_107_XIX_BMC_CMC_Zellspannung_03_XIX_HCP5_CANFD01:4095, compu-method=CM_BMC_CMC_Zellspannung_107, data-constr=DC_BMC_CMC_Zellspannung_107, unit=Unit_Unit_MilliVolt, transfer-property=PENDING  # Einzelzellspannung zur Uebertragung per RTM
          signal BMC_CMC_Zellspannung_108_XIX_BMC_CMC_Zellspannung_03_XIX_HCP5_CANFD01: start 360, 12 bit, little-endian, data-type-policy=OVERRIDE, i-signal-type=PRIMITIVE, init-value=4094, base-type=BT_BMC_CMC_Zellspannung_108, invalid-value=Invalid_BMC_CMC_Zellspannung_108_XIX_BMC_CMC_Zellspannung_03_XIX_HCP5_CANFD01:4095, compu-method=CM_BMC_CMC_Zellspannung_108, data-constr=DC_BMC_CMC_Zellspannung_108, unit=Unit_Unit_MilliVolt, transfer-property=PENDING  # Einzelzellspannung zur Uebertragung per RTM
          signal BMC_CMC_Zellspannung_109_XIX_BMC_CMC_Zellspannung_03_XIX_HCP5_CANFD01: start 372, 12 bit, little-endian, data-type-policy=OVERRIDE, i-signal-type=PRIMITIVE, init-value=4094, base-type=BT_BMC_CMC_Zellspannung_109, invalid-value=Invalid_BMC_CMC_Zellspannung_109_XIX_BMC_CMC_Zellspannung_03_XIX_HCP5_CANFD01:4095, compu-method=CM_BMC_CMC_Zellspannung_109, data-constr=DC_BMC_CMC_Zellspannung_109, unit=Unit_Unit_MilliVolt, transfer-property=PENDING  # Einzelzellspannung zur Uebertragung per RTM
          signal BMC_CMC_Zellspannung_110_XIX_BMC_CMC_Zellspannung_03_XIX_HCP5_CANFD01: start 384, 12 bit, little-endian, data-type-policy=OVERRIDE, i-signal-type=PRIMITIVE, init-value=4094, base-type=BT_BMC_CMC_Zellspannung_110, invalid-value=Invalid_BMC_CMC_Zellspannung_110_XIX_BMC_CMC_Zellspannung_03_XIX_HCP5_CANFD01:4095, compu-method=CM_BMC_CMC_Zellspannung_110, data-constr=DC_BMC_CMC_Zellspannung_110, unit=Unit_Unit_MilliVolt, transfer-property=PENDING  # Einzelzellspannung zur Uebertragung per RTM
          signal BMC_CMC_Zellspannung_111_XIX_BMC_CMC_Zellspannung_03_XIX_HCP5_CANFD01: start 396, 12 bit, little-endian, data-type-policy=OVERRIDE, i-signal-type=PRIMITIVE, init-value=4094, base-type=BT_BMC_CMC_Zellspannung_111, invalid-value=Invalid_BMC_CMC_Zellspannung_111_XIX_BMC_CMC_Zellspannung_03_XIX_HCP5_CANFD01:4095, compu-method=CM_BMC_CMC_Zellspannung_111, data-constr=DC_BMC_CMC_Zellspannung_111, unit=Unit_Unit_MilliVolt, transfer-property=PENDING  # Einzelzellspannung zur Uebertragung per RTM
          signal BMC_CMC_Zellspannung_112_XIX_BMC_CMC_Zellspannung_03_XIX_HCP5_CANFD01: start 408, 12 bit, little-endian, data-type-policy=OVERRIDE, i-signal-type=PRIMITIVE, init-value=4094, base-type=BT_BMC_CMC_Zellspannung_112, invalid-value=Invalid_BMC_CMC_Zellspannung_112_XIX_BMC_CMC_Zellspannung_03_XIX_HCP5_CANFD01:4095, compu-method=CM_BMC_CMC_Zellspannung_112, data-constr=DC_BMC_CMC_Zellspannung_112, unit=Unit_Unit_MilliVolt, transfer-property=PENDING  # Einzelzellspannung zur Uebertragung per RTM
          signal BMC_CMC_Zellspannung_113_XIX_BMC_CMC_Zellspannung_03_XIX_HCP5_CANFD01: start 420, 12 bit, little-endian, data-type-policy=OVERRIDE, i-signal-type=PRIMITIVE, init-value=4094, base-type=BT_BMC_CMC_Zellspannung_113, invalid-value=Invalid_BMC_CMC_Zellspannung_113_XIX_BMC_CMC_Zellspannung_03_XIX_HCP5_CANFD01:4095, compu-method=CM_BMC_CMC_Zellspannung_113, data-constr=DC_BMC_CMC_Zellspannung_113, unit=Unit_Unit_MilliVolt, transfer-property=PENDING  # Einzelzellspannung zur Uebertragung per RTM
          signal BMC_CMC_Zellspannung_114_XIX_BMC_CMC_Zellspannung_03_XIX_HCP5_CANFD01: start 432, 12 bit, little-endian, data-type-policy=OVERRIDE, i-signal-type=PRIMITIVE, init-value=4094, base-type=BT_BMC_CMC_Zellspannung_114, invalid-value=Invalid_BMC_CMC_Zellspannung_114_XIX_BMC_CMC_Zellspannung_03_XIX_HCP5_CANFD01:4095, compu-method=CM_BMC_CMC_Zellspannung_114, data-constr=DC_BMC_CMC_Zellspannung_114, unit=Unit_Unit_MilliVolt, transfer-property=PENDING  # Einzelzellspannung zur Uebertragung per RTM
          signal BMC_CMC_Zellspannung_115_XIX_BMC_CMC_Zellspannung_03_XIX_HCP5_CANFD01: start 444, 12 bit, little-endian, data-type-policy=OVERRIDE, i-signal-type=PRIMITIVE, init-value=4094, base-type=BT_BMC_CMC_Zellspannung_115, invalid-value=Invalid_BMC_CMC_Zellspannung_115_XIX_BMC_CMC_Zellspannung_03_XIX_HCP5_CANFD01:4095, compu-method=CM_BMC_CMC_Zellspannung_115, data-constr=DC_BMC_CMC_Zellspannung_115, unit=Unit_Unit_MilliVolt, transfer-property=PENDING  # Einzelzellspannung zur Uebertragung per RTM
          signal BMC_CMC_Zellspannung_116_XIX_BMC_CMC_Zellspannung_03_XIX_HCP5_CANFD01: start 456, 12 bit, little-endian, data-type-policy=OVERRIDE, i-signal-type=PRIMITIVE, init-value=4094, base-type=BT_BMC_CMC_Zellspannung_116, invalid-value=Invalid_BMC_CMC_Zellspannung_116_XIX_BMC_CMC_Zellspannung_03_XIX_HCP5_CANFD01:4095, compu-method=CM_BMC_CMC_Zellspannung_116, data-constr=DC_BMC_CMC_Zellspannung_116, unit=Unit_Unit_MilliVolt, transfer-property=PENDING  # Einzelzellspannung zur Uebertragung per RTM
          signal BMC_CMC_Zellspannung_117_XIX_BMC_CMC_Zellspannung_03_XIX_HCP5_CANFD01: start 468, 12 bit, little-endian, data-type-policy=OVERRIDE, i-signal-type=PRIMITIVE, init-value=4094, base-type=BT_BMC_CMC_Zellspannung_117, invalid-value=Invalid_BMC_CMC_Zellspannung_117_XIX_BMC_CMC_Zellspannung_03_XIX_HCP5_CANFD01:4095, compu-method=CM_BMC_CMC_Zellspannung_117, data-constr=DC_BMC_CMC_Zellspannung_117, unit=Unit_Unit_MilliVolt, transfer-property=PENDING  # Einzelzellspannung zur Uebertragung per RTM
          signal BMC_CMC_Zellspannung_03_Messzeit_XIX_BMC_CMC_Zellspannung_03_XIX_HCP5_CANFD01: start 480, 8 bit, little-endian, data-type-policy=OVERRIDE, i-signal-type=PRIMITIVE, init-value=254, base-type=BT_BMC_CMC_Zellspannung_03_Messzeit, invalid-value=Invalid_BMC_CMC_Zellspannung_03_Messzeit_XIX_BMC_CMC_Zellspannung_03_XIX_HCP5_CANFD01:255, compu-method=CM_BMC_CMC_Zellspannung_03_Messzeit, data-constr=DC_BMC_CMC_Zellspannung_03_Messzeit, unit=Unit_Unit_None, transfer-property=PENDING  # Messzeit zu Botschaft BMC_CMC_Zellspannung_03
      frame BMC_CMC_Zellspannung_04_XIX_HCP5_CANFD01: id 0x1A55562F, from BMC_HV, frame-length=64, can-addressing-mode=EXTENDED, can-frame-rx-behavior=CAN-FD, can-frame-tx-behavior=CAN-FD
        pdu BMC_CMC_Zellspannung_04_XIX_HCP5_CANFD01: length=64, transmission-mode-true-timing=cyclic-timing={time-offset=0, time-period=1}, unused-bit-pattern=0
          signal BMC_CMC_Zellspannung_118_XIX_BMC_CMC_Zellspannung_04_XIX_HCP5_CANFD01: start 12, 12 bit, little-endian, data-type-policy=OVERRIDE, i-signal-type=PRIMITIVE, init-value=4094, base-type=BT_BMC_CMC_Zellspannung_118, invalid-value=Invalid_BMC_CMC_Zellspannung_118_XIX_BMC_CMC_Zellspannung_04_XIX_HCP5_CANFD01:4095, compu-method=CM_BMC_CMC_Zellspannung_118, data-constr=DC_BMC_CMC_Zellspannung_118, unit=Unit_Unit_MilliVolt, transfer-property=PENDING  # Einzelzellspannung zur Uebertragung per RTM
          signal BMC_CMC_Zellspannung_119_XIX_BMC_CMC_Zellspannung_04_XIX_HCP5_CANFD01: start 24, 12 bit, little-endian, data-type-policy=OVERRIDE, i-signal-type=PRIMITIVE, init-value=4094, base-type=BT_BMC_CMC_Zellspannung_119, invalid-value=Invalid_BMC_CMC_Zellspannung_119_XIX_BMC_CMC_Zellspannung_04_XIX_HCP5_CANFD01:4095, compu-method=CM_BMC_CMC_Zellspannung_119, data-constr=DC_BMC_CMC_Zellspannung_119, unit=Unit_Unit_MilliVolt, transfer-property=PENDING  # Einzelzellspannung zur Uebertragung per RTM
          signal BMC_CMC_Zellspannung_120_XIX_BMC_CMC_Zellspannung_04_XIX_HCP5_CANFD01: start 36, 12 bit, little-endian, data-type-policy=OVERRIDE, i-signal-type=PRIMITIVE, init-value=4094, base-type=BT_BMC_CMC_Zellspannung_120, invalid-value=Invalid_BMC_CMC_Zellspannung_120_XIX_BMC_CMC_Zellspannung_04_XIX_HCP5_CANFD01:4095, compu-method=CM_BMC_CMC_Zellspannung_120, data-constr=DC_BMC_CMC_Zellspannung_120, unit=Unit_Unit_MilliVolt, transfer-property=PENDING  # Einzelzellspannung zur Uebertragung per RTM
          signal BMC_CMC_Zellspannung_121_XIX_BMC_CMC_Zellspannung_04_XIX_HCP5_CANFD01: start 48, 12 bit, little-endian, data-type-policy=OVERRIDE, i-signal-type=PRIMITIVE, init-value=4094, base-type=BT_BMC_CMC_Zellspannung_121, invalid-value=Invalid_BMC_CMC_Zellspannung_121_XIX_BMC_CMC_Zellspannung_04_XIX_HCP5_CANFD01:4095, compu-method=CM_BMC_CMC_Zellspannung_121, data-constr=DC_BMC_CMC_Zellspannung_121, unit=Unit_Unit_MilliVolt, transfer-property=PENDING  # Einzelzellspannung zur Uebertragung per RTM
          signal BMC_CMC_Zellspannung_122_XIX_BMC_CMC_Zellspannung_04_XIX_HCP5_CANFD01: start 60, 12 bit, little-endian, data-type-policy=OVERRIDE, i-signal-type=PRIMITIVE, init-value=4094, base-type=BT_BMC_CMC_Zellspannung_122, invalid-value=Invalid_BMC_CMC_Zellspannung_122_XIX_BMC_CMC_Zellspannung_04_XIX_HCP5_CANFD01:4095, compu-method=CM_BMC_CMC_Zellspannung_122, data-constr=DC_BMC_CMC_Zellspannung_122, unit=Unit_Unit_MilliVolt, transfer-property=PENDING  # Einzelzellspannung zur Uebertragung per RTM
          signal BMC_CMC_Zellspannung_123_XIX_BMC_CMC_Zellspannung_04_XIX_HCP5_CANFD01: start 72, 12 bit, little-endian, data-type-policy=OVERRIDE, i-signal-type=PRIMITIVE, init-value=4094, base-type=BT_BMC_CMC_Zellspannung_123, invalid-value=Invalid_BMC_CMC_Zellspannung_123_XIX_BMC_CMC_Zellspannung_04_XIX_HCP5_CANFD01:4095, compu-method=CM_BMC_CMC_Zellspannung_123, data-constr=DC_BMC_CMC_Zellspannung_123, unit=Unit_Unit_MilliVolt, transfer-property=PENDING  # Einzelzellspannung zur Uebertragung per RTM
          signal BMC_CMC_Zellspannung_124_XIX_BMC_CMC_Zellspannung_04_XIX_HCP5_CANFD01: start 84, 12 bit, little-endian, data-type-policy=OVERRIDE, i-signal-type=PRIMITIVE, init-value=4094, base-type=BT_BMC_CMC_Zellspannung_124, invalid-value=Invalid_BMC_CMC_Zellspannung_124_XIX_BMC_CMC_Zellspannung_04_XIX_HCP5_CANFD01:4095, compu-method=CM_BMC_CMC_Zellspannung_124, data-constr=DC_BMC_CMC_Zellspannung_124, unit=Unit_Unit_MilliVolt, transfer-property=PENDING  # Einzelzellspannung zur Uebertragung per RTM
          signal BMC_CMC_Zellspannung_125_XIX_BMC_CMC_Zellspannung_04_XIX_HCP5_CANFD01: start 96, 12 bit, little-endian, data-type-policy=OVERRIDE, i-signal-type=PRIMITIVE, init-value=4094, base-type=BT_BMC_CMC_Zellspannung_125, invalid-value=Invalid_BMC_CMC_Zellspannung_125_XIX_BMC_CMC_Zellspannung_04_XIX_HCP5_CANFD01:4095, compu-method=CM_BMC_CMC_Zellspannung_125, data-constr=DC_BMC_CMC_Zellspannung_125, unit=Unit_Unit_MilliVolt, transfer-property=PENDING  # Einzelzellspannung zur Uebertragung per RTM
          signal BMC_CMC_Zellspannung_126_XIX_BMC_CMC_Zellspannung_04_XIX_HCP5_CANFD01: start 108, 12 bit, little-endian, data-type-policy=OVERRIDE, i-signal-type=PRIMITIVE, init-value=4094, base-type=BT_BMC_CMC_Zellspannung_126, invalid-value=Invalid_BMC_CMC_Zellspannung_126_XIX_BMC_CMC_Zellspannung_04_XIX_HCP5_CANFD01:4095, compu-method=CM_BMC_CMC_Zellspannung_126, data-constr=DC_BMC_CMC_Zellspannung_126, unit=Unit_Unit_MilliVolt, transfer-property=PENDING  # Einzelzellspannung zur Uebertragung per RTM
          signal BMC_CMC_Zellspannung_127_XIX_BMC_CMC_Zellspannung_04_XIX_HCP5_CANFD01: start 120, 12 bit, little-endian, data-type-policy=OVERRIDE, i-signal-type=PRIMITIVE, init-value=4094, base-type=BT_BMC_CMC_Zellspannung_127, invalid-value=Invalid_BMC_CMC_Zellspannung_127_XIX_BMC_CMC_Zellspannung_04_XIX_HCP5_CANFD01:4095, compu-method=CM_BMC_CMC_Zellspannung_127, data-constr=DC_BMC_CMC_Zellspannung_127, unit=Unit_Unit_MilliVolt, transfer-property=PENDING  # Einzelzellspannung zur Uebertragung per RTM
          signal BMC_CMC_Zellspannung_128_XIX_BMC_CMC_Zellspannung_04_XIX_HCP5_CANFD01: start 132, 12 bit, little-endian, data-type-policy=OVERRIDE, i-signal-type=PRIMITIVE, init-value=4094, base-type=BT_BMC_CMC_Zellspannung_128, invalid-value=Invalid_BMC_CMC_Zellspannung_128_XIX_BMC_CMC_Zellspannung_04_XIX_HCP5_CANFD01:4095, compu-method=CM_BMC_CMC_Zellspannung_128, data-constr=DC_BMC_CMC_Zellspannung_128, unit=Unit_Unit_MilliVolt, transfer-property=PENDING  # Einzelzellspannung zur Uebertragung per RTM
          signal BMC_CMC_Zellspannung_129_XIX_BMC_CMC_Zellspannung_04_XIX_HCP5_CANFD01: start 144, 12 bit, little-endian, data-type-policy=OVERRIDE, i-signal-type=PRIMITIVE, init-value=4094, base-type=BT_BMC_CMC_Zellspannung_129, invalid-value=Invalid_BMC_CMC_Zellspannung_129_XIX_BMC_CMC_Zellspannung_04_XIX_HCP5_CANFD01:4095, compu-method=CM_BMC_CMC_Zellspannung_129, data-constr=DC_BMC_CMC_Zellspannung_129, unit=Unit_Unit_MilliVolt, transfer-property=PENDING  # Einzelzellspannung zur Uebertragung per RTM
          signal BMC_CMC_Zellspannung_130_XIX_BMC_CMC_Zellspannung_04_XIX_HCP5_CANFD01: start 156, 12 bit, little-endian, data-type-policy=OVERRIDE, i-signal-type=PRIMITIVE, init-value=4094, base-type=BT_BMC_CMC_Zellspannung_130, invalid-value=Invalid_BMC_CMC_Zellspannung_130_XIX_BMC_CMC_Zellspannung_04_XIX_HCP5_CANFD01:4095, compu-method=CM_BMC_CMC_Zellspannung_130, data-constr=DC_BMC_CMC_Zellspannung_130, unit=Unit_Unit_MilliVolt, transfer-property=PENDING  # Einzelzellspannung zur Uebertragung per RTM
          signal BMC_CMC_Zellspannung_131_XIX_BMC_CMC_Zellspannung_04_XIX_HCP5_CANFD01: start 168, 12 bit, little-endian, data-type-policy=OVERRIDE, i-signal-type=PRIMITIVE, init-value=4094, base-type=BT_BMC_CMC_Zellspannung_131, invalid-value=Invalid_BMC_CMC_Zellspannung_131_XIX_BMC_CMC_Zellspannung_04_XIX_HCP5_CANFD01:4095, compu-method=CM_BMC_CMC_Zellspannung_131, data-constr=DC_BMC_CMC_Zellspannung_131, unit=Unit_Unit_MilliVolt, transfer-property=PENDING  # Einzelzellspannung zur Uebertragung per RTM
          signal BMC_CMC_Zellspannung_132_XIX_BMC_CMC_Zellspannung_04_XIX_HCP5_CANFD01: start 180, 12 bit, little-endian, data-type-policy=OVERRIDE, i-signal-type=PRIMITIVE, init-value=4094, base-type=BT_BMC_CMC_Zellspannung_132, invalid-value=Invalid_BMC_CMC_Zellspannung_132_XIX_BMC_CMC_Zellspannung_04_XIX_HCP5_CANFD01:4095, compu-method=CM_BMC_CMC_Zellspannung_132, data-constr=DC_BMC_CMC_Zellspannung_132, unit=Unit_Unit_MilliVolt, transfer-property=PENDING  # Einzelzellspannung zur Uebertragung per RTM
          signal BMC_CMC_Zellspannung_133_XIX_BMC_CMC_Zellspannung_04_XIX_HCP5_CANFD01: start 192, 12 bit, little-endian, data-type-policy=OVERRIDE, i-signal-type=PRIMITIVE, init-value=4094, base-type=BT_BMC_CMC_Zellspannung_133, invalid-value=Invalid_BMC_CMC_Zellspannung_133_XIX_BMC_CMC_Zellspannung_04_XIX_HCP5_CANFD01:4095, compu-method=CM_BMC_CMC_Zellspannung_133, data-constr=DC_BMC_CMC_Zellspannung_133, unit=Unit_Unit_MilliVolt, transfer-property=PENDING  # Einzelzellspannung zur Uebertragung per RTM
          signal BMC_CMC_Zellspannung_134_XIX_BMC_CMC_Zellspannung_04_XIX_HCP5_CANFD01: start 204, 12 bit, little-endian, data-type-policy=OVERRIDE, i-signal-type=PRIMITIVE, init-value=4094, base-type=BT_BMC_CMC_Zellspannung_134, invalid-value=Invalid_BMC_CMC_Zellspannung_134_XIX_BMC_CMC_Zellspannung_04_XIX_HCP5_CANFD01:4095, compu-method=CM_BMC_CMC_Zellspannung_134, data-constr=DC_BMC_CMC_Zellspannung_134, unit=Unit_Unit_MilliVolt, transfer-property=PENDING  # Einzelzellspannung zur Uebertragung per RTM
          signal BMC_CMC_Zellspannung_135_XIX_BMC_CMC_Zellspannung_04_XIX_HCP5_CANFD01: start 216, 12 bit, little-endian, data-type-policy=OVERRIDE, i-signal-type=PRIMITIVE, init-value=4094, base-type=BT_BMC_CMC_Zellspannung_135, invalid-value=Invalid_BMC_CMC_Zellspannung_135_XIX_BMC_CMC_Zellspannung_04_XIX_HCP5_CANFD01:4095, compu-method=CM_BMC_CMC_Zellspannung_135, data-constr=DC_BMC_CMC_Zellspannung_135, unit=Unit_Unit_MilliVolt, transfer-property=PENDING  # Einzelzellspannung zur Uebertragung per RTM
          signal BMC_CMC_Zellspannung_136_XIX_BMC_CMC_Zellspannung_04_XIX_HCP5_CANFD01: start 228, 12 bit, little-endian, data-type-policy=OVERRIDE, i-signal-type=PRIMITIVE, init-value=4094, base-type=BT_BMC_CMC_Zellspannung_136, invalid-value=Invalid_BMC_CMC_Zellspannung_136_XIX_BMC_CMC_Zellspannung_04_XIX_HCP5_CANFD01:4095, compu-method=CM_BMC_CMC_Zellspannung_136, data-constr=DC_BMC_CMC_Zellspannung_136, unit=Unit_Unit_MilliVolt, transfer-property=PENDING  # Einzelzellspannung zur Uebertragung per RTM
          signal BMC_CMC_Zellspannung_137_XIX_BMC_CMC_Zellspannung_04_XIX_HCP5_CANFD01: start 240, 12 bit, little-endian, data-type-policy=OVERRIDE, i-signal-type=PRIMITIVE, init-value=4094, base-type=BT_BMC_CMC_Zellspannung_137, invalid-value=Invalid_BMC_CMC_Zellspannung_137_XIX_BMC_CMC_Zellspannung_04_XIX_HCP5_CANFD01:4095, compu-method=CM_BMC_CMC_Zellspannung_137, data-constr=DC_BMC_CMC_Zellspannung_137, unit=Unit_Unit_MilliVolt, transfer-property=PENDING  # Einzelzellspannung zur Uebertragung per RTM
          signal BMC_CMC_Zellspannung_138_XIX_BMC_CMC_Zellspannung_04_XIX_HCP5_CANFD01: start 252, 12 bit, little-endian, data-type-policy=OVERRIDE, i-signal-type=PRIMITIVE, init-value=4094, base-type=BT_BMC_CMC_Zellspannung_138, invalid-value=Invalid_BMC_CMC_Zellspannung_138_XIX_BMC_CMC_Zellspannung_04_XIX_HCP5_CANFD01:4095, compu-method=CM_BMC_CMC_Zellspannung_138, data-constr=DC_BMC_CMC_Zellspannung_138, unit=Unit_Unit_MilliVolt, transfer-property=PENDING  # Einzelzellspannung zur Uebertragung per RTM
          signal BMC_CMC_Zellspannung_139_XIX_BMC_CMC_Zellspannung_04_XIX_HCP5_CANFD01: start 264, 12 bit, little-endian, data-type-policy=OVERRIDE, i-signal-type=PRIMITIVE, init-value=4094, base-type=BT_BMC_CMC_Zellspannung_139, invalid-value=Invalid_BMC_CMC_Zellspannung_139_XIX_BMC_CMC_Zellspannung_04_XIX_HCP5_CANFD01:4095, compu-method=CM_BMC_CMC_Zellspannung_139, data-constr=DC_BMC_CMC_Zellspannung_139, unit=Unit_Unit_MilliVolt, transfer-property=PENDING  # Einzelzellspannung zur Uebertragung per RTM
          signal BMC_CMC_Zellspannung_140_XIX_BMC_CMC_Zellspannung_04_XIX_HCP5_CANFD01: start 276, 12 bit, little-endian, data-type-policy=OVERRIDE, i-signal-type=PRIMITIVE, init-value=4094, base-type=BT_BMC_CMC_Zellspannung_140, invalid-value=Invalid_BMC_CMC_Zellspannung_140_XIX_BMC_CMC_Zellspannung_04_XIX_HCP5_CANFD01:4095, compu-method=CM_BMC_CMC_Zellspannung_140, data-constr=DC_BMC_CMC_Zellspannung_140, unit=Unit_Unit_MilliVolt, transfer-property=PENDING  # Einzelzellspannung zur Uebertragung per RTM
          signal BMC_CMC_Zellspannung_141_XIX_BMC_CMC_Zellspannung_04_XIX_HCP5_CANFD01: start 288, 12 bit, little-endian, data-type-policy=OVERRIDE, i-signal-type=PRIMITIVE, init-value=4094, base-type=BT_BMC_CMC_Zellspannung_141, invalid-value=Invalid_BMC_CMC_Zellspannung_141_XIX_BMC_CMC_Zellspannung_04_XIX_HCP5_CANFD01:4095, compu-method=CM_BMC_CMC_Zellspannung_141, data-constr=DC_BMC_CMC_Zellspannung_141, unit=Unit_Unit_MilliVolt, transfer-property=PENDING  # Einzelzellspannung zur Uebertragung per RTM
          signal BMC_CMC_Zellspannung_142_XIX_BMC_CMC_Zellspannung_04_XIX_HCP5_CANFD01: start 300, 12 bit, little-endian, data-type-policy=OVERRIDE, i-signal-type=PRIMITIVE, init-value=4094, base-type=BT_BMC_CMC_Zellspannung_142, invalid-value=Invalid_BMC_CMC_Zellspannung_142_XIX_BMC_CMC_Zellspannung_04_XIX_HCP5_CANFD01:4095, compu-method=CM_BMC_CMC_Zellspannung_142, data-constr=DC_BMC_CMC_Zellspannung_142, unit=Unit_Unit_MilliVolt, transfer-property=PENDING  # Einzelzellspannung zur Uebertragung per RTM
          signal BMC_CMC_Zellspannung_143_XIX_BMC_CMC_Zellspannung_04_XIX_HCP5_CANFD01: start 312, 12 bit, little-endian, data-type-policy=OVERRIDE, i-signal-type=PRIMITIVE, init-value=4094, base-type=BT_BMC_CMC_Zellspannung_143, invalid-value=Invalid_BMC_CMC_Zellspannung_143_XIX_BMC_CMC_Zellspannung_04_XIX_HCP5_CANFD01:4095, compu-method=CM_BMC_CMC_Zellspannung_143, data-constr=DC_BMC_CMC_Zellspannung_143, unit=Unit_Unit_MilliVolt, transfer-property=PENDING  # Einzelzellspannung zur Uebertragung per RTM
          signal BMC_CMC_Zellspannung_144_XIX_BMC_CMC_Zellspannung_04_XIX_HCP5_CANFD01: start 324, 12 bit, little-endian, data-type-policy=OVERRIDE, i-signal-type=PRIMITIVE, init-value=4094, base-type=BT_BMC_CMC_Zellspannung_144, invalid-value=Invalid_BMC_CMC_Zellspannung_144_XIX_BMC_CMC_Zellspannung_04_XIX_HCP5_CANFD01:4095, compu-method=CM_BMC_CMC_Zellspannung_144, data-constr=DC_BMC_CMC_Zellspannung_144, unit=Unit_Unit_MilliVolt, transfer-property=PENDING  # Einzelzellspannung zur Uebertragung per RTM
          signal BMC_CMC_Zellspannung_145_XIX_BMC_CMC_Zellspannung_04_XIX_HCP5_CANFD01: start 336, 12 bit, little-endian, data-type-policy=OVERRIDE, i-signal-type=PRIMITIVE, init-value=4094, base-type=BT_BMC_CMC_Zellspannung_145, invalid-value=Invalid_BMC_CMC_Zellspannung_145_XIX_BMC_CMC_Zellspannung_04_XIX_HCP5_CANFD01:4095, compu-method=CM_BMC_CMC_Zellspannung_145, data-constr=DC_BMC_CMC_Zellspannung_145, unit=Unit_Unit_MilliVolt, transfer-property=PENDING  # Einzelzellspannung zur Uebertragung per RTM
          signal BMC_CMC_Zellspannung_146_XIX_BMC_CMC_Zellspannung_04_XIX_HCP5_CANFD01: start 348, 12 bit, little-endian, data-type-policy=OVERRIDE, i-signal-type=PRIMITIVE, init-value=4094, base-type=BT_BMC_CMC_Zellspannung_146, invalid-value=Invalid_BMC_CMC_Zellspannung_146_XIX_BMC_CMC_Zellspannung_04_XIX_HCP5_CANFD01:4095, compu-method=CM_BMC_CMC_Zellspannung_146, data-constr=DC_BMC_CMC_Zellspannung_146, unit=Unit_Unit_MilliVolt, transfer-property=PENDING  # Einzelzellspannung zur Uebertragung per RTM
          signal BMC_CMC_Zellspannung_147_XIX_BMC_CMC_Zellspannung_04_XIX_HCP5_CANFD01: start 360, 12 bit, little-endian, data-type-policy=OVERRIDE, i-signal-type=PRIMITIVE, init-value=4094, base-type=BT_BMC_CMC_Zellspannung_147, invalid-value=Invalid_BMC_CMC_Zellspannung_147_XIX_BMC_CMC_Zellspannung_04_XIX_HCP5_CANFD01:4095, compu-method=CM_BMC_CMC_Zellspannung_147, data-constr=DC_BMC_CMC_Zellspannung_147, unit=Unit_Unit_MilliVolt, transfer-property=PENDING  # Einzelzellspannung zur Uebertragung per RTM
          signal BMC_CMC_Zellspannung_148_XIX_BMC_CMC_Zellspannung_04_XIX_HCP5_CANFD01: start 372, 12 bit, little-endian, data-type-policy=OVERRIDE, i-signal-type=PRIMITIVE, init-value=4094, base-type=BT_BMC_CMC_Zellspannung_148, invalid-value=Invalid_BMC_CMC_Zellspannung_148_XIX_BMC_CMC_Zellspannung_04_XIX_HCP5_CANFD01:4095, compu-method=CM_BMC_CMC_Zellspannung_148, data-constr=DC_BMC_CMC_Zellspannung_148, unit=Unit_Unit_MilliVolt, transfer-property=PENDING  # Einzelzellspannung zur Uebertragung per RTM
          signal BMC_CMC_Zellspannung_149_XIX_BMC_CMC_Zellspannung_04_XIX_HCP5_CANFD01: start 384, 12 bit, little-endian, data-type-policy=OVERRIDE, i-signal-type=PRIMITIVE, init-value=4094, base-type=BT_BMC_CMC_Zellspannung_149, invalid-value=Invalid_BMC_CMC_Zellspannung_149_XIX_BMC_CMC_Zellspannung_04_XIX_HCP5_CANFD01:4095, compu-method=CM_BMC_CMC_Zellspannung_149, data-constr=DC_BMC_CMC_Zellspannung_149, unit=Unit_Unit_MilliVolt, transfer-property=PENDING  # Einzelzellspannung zur Uebertragung per RTM
          signal BMC_CMC_Zellspannung_150_XIX_BMC_CMC_Zellspannung_04_XIX_HCP5_CANFD01: start 396, 12 bit, little-endian, data-type-policy=OVERRIDE, i-signal-type=PRIMITIVE, init-value=4094, base-type=BT_BMC_CMC_Zellspannung_150, invalid-value=Invalid_BMC_CMC_Zellspannung_150_XIX_BMC_CMC_Zellspannung_04_XIX_HCP5_CANFD01:4095, compu-method=CM_BMC_CMC_Zellspannung_150, data-constr=DC_BMC_CMC_Zellspannung_150, unit=Unit_Unit_MilliVolt, transfer-property=PENDING  # Einzelzellspannung zur Uebertragung per RTM
          signal BMC_CMC_Zellspannung_151_XIX_BMC_CMC_Zellspannung_04_XIX_HCP5_CANFD01: start 408, 12 bit, little-endian, data-type-policy=OVERRIDE, i-signal-type=PRIMITIVE, init-value=4094, base-type=BT_BMC_CMC_Zellspannung_151, invalid-value=Invalid_BMC_CMC_Zellspannung_151_XIX_BMC_CMC_Zellspannung_04_XIX_HCP5_CANFD01:4095, compu-method=CM_BMC_CMC_Zellspannung_151, data-constr=DC_BMC_CMC_Zellspannung_151, unit=Unit_Unit_MilliVolt, transfer-property=PENDING  # Einzelzellspannung zur Uebertragung per RTM
          signal BMC_CMC_Zellspannung_152_XIX_BMC_CMC_Zellspannung_04_XIX_HCP5_CANFD01: start 420, 12 bit, little-endian, data-type-policy=OVERRIDE, i-signal-type=PRIMITIVE, init-value=4094, base-type=BT_BMC_CMC_Zellspannung_152, invalid-value=Invalid_BMC_CMC_Zellspannung_152_XIX_BMC_CMC_Zellspannung_04_XIX_HCP5_CANFD01:4095, compu-method=CM_BMC_CMC_Zellspannung_152, data-constr=DC_BMC_CMC_Zellspannung_152, unit=Unit_Unit_MilliVolt, transfer-property=PENDING  # Einzelzellspannung zur Uebertragung per RTM
          signal BMC_CMC_Zellspannung_153_XIX_BMC_CMC_Zellspannung_04_XIX_HCP5_CANFD01: start 432, 12 bit, little-endian, data-type-policy=OVERRIDE, i-signal-type=PRIMITIVE, init-value=4094, base-type=BT_BMC_CMC_Zellspannung_153, invalid-value=Invalid_BMC_CMC_Zellspannung_153_XIX_BMC_CMC_Zellspannung_04_XIX_HCP5_CANFD01:4095, compu-method=CM_BMC_CMC_Zellspannung_153, data-constr=DC_BMC_CMC_Zellspannung_153, unit=Unit_Unit_MilliVolt, transfer-property=PENDING  # Einzelzellspannung zur Uebertragung per RTM
          signal BMC_CMC_Zellspannung_154_XIX_BMC_CMC_Zellspannung_04_XIX_HCP5_CANFD01: start 444, 12 bit, little-endian, data-type-policy=OVERRIDE, i-signal-type=PRIMITIVE, init-value=4094, base-type=BT_BMC_CMC_Zellspannung_154, invalid-value=Invalid_BMC_CMC_Zellspannung_154_XIX_BMC_CMC_Zellspannung_04_XIX_HCP5_CANFD01:4095, compu-method=CM_BMC_CMC_Zellspannung_154, data-constr=DC_BMC_CMC_Zellspannung_154, unit=Unit_Unit_MilliVolt, transfer-property=PENDING  # Einzelzellspannung zur Uebertragung per RTM
          signal BMC_CMC_Zellspannung_155_XIX_BMC_CMC_Zellspannung_04_XIX_HCP5_CANFD01: start 456, 12 bit, little-endian, data-type-policy=OVERRIDE, i-signal-type=PRIMITIVE, init-value=4094, base-type=BT_BMC_CMC_Zellspannung_155, invalid-value=Invalid_BMC_CMC_Zellspannung_155_XIX_BMC_CMC_Zellspannung_04_XIX_HCP5_CANFD01:4095, compu-method=CM_BMC_CMC_Zellspannung_155, data-constr=DC_BMC_CMC_Zellspannung_155, unit=Unit_Unit_MilliVolt, transfer-property=PENDING  # Einzelzellspannung zur Uebertragung per RTM
          signal BMC_CMC_Zellspannung_156_XIX_BMC_CMC_Zellspannung_04_XIX_HCP5_CANFD01: start 468, 12 bit, little-endian, data-type-policy=OVERRIDE, i-signal-type=PRIMITIVE, init-value=4094, base-type=BT_BMC_CMC_Zellspannung_156, invalid-value=Invalid_BMC_CMC_Zellspannung_156_XIX_BMC_CMC_Zellspannung_04_XIX_HCP5_CANFD01:4095, compu-method=CM_BMC_CMC_Zellspannung_156, data-constr=DC_BMC_CMC_Zellspannung_156, unit=Unit_Unit_MilliVolt, transfer-property=PENDING  # Einzelzellspannung zur Uebertragung per RTM
          signal BMC_CMC_Zellspannung_04_Messzeit_XIX_BMC_CMC_Zellspannung_04_XIX_HCP5_CANFD01: start 480, 8 bit, little-endian, data-type-policy=OVERRIDE, i-signal-type=PRIMITIVE, init-value=254, base-type=BT_BMC_CMC_Zellspannung_04_Messzeit, invalid-value=Invalid_BMC_CMC_Zellspannung_04_Messzeit_XIX_BMC_CMC_Zellspannung_04_XIX_HCP5_CANFD01:255, compu-method=CM_BMC_CMC_Zellspannung_04_Messzeit, data-constr=DC_BMC_CMC_Zellspannung_04_Messzeit, unit=Unit_Unit_None, transfer-property=PENDING  # Messzeit zu Botschaft BMC_CMC_Zellspannung_04
      frame BMC_CMC_Zellspannung_05_XIX_HCP5_CANFD01: id 0x1A555630, from BMC_HV, frame-length=64, can-addressing-mode=EXTENDED, can-frame-rx-behavior=CAN-FD, can-frame-tx-behavior=CAN-FD
        pdu BMC_CMC_Zellspannung_05_XIX_HCP5_CANFD01: length=64, transmission-mode-true-timing=cyclic-timing={time-offset=0, time-period=1}, unused-bit-pattern=0
          signal BMC_CMC_Zellspannung_157_XIX_BMC_CMC_Zellspannung_05_XIX_HCP5_CANFD01: start 12, 12 bit, little-endian, data-type-policy=OVERRIDE, i-signal-type=PRIMITIVE, init-value=4094, base-type=BT_BMC_CMC_Zellspannung_157, invalid-value=Invalid_BMC_CMC_Zellspannung_157_XIX_BMC_CMC_Zellspannung_05_XIX_HCP5_CANFD01:4095, compu-method=CM_BMC_CMC_Zellspannung_157, data-constr=DC_BMC_CMC_Zellspannung_157, unit=Unit_Unit_MilliVolt, transfer-property=PENDING  # Einzelzellspannung zur Uebertragung per RTM
          signal BMC_CMC_Zellspannung_158_XIX_BMC_CMC_Zellspannung_05_XIX_HCP5_CANFD01: start 24, 12 bit, little-endian, data-type-policy=OVERRIDE, i-signal-type=PRIMITIVE, init-value=4094, base-type=BT_BMC_CMC_Zellspannung_158, invalid-value=Invalid_BMC_CMC_Zellspannung_158_XIX_BMC_CMC_Zellspannung_05_XIX_HCP5_CANFD01:4095, compu-method=CM_BMC_CMC_Zellspannung_158, data-constr=DC_BMC_CMC_Zellspannung_158, unit=Unit_Unit_MilliVolt, transfer-property=PENDING  # Einzelzellspannung zur Uebertragung per RTM
          signal BMC_CMC_Zellspannung_159_XIX_BMC_CMC_Zellspannung_05_XIX_HCP5_CANFD01: start 36, 12 bit, little-endian, data-type-policy=OVERRIDE, i-signal-type=PRIMITIVE, init-value=4094, base-type=BT_BMC_CMC_Zellspannung_159, invalid-value=Invalid_BMC_CMC_Zellspannung_159_XIX_BMC_CMC_Zellspannung_05_XIX_HCP5_CANFD01:4095, compu-method=CM_BMC_CMC_Zellspannung_159, data-constr=DC_BMC_CMC_Zellspannung_159, unit=Unit_Unit_MilliVolt, transfer-property=PENDING  # Einzelzellspannung zur Uebertragung per RTM
          signal BMC_CMC_Zellspannung_160_XIX_BMC_CMC_Zellspannung_05_XIX_HCP5_CANFD01: start 48, 12 bit, little-endian, data-type-policy=OVERRIDE, i-signal-type=PRIMITIVE, init-value=4094, base-type=BT_BMC_CMC_Zellspannung_160, invalid-value=Invalid_BMC_CMC_Zellspannung_160_XIX_BMC_CMC_Zellspannung_05_XIX_HCP5_CANFD01:4095, compu-method=CM_BMC_CMC_Zellspannung_160, data-constr=DC_BMC_CMC_Zellspannung_160, unit=Unit_Unit_MilliVolt, transfer-property=PENDING  # Einzelzellspannung zur Uebertragung per RTM
          signal BMC_CMC_Zellspannung_161_XIX_BMC_CMC_Zellspannung_05_XIX_HCP5_CANFD01: start 60, 12 bit, little-endian, data-type-policy=OVERRIDE, i-signal-type=PRIMITIVE, init-value=4094, base-type=BT_BMC_CMC_Zellspannung_161, invalid-value=Invalid_BMC_CMC_Zellspannung_161_XIX_BMC_CMC_Zellspannung_05_XIX_HCP5_CANFD01:4095, compu-method=CM_BMC_CMC_Zellspannung_161, data-constr=DC_BMC_CMC_Zellspannung_161, unit=Unit_Unit_MilliVolt, transfer-property=PENDING  # Einzelzellspannung zur Uebertragung per RTM
          signal BMC_CMC_Zellspannung_162_XIX_BMC_CMC_Zellspannung_05_XIX_HCP5_CANFD01: start 72, 12 bit, little-endian, data-type-policy=OVERRIDE, i-signal-type=PRIMITIVE, init-value=4094, base-type=BT_BMC_CMC_Zellspannung_162, invalid-value=Invalid_BMC_CMC_Zellspannung_162_XIX_BMC_CMC_Zellspannung_05_XIX_HCP5_CANFD01:4095, compu-method=CM_BMC_CMC_Zellspannung_162, data-constr=DC_BMC_CMC_Zellspannung_162, unit=Unit_Unit_MilliVolt, transfer-property=PENDING  # Einzelzellspannung zur Uebertragung per RTM
          signal BMC_CMC_Zellspannung_163_XIX_BMC_CMC_Zellspannung_05_XIX_HCP5_CANFD01: start 84, 12 bit, little-endian, data-type-policy=OVERRIDE, i-signal-type=PRIMITIVE, init-value=4094, base-type=BT_BMC_CMC_Zellspannung_163, invalid-value=Invalid_BMC_CMC_Zellspannung_163_XIX_BMC_CMC_Zellspannung_05_XIX_HCP5_CANFD01:4095, compu-method=CM_BMC_CMC_Zellspannung_163, data-constr=DC_BMC_CMC_Zellspannung_163, unit=Unit_Unit_MilliVolt, transfer-property=PENDING  # Einzelzellspannung zur Uebertragung per RTM
          signal BMC_CMC_Zellspannung_164_XIX_BMC_CMC_Zellspannung_05_XIX_HCP5_CANFD01: start 96, 12 bit, little-endian, data-type-policy=OVERRIDE, i-signal-type=PRIMITIVE, init-value=4094, base-type=BT_BMC_CMC_Zellspannung_164, invalid-value=Invalid_BMC_CMC_Zellspannung_164_XIX_BMC_CMC_Zellspannung_05_XIX_HCP5_CANFD01:4095, compu-method=CM_BMC_CMC_Zellspannung_164, data-constr=DC_BMC_CMC_Zellspannung_164, unit=Unit_Unit_MilliVolt, transfer-property=PENDING  # Einzelzellspannung zur Uebertragung per RTM
          signal BMC_CMC_Zellspannung_165_XIX_BMC_CMC_Zellspannung_05_XIX_HCP5_CANFD01: start 108, 12 bit, little-endian, data-type-policy=OVERRIDE, i-signal-type=PRIMITIVE, init-value=4094, base-type=BT_BMC_CMC_Zellspannung_165, invalid-value=Invalid_BMC_CMC_Zellspannung_165_XIX_BMC_CMC_Zellspannung_05_XIX_HCP5_CANFD01:4095, compu-method=CM_BMC_CMC_Zellspannung_165, data-constr=DC_BMC_CMC_Zellspannung_165, unit=Unit_Unit_MilliVolt, transfer-property=PENDING  # Einzelzellspannung zur Uebertragung per RTM
          signal BMC_CMC_Zellspannung_166_XIX_BMC_CMC_Zellspannung_05_XIX_HCP5_CANFD01: start 120, 12 bit, little-endian, data-type-policy=OVERRIDE, i-signal-type=PRIMITIVE, init-value=4094, base-type=BT_BMC_CMC_Zellspannung_166, invalid-value=Invalid_BMC_CMC_Zellspannung_166_XIX_BMC_CMC_Zellspannung_05_XIX_HCP5_CANFD01:4095, compu-method=CM_BMC_CMC_Zellspannung_166, data-constr=DC_BMC_CMC_Zellspannung_166, unit=Unit_Unit_MilliVolt, transfer-property=PENDING  # Einzelzellspannung zur Uebertragung per RTM
          signal BMC_CMC_Zellspannung_167_XIX_BMC_CMC_Zellspannung_05_XIX_HCP5_CANFD01: start 132, 12 bit, little-endian, data-type-policy=OVERRIDE, i-signal-type=PRIMITIVE, init-value=4094, base-type=BT_BMC_CMC_Zellspannung_167, invalid-value=Invalid_BMC_CMC_Zellspannung_167_XIX_BMC_CMC_Zellspannung_05_XIX_HCP5_CANFD01:4095, compu-method=CM_BMC_CMC_Zellspannung_167, data-constr=DC_BMC_CMC_Zellspannung_167, unit=Unit_Unit_MilliVolt, transfer-property=PENDING  # Einzelzellspannung zur Uebertragung per RTM
          signal BMC_CMC_Zellspannung_168_XIX_BMC_CMC_Zellspannung_05_XIX_HCP5_CANFD01: start 144, 12 bit, little-endian, data-type-policy=OVERRIDE, i-signal-type=PRIMITIVE, init-value=4094, base-type=BT_BMC_CMC_Zellspannung_168, invalid-value=Invalid_BMC_CMC_Zellspannung_168_XIX_BMC_CMC_Zellspannung_05_XIX_HCP5_CANFD01:4095, compu-method=CM_BMC_CMC_Zellspannung_168, data-constr=DC_BMC_CMC_Zellspannung_168, unit=Unit_Unit_MilliVolt, transfer-property=PENDING  # Einzelzellspannung zur Uebertragung per RTM
          signal BMC_CMC_Zellspannung_169_XIX_BMC_CMC_Zellspannung_05_XIX_HCP5_CANFD01: start 156, 12 bit, little-endian, data-type-policy=OVERRIDE, i-signal-type=PRIMITIVE, init-value=4094, base-type=BT_BMC_CMC_Zellspannung_169, invalid-value=Invalid_BMC_CMC_Zellspannung_169_XIX_BMC_CMC_Zellspannung_05_XIX_HCP5_CANFD01:4095, compu-method=CM_BMC_CMC_Zellspannung_169, data-constr=DC_BMC_CMC_Zellspannung_169, unit=Unit_Unit_MilliVolt, transfer-property=PENDING  # Einzelzellspannung zur Uebertragung per RTM
          signal BMC_CMC_Zellspannung_170_XIX_BMC_CMC_Zellspannung_05_XIX_HCP5_CANFD01: start 168, 12 bit, little-endian, data-type-policy=OVERRIDE, i-signal-type=PRIMITIVE, init-value=4094, base-type=BT_BMC_CMC_Zellspannung_170, invalid-value=Invalid_BMC_CMC_Zellspannung_170_XIX_BMC_CMC_Zellspannung_05_XIX_HCP5_CANFD01:4095, compu-method=CM_BMC_CMC_Zellspannung_170, data-constr=DC_BMC_CMC_Zellspannung_170, unit=Unit_Unit_MilliVolt, transfer-property=PENDING  # Einzelzellspannung zur Uebertragung per RTM
          signal BMC_CMC_Zellspannung_171_XIX_BMC_CMC_Zellspannung_05_XIX_HCP5_CANFD01: start 180, 12 bit, little-endian, data-type-policy=OVERRIDE, i-signal-type=PRIMITIVE, init-value=4094, base-type=BT_BMC_CMC_Zellspannung_171, invalid-value=Invalid_BMC_CMC_Zellspannung_171_XIX_BMC_CMC_Zellspannung_05_XIX_HCP5_CANFD01:4095, compu-method=CM_BMC_CMC_Zellspannung_171, data-constr=DC_BMC_CMC_Zellspannung_171, unit=Unit_Unit_MilliVolt, transfer-property=PENDING  # Einzelzellspannung zur Uebertragung per RTM
          signal BMC_CMC_Zellspannung_172_XIX_BMC_CMC_Zellspannung_05_XIX_HCP5_CANFD01: start 192, 12 bit, little-endian, data-type-policy=OVERRIDE, i-signal-type=PRIMITIVE, init-value=4094, base-type=BT_BMC_CMC_Zellspannung_172, invalid-value=Invalid_BMC_CMC_Zellspannung_172_XIX_BMC_CMC_Zellspannung_05_XIX_HCP5_CANFD01:4095, compu-method=CM_BMC_CMC_Zellspannung_172, data-constr=DC_BMC_CMC_Zellspannung_172, unit=Unit_Unit_MilliVolt, transfer-property=PENDING  # Einzelzellspannung zur Uebertragung per RTM
          signal BMC_CMC_Zellspannung_173_XIX_BMC_CMC_Zellspannung_05_XIX_HCP5_CANFD01: start 204, 12 bit, little-endian, data-type-policy=OVERRIDE, i-signal-type=PRIMITIVE, init-value=4094, base-type=BT_BMC_CMC_Zellspannung_173, invalid-value=Invalid_BMC_CMC_Zellspannung_173_XIX_BMC_CMC_Zellspannung_05_XIX_HCP5_CANFD01:4095, compu-method=CM_BMC_CMC_Zellspannung_173, data-constr=DC_BMC_CMC_Zellspannung_173, unit=Unit_Unit_MilliVolt, transfer-property=PENDING  # Einzelzellspannung zur Uebertragung per RTM
          signal BMC_CMC_Zellspannung_174_XIX_BMC_CMC_Zellspannung_05_XIX_HCP5_CANFD01: start 216, 12 bit, little-endian, data-type-policy=OVERRIDE, i-signal-type=PRIMITIVE, init-value=4094, base-type=BT_BMC_CMC_Zellspannung_174, invalid-value=Invalid_BMC_CMC_Zellspannung_174_XIX_BMC_CMC_Zellspannung_05_XIX_HCP5_CANFD01:4095, compu-method=CM_BMC_CMC_Zellspannung_174, data-constr=DC_BMC_CMC_Zellspannung_174, unit=Unit_Unit_MilliVolt, transfer-property=PENDING  # Einzelzellspannung zur Uebertragung per RTM
          signal BMC_CMC_Zellspannung_175_XIX_BMC_CMC_Zellspannung_05_XIX_HCP5_CANFD01: start 228, 12 bit, little-endian, data-type-policy=OVERRIDE, i-signal-type=PRIMITIVE, init-value=4094, base-type=BT_BMC_CMC_Zellspannung_175, invalid-value=Invalid_BMC_CMC_Zellspannung_175_XIX_BMC_CMC_Zellspannung_05_XIX_HCP5_CANFD01:4095, compu-method=CM_BMC_CMC_Zellspannung_175, data-constr=DC_BMC_CMC_Zellspannung_175, unit=Unit_Unit_MilliVolt, transfer-property=PENDING  # Einzelzellspannung zur Uebertragung per RTM
          signal BMC_CMC_Zellspannung_176_XIX_BMC_CMC_Zellspannung_05_XIX_HCP5_CANFD01: start 240, 12 bit, little-endian, data-type-policy=OVERRIDE, i-signal-type=PRIMITIVE, init-value=4094, base-type=BT_BMC_CMC_Zellspannung_176, invalid-value=Invalid_BMC_CMC_Zellspannung_176_XIX_BMC_CMC_Zellspannung_05_XIX_HCP5_CANFD01:4095, compu-method=CM_BMC_CMC_Zellspannung_176, data-constr=DC_BMC_CMC_Zellspannung_176, unit=Unit_Unit_MilliVolt, transfer-property=PENDING  # Einzelzellspannung zur Uebertragung per RTM
          signal BMC_CMC_Zellspannung_177_XIX_BMC_CMC_Zellspannung_05_XIX_HCP5_CANFD01: start 252, 12 bit, little-endian, data-type-policy=OVERRIDE, i-signal-type=PRIMITIVE, init-value=4094, base-type=BT_BMC_CMC_Zellspannung_177, invalid-value=Invalid_BMC_CMC_Zellspannung_177_XIX_BMC_CMC_Zellspannung_05_XIX_HCP5_CANFD01:4095, compu-method=CM_BMC_CMC_Zellspannung_177, data-constr=DC_BMC_CMC_Zellspannung_177, unit=Unit_Unit_MilliVolt, transfer-property=PENDING  # Einzelzellspannung zur Uebertragung per RTM
          signal BMC_CMC_Zellspannung_178_XIX_BMC_CMC_Zellspannung_05_XIX_HCP5_CANFD01: start 264, 12 bit, little-endian, data-type-policy=OVERRIDE, i-signal-type=PRIMITIVE, init-value=4094, base-type=BT_BMC_CMC_Zellspannung_178, invalid-value=Invalid_BMC_CMC_Zellspannung_178_XIX_BMC_CMC_Zellspannung_05_XIX_HCP5_CANFD01:4095, compu-method=CM_BMC_CMC_Zellspannung_178, data-constr=DC_BMC_CMC_Zellspannung_178, unit=Unit_Unit_MilliVolt, transfer-property=PENDING  # Einzelzellspannung zur Uebertragung per RTM
          signal BMC_CMC_Zellspannung_179_XIX_BMC_CMC_Zellspannung_05_XIX_HCP5_CANFD01: start 276, 12 bit, little-endian, data-type-policy=OVERRIDE, i-signal-type=PRIMITIVE, init-value=4094, base-type=BT_BMC_CMC_Zellspannung_179, invalid-value=Invalid_BMC_CMC_Zellspannung_179_XIX_BMC_CMC_Zellspannung_05_XIX_HCP5_CANFD01:4095, compu-method=CM_BMC_CMC_Zellspannung_179, data-constr=DC_BMC_CMC_Zellspannung_179, unit=Unit_Unit_MilliVolt, transfer-property=PENDING  # Einzelzellspannung zur Uebertragung per RTM
          signal BMC_CMC_Zellspannung_180_XIX_BMC_CMC_Zellspannung_05_XIX_HCP5_CANFD01: start 288, 12 bit, little-endian, data-type-policy=OVERRIDE, i-signal-type=PRIMITIVE, init-value=4094, base-type=BT_BMC_CMC_Zellspannung_180, invalid-value=Invalid_BMC_CMC_Zellspannung_180_XIX_BMC_CMC_Zellspannung_05_XIX_HCP5_CANFD01:4095, compu-method=CM_BMC_CMC_Zellspannung_180, data-constr=DC_BMC_CMC_Zellspannung_180, unit=Unit_Unit_MilliVolt, transfer-property=PENDING  # Einzelzellspannung zur Uebertragung per RTM
          signal BMC_CMC_Zellspannung_181_XIX_BMC_CMC_Zellspannung_05_XIX_HCP5_CANFD01: start 300, 12 bit, little-endian, data-type-policy=OVERRIDE, i-signal-type=PRIMITIVE, init-value=4094, base-type=BT_BMC_CMC_Zellspannung_181, invalid-value=Invalid_BMC_CMC_Zellspannung_181_XIX_BMC_CMC_Zellspannung_05_XIX_HCP5_CANFD01:4095, compu-method=CM_BMC_CMC_Zellspannung_181, data-constr=DC_BMC_CMC_Zellspannung_181, unit=Unit_Unit_MilliVolt, transfer-property=PENDING  # Einzelzellspannung zur Uebertragung per RTM
          signal BMC_CMC_Zellspannung_182_XIX_BMC_CMC_Zellspannung_05_XIX_HCP5_CANFD01: start 312, 12 bit, little-endian, data-type-policy=OVERRIDE, i-signal-type=PRIMITIVE, init-value=4094, base-type=BT_BMC_CMC_Zellspannung_182, invalid-value=Invalid_BMC_CMC_Zellspannung_182_XIX_BMC_CMC_Zellspannung_05_XIX_HCP5_CANFD01:4095, compu-method=CM_BMC_CMC_Zellspannung_182, data-constr=DC_BMC_CMC_Zellspannung_182, unit=Unit_Unit_MilliVolt, transfer-property=PENDING  # Einzelzellspannung zur Uebertragung per RTM
          signal BMC_CMC_Zellspannung_183_XIX_BMC_CMC_Zellspannung_05_XIX_HCP5_CANFD01: start 324, 12 bit, little-endian, data-type-policy=OVERRIDE, i-signal-type=PRIMITIVE, init-value=4094, base-type=BT_BMC_CMC_Zellspannung_183, invalid-value=Invalid_BMC_CMC_Zellspannung_183_XIX_BMC_CMC_Zellspannung_05_XIX_HCP5_CANFD01:4095, compu-method=CM_BMC_CMC_Zellspannung_183, data-constr=DC_BMC_CMC_Zellspannung_183, unit=Unit_Unit_MilliVolt, transfer-property=PENDING  # Einzelzellspannung zur Uebertragung per RTM
          signal BMC_CMC_Zellspannung_184_XIX_BMC_CMC_Zellspannung_05_XIX_HCP5_CANFD01: start 336, 12 bit, little-endian, data-type-policy=OVERRIDE, i-signal-type=PRIMITIVE, init-value=4094, base-type=BT_BMC_CMC_Zellspannung_184, invalid-value=Invalid_BMC_CMC_Zellspannung_184_XIX_BMC_CMC_Zellspannung_05_XIX_HCP5_CANFD01:4095, compu-method=CM_BMC_CMC_Zellspannung_184, data-constr=DC_BMC_CMC_Zellspannung_184, unit=Unit_Unit_MilliVolt, transfer-property=PENDING  # Einzelzellspannung zur Uebertragung per RTM
          signal BMC_CMC_Zellspannung_185_XIX_BMC_CMC_Zellspannung_05_XIX_HCP5_CANFD01: start 348, 12 bit, little-endian, data-type-policy=OVERRIDE, i-signal-type=PRIMITIVE, init-value=4094, base-type=BT_BMC_CMC_Zellspannung_185, invalid-value=Invalid_BMC_CMC_Zellspannung_185_XIX_BMC_CMC_Zellspannung_05_XIX_HCP5_CANFD01:4095, compu-method=CM_BMC_CMC_Zellspannung_185, data-constr=DC_BMC_CMC_Zellspannung_185, unit=Unit_Unit_MilliVolt, transfer-property=PENDING  # Einzelzellspannung zur Uebertragung per RTM
          signal BMC_CMC_Zellspannung_186_XIX_BMC_CMC_Zellspannung_05_XIX_HCP5_CANFD01: start 360, 12 bit, little-endian, data-type-policy=OVERRIDE, i-signal-type=PRIMITIVE, init-value=4094, base-type=BT_BMC_CMC_Zellspannung_186, invalid-value=Invalid_BMC_CMC_Zellspannung_186_XIX_BMC_CMC_Zellspannung_05_XIX_HCP5_CANFD01:4095, compu-method=CM_BMC_CMC_Zellspannung_186, data-constr=DC_BMC_CMC_Zellspannung_186, unit=Unit_Unit_MilliVolt, transfer-property=PENDING  # Einzelzellspannung zur Uebertragung per RTM
          signal BMC_CMC_Zellspannung_187_XIX_BMC_CMC_Zellspannung_05_XIX_HCP5_CANFD01: start 372, 12 bit, little-endian, data-type-policy=OVERRIDE, i-signal-type=PRIMITIVE, init-value=4094, base-type=BT_BMC_CMC_Zellspannung_187, invalid-value=Invalid_BMC_CMC_Zellspannung_187_XIX_BMC_CMC_Zellspannung_05_XIX_HCP5_CANFD01:4095, compu-method=CM_BMC_CMC_Zellspannung_187, data-constr=DC_BMC_CMC_Zellspannung_187, unit=Unit_Unit_MilliVolt, transfer-property=PENDING  # Einzelzellspannung zur Uebertragung per RTM
          signal BMC_CMC_Zellspannung_188_XIX_BMC_CMC_Zellspannung_05_XIX_HCP5_CANFD01: start 384, 12 bit, little-endian, data-type-policy=OVERRIDE, i-signal-type=PRIMITIVE, init-value=4094, base-type=BT_BMC_CMC_Zellspannung_188, invalid-value=Invalid_BMC_CMC_Zellspannung_188_XIX_BMC_CMC_Zellspannung_05_XIX_HCP5_CANFD01:4095, compu-method=CM_BMC_CMC_Zellspannung_188, data-constr=DC_BMC_CMC_Zellspannung_188, unit=Unit_Unit_MilliVolt, transfer-property=PENDING  # Einzelzellspannung zur Uebertragung per RTM
          signal BMC_CMC_Zellspannung_189_XIX_BMC_CMC_Zellspannung_05_XIX_HCP5_CANFD01: start 396, 12 bit, little-endian, data-type-policy=OVERRIDE, i-signal-type=PRIMITIVE, init-value=4094, base-type=BT_BMC_CMC_Zellspannung_189, invalid-value=Invalid_BMC_CMC_Zellspannung_189_XIX_BMC_CMC_Zellspannung_05_XIX_HCP5_CANFD01:4095, compu-method=CM_BMC_CMC_Zellspannung_189, data-constr=DC_BMC_CMC_Zellspannung_189, unit=Unit_Unit_MilliVolt, transfer-property=PENDING  # Einzelzellspannung zur Uebertragung per RTM
          signal BMC_CMC_Zellspannung_190_XIX_BMC_CMC_Zellspannung_05_XIX_HCP5_CANFD01: start 408, 12 bit, little-endian, data-type-policy=OVERRIDE, i-signal-type=PRIMITIVE, init-value=4094, base-type=BT_BMC_CMC_Zellspannung_190, invalid-value=Invalid_BMC_CMC_Zellspannung_190_XIX_BMC_CMC_Zellspannung_05_XIX_HCP5_CANFD01:4095, compu-method=CM_BMC_CMC_Zellspannung_190, data-constr=DC_BMC_CMC_Zellspannung_190, unit=Unit_Unit_MilliVolt, transfer-property=PENDING  # Einzelzellspannung zur Uebertragung per RTM
          signal BMC_CMC_Zellspannung_191_XIX_BMC_CMC_Zellspannung_05_XIX_HCP5_CANFD01: start 420, 12 bit, little-endian, data-type-policy=OVERRIDE, i-signal-type=PRIMITIVE, init-value=4094, base-type=BT_BMC_CMC_Zellspannung_191, invalid-value=Invalid_BMC_CMC_Zellspannung_191_XIX_BMC_CMC_Zellspannung_05_XIX_HCP5_CANFD01:4095, compu-method=CM_BMC_CMC_Zellspannung_191, data-constr=DC_BMC_CMC_Zellspannung_191, unit=Unit_Unit_MilliVolt, transfer-property=PENDING  # Einzelzellspannung zur Uebertragung per RTM
          signal BMC_CMC_Zellspannung_192_XIX_BMC_CMC_Zellspannung_05_XIX_HCP5_CANFD01: start 432, 12 bit, little-endian, data-type-policy=OVERRIDE, i-signal-type=PRIMITIVE, init-value=4094, base-type=BT_BMC_CMC_Zellspannung_192, invalid-value=Invalid_BMC_CMC_Zellspannung_192_XIX_BMC_CMC_Zellspannung_05_XIX_HCP5_CANFD01:4095, compu-method=CM_BMC_CMC_Zellspannung_192, data-constr=DC_BMC_CMC_Zellspannung_192, unit=Unit_Unit_MilliVolt, transfer-property=PENDING  # Einzelzellspannung zur Uebertragung per RTM
          signal BMC_CMC_Zellspannung_05_Messzeit_XIX_BMC_CMC_Zellspannung_05_XIX_HCP5_CANFD01: start 444, 8 bit, little-endian, data-type-policy=OVERRIDE, i-signal-type=PRIMITIVE, init-value=254, base-type=BT_BMC_CMC_Zellspannung_05_Messzeit, invalid-value=Invalid_BMC_CMC_Zellspannung_05_Messzeit_XIX_BMC_CMC_Zellspannung_05_XIX_HCP5_CANFD01:255, compu-method=CM_BMC_CMC_Zellspannung_05_Messzeit, data-constr=DC_BMC_CMC_Zellspannung_05_Messzeit, unit=Unit_Unit_None, transfer-property=PENDING  # Messzeit zu Botschaft BMC_CMC_Zellspannung_05
      frame BMC_HV_01_SOK_XIX_HCP5_CANFD01: id 0x113, from BMC_HV, frame-length=20, can-addressing-mode=STANDARD, can-frame-rx-behavior=CAN-FD, can-frame-tx-behavior=CAN-FD
        secured i pdu BMC_HV_01_E2E_SOK_XIX_HCP5_CANFD01:
          length=20
          authentication-props=SecureCommunicationAuthenticationProps_XIX_32
          freshness-props=SecureCommunicationFreshnessProps
          payload=PT_BMC_HV_01_E2E
          secure-communication-props={auth-data-freshness-length=0, auth-data-freshness-start-position=0, auth-info-tx-length=32, authentication-build-attempts=1, authentication-retries=4, data-id=533, freshness-value-id=0, freshness-value-length=64, freshness-value-tx-length=0}
          use-as-cryptographic-i-pdu=false
      frame BMC_HV_02_SOK_XIX_HCP5_CANFD01: id 0x12DD5514, from BMC_HV, frame-length=48, can-addressing-mode=EXTENDED, can-frame-rx-behavior=CAN-FD, can-frame-tx-behavior=CAN-FD
        secured i pdu BMC_HV_02_E2E_SOK_XIX_HCP5_CANFD01:
          length=48
          authentication-props=SecureCommunicationAuthenticationProps_XIX_32
          freshness-props=SecureCommunicationFreshnessProps
          payload=PT_BMC_HV_02_E2E
          secure-communication-props={auth-data-freshness-length=0, auth-data-freshness-start-position=0, auth-info-tx-length=32, authentication-build-attempts=1, authentication-retries=4, data-id=534, freshness-value-id=1, freshness-value-length=64, freshness-value-tx-length=0}
          use-as-cryptographic-i-pdu=false
      frame BMC_HV_03_XIX_HCP5_CANFD01: id 0x1A555555, from BMC_HV, frame-length=24, can-addressing-mode=EXTENDED, can-frame-rx-behavior=CAN-FD, can-frame-tx-behavior=CAN-FD
        pdu BMC_HV_03_XIX_HCP5_CANFD01: length=24, transmission-mode-true-timing=cyclic-timing={time-offset=0, time-period=0.5}, unused-bit-pattern=0
          signal BMC_ThermSpreizung_XIX_BMC_HV_03_XIX_HCP5_CANFD01: start 12, 4 bit, little-endian, data-type-policy=OVERRIDE, i-signal-type=PRIMITIVE, init-value=14, base-type=BT_BMC_ThermSpreizung, invalid-value=Invalid_BMC_ThermSpreizung_XIX_BMC_HV_03_XIX_HCP5_CANFD01:15, compu-method=CM_BMC_ThermSpreizung, data-constr=DC_BMC_ThermSpreizung, unit=Unit_Unit_PerCent, transfer-property=PENDING  # Beschreibt die thermische Spreizung der HV-Batterie. 0 % homogener Temperaturverlauf. 100% hoechst heterogener Temperaturverlauf
          signal BMC_VorlaufTemperatur_XIX_BMC_HV_03_XIX_HCP5_CANFD01: start 16, 10 bit, little-endian, data-type-policy=OVERRIDE, i-signal-type=PRIMITIVE, init-value=1022, base-type=BT_BMC_VorlaufTemperatur, invalid-value=Invalid_BMC_VorlaufTemperatur_XIX_BMC_HV_03_XIX_HCP5_CANFD01:1023, compu-method=CM_BMC_VorlaufTemperatur, data-constr=DC_BMC_VorlaufTemperatur, unit=Unit_Unit_DegreCelsi, transfer-property=PENDING  # Aktuelle Vorlauftemperatur der Batterie
          signal BMC_RuecklaufTemperatur_XIX_BMC_HV_03_XIX_HCP5_CANFD01: start 26, 10 bit, little-endian, data-type-policy=OVERRIDE, i-signal-type=PRIMITIVE, init-value=1022, base-type=BT_BMC_RuecklaufTemperatur, invalid-value=Invalid_BMC_RuecklaufTemperatur_XIX_BMC_HV_03_XIX_HCP5_CANFD01:1023, compu-method=CM_BMC_RuecklaufTemperatur, data-constr=DC_BMC_RuecklaufTemperatur, unit=Unit_Unit_DegreCelsi, transfer-property=PENDING  # Aktuelle Ruecklauftemperatur der Batterie
          signal BMC_Temperatur_XIX_BMC_HV_03_XIX_HCP5_CANFD01: start 36, 10 bit, little-endian, data-type-policy=OVERRIDE, i-signal-type=PRIMITIVE, init-value=1022, base-type=BT_BMC_Temperatur, invalid-value=Invalid_BMC_Temperatur_XIX_BMC_HV_03_XIX_HCP5_CANFD01:1023, compu-method=CM_BMC_Temperatur, data-constr=DC_BMC_Temperatur, unit=Unit_Unit_DegreCelsi, transfer-property=PENDING  # battery temperature / Momentanwert: Temperatur der Traktionsbatterie
          signal BMC_Abschaltankuendigung_XIX_BMC_HV_03_XIX_HCP5_CANFD01: start 46, 10 bit, little-endian, data-type-policy=OVERRIDE, i-signal-type=PRIMITIVE, init-value=1022, base-type=BT_BMC_Abschaltankuendigung, invalid-value=Invalid_BMC_Abschaltankuendigung_XIX_BMC_HV_03_XIX_HCP5_CANFD01:1023, compu-method=CM_BMC_Abschaltankuendigung, data-constr=DC_BMC_Abschaltankuendigung, unit=Unit_Unit_Secon, transfer-property=PENDING  # Zeitliche Ankündigung einer Abschaltung der HV Batterie.
          signal BMC_NutzbareKapazitaet_XIX_BMC_HV_03_XIX_HCP5_CANFD01: start 56, 12 bit, little-endian, data-type-policy=OVERRIDE, i-signal-type=PRIMITIVE, init-value=4094, base-type=BT_BMC_NutzbareKapazitaet, invalid-value=Invalid_BMC_NutzbareKapazitaet_XIX_BMC_HV_03_XIX_HCP5_CANFD01:4095, compu-method=CM_BMC_NutzbareKapazitaet, data-constr=DC_BMC_NutzbareKapazitaet, unit=Unit_Unit_AmperHour, transfer-property=PENDING  # Nutzbare Kapazität der Batterie, entspricht der Ladungsmenge von 100% NutzbarerSOC. Diese Größe ist abhängig vom Bank-Modus (seriell/parallel).
          signal BMC_Dauer_Entladeleistung_XIX_BMC_HV_03_XIX_HCP5_CANFD01: start 68, 12 bit, little-endian, data-type-policy=OVERRIDE, i-signal-type=PRIMITIVE, init-value=4094, base-type=BT_BMC_Dauer_Entladeleistung, invalid-value=Invalid_BMC_Dauer_Entladeleistung_XIX_BMC_HV_03_XIX_HCP5_CANFD01:4095, compu-method=CM_BMC_Dauer_Entladeleistung, data-constr=DC_BMC_Dauer_Entladeleistung, unit=Unit_Unit_Watt, transfer-property=PENDING  # ist die aktuelle Dauer-Leistungsfähigkeit der Batterie. Wenn dieser Wert überschritten wird, kann ein zeitliches Derating der maximalen Leistungsgrenzen stattfindet. Die Dauerleistung ändert sich mit Batterietemperatur und Ladezustand.
          signal BMC_Dauer_Ladeleistung_XIX_BMC_HV_03_XIX_HCP5_CANFD01: start 80, 12 bit, little-endian, data-type-policy=OVERRIDE, i-signal-type=PRIMITIVE, init-value=4094, base-type=BT_BMC_Dauer_Ladeleistung, invalid-value=Invalid_BMC_Dauer_Ladeleistung_XIX_BMC_HV_03_XIX_HCP5_CANFD01:4095, compu-method=CM_BMC_Dauer_Ladeleistung, data-constr=DC_BMC_Dauer_Ladeleistung, unit=Unit_Unit_Watt, transfer-property=PENDING  # ist die aktuelle Dauer-Leistungsfähigkeit der Batterie. Wenn dieser Wert überschritten wird, kann ein zeitliches Derating der maximalen Leistungsgrenzen stattfindet. Die Dauerleistung ändert sich mit Batterietemperatur und Ladezustand.
          signal BMC_VerlustEnergie_XIX_BMC_HV_03_XIX_HCP5_CANFD01: start 92, 13 bit, little-endian, data-type-policy=OVERRIDE, i-signal-type=PRIMITIVE, init-value=8190, base-type=BT_BMC_VerlustEnergie, invalid-value=Invalid_BMC_VerlustEnergie_XIX_BMC_HV_03_XIX_HCP5_CANFD01:8191, compu-method=CM_BMC_VerlustEnergie, data-constr=DC_BMC_VerlustEnergie, unit=Unit_Unit_WattHour, transfer-property=PENDING  # Verlustenergie für den Fall, dass I=Irwds eingeprägt wird im HV-ON bis zur vollständigen Entladung (KundenSOC=0%) . Im AC/DC-Laden bis zur vollständigen Ladung (KundenSOC=100%).
          signal BMC_ThermAuslastung_XIX_BMC_HV_03_XIX_HCP5_CANFD01: start 105, 7 bit, little-endian, data-type-policy=OVERRIDE, i-signal-type=PRIMITIVE, init-value=126, base-type=BT_BMC_ThermAuslastung, invalid-value=Invalid_BMC_ThermAuslastung_XIX_BMC_HV_03_XIX_HCP5_CANFD01:127, compu-method=CM_BMC_ThermAuslastung, data-constr=DC_BMC_ThermAuslastung, unit=Unit_Unit_PerCent, transfer-property=PENDING  # 0- hohe Heizanforderung funktionale Einschränkung 26- mittlere Heizanforderung Temperatur anheben 36- kleine Heizanforderung passives Heizen 46- thermischer Wohlfühlbereich keine Kühl-/Heizleistung 56- kleine Kühlstufe Temperatur halten 66- mittlere Kühlstufe Temperatur absenken 76- große Kühlstufe funktionale Einschränkung 101- Notfallkühlung 126- Init 127- Fehler
          signal BMC_MaxEnergieinhalt_XIX_BMC_HV_03_XIX_HCP5_CANFD01: start 112, 16 bit, little-endian, data-type-policy=OVERRIDE, i-signal-type=PRIMITIVE, init-value=65534, base-type=BT_BMC_MaxEnergieinhalt, invalid-value=Invalid_BMC_MaxEnergieinhalt_XIX_BMC_HV_03_XIX_HCP5_CANFD01:65535, compu-method=CM_BMC_MaxEnergieinhalt, data-constr=DC_BMC_MaxEnergieinhalt, unit=Unit_Unit_WattHour, transfer-property=PENDING  # Maximaler Energieinhalt der Batterie bei 100% NutzbarerSOC unter Beruecksichtigung der Verluste (I_RWDS)
          signal BMC_Energie_Entladen_XIX_BMC_HV_03_XIX_HCP5_CANFD01: start 128, 16 bit, little-endian, data-type-policy=OVERRIDE, i-signal-type=PRIMITIVE, init-value=65534, base-type=BT_BMC_Energie_Entladen, invalid-value=Invalid_BMC_Energie_Entladen_XIX_BMC_HV_03_XIX_HCP5_CANFD01:65535, compu-method=CM_BMC_Energie_Entladen, data-constr=DC_BMC_Energie_Entladen, unit=Unit_Unit_KiloWattHour, transfer-property=PENDING  # Energie, welche seit dem letzten Fahrzyklus während eines Ladevorgangs aus der HV-Batterie entnommen wurde
          signal BMC_Energie_Laden_XIX_BMC_HV_03_XIX_HCP5_CANFD01: start 144, 16 bit, little-endian, data-type-policy=OVERRIDE, i-signal-type=PRIMITIVE, init-value=65534, base-type=BT_BMC_Energie_Laden, invalid-value=Invalid_BMC_Energie_Laden_XIX_BMC_HV_03_XIX_HCP5_CANFD01:65535, compu-method=CM_BMC_Energie_Laden, data-constr=DC_BMC_Energie_Laden, unit=Unit_Unit_KiloWattHour, transfer-property=PENDING  # Energie, welche seit dem letzten Fahrzyklus während eines Ladevorgansg in die HV-Batterie geladen wurde.
          signal BMC_Konditionierung_Anf_XIX_BMC_HV_03_XIX_HCP5_CANFD01: start 160, 1 bit, little-endian, data-type-policy=OVERRIDE, i-signal-type=PRIMITIVE, init-value=0, base-type=BT_BMC_Konditionierung_Anf, compu-method=CM_BMC_Konditionierung_Anf, data-constr=DC_BMC_Konditionierung_Anf, transfer-property=PENDING  # Anforderung der HV Batterie um deren thermische Konditionierung durchzuführen nachdem das Fahrzeug geweckt wurde.
          signal BMC_Bidi_Min_SoC_XIX_BMC_HV_03_XIX_HCP5_CANFD01: start 161, 7 bit, little-endian, data-type-policy=OVERRIDE, i-signal-type=PRIMITIVE, init-value=126, base-type=BT_BMC_Bidi_Min_SoC, invalid-value=Invalid_BMC_Bidi_Min_SoC_XIX_BMC_HV_03_XIX_HCP5_CANFD01:127, compu-method=CM_BMC_Bidi_Min_SoC, data-constr=DC_BMC_Bidi_Min_SoC, unit=Unit_Unit_PerCent, transfer-property=PENDING  # Wertebereich: 0 - 100% Defaultwert: 20%
          signal BMC_Bidi_GenutzteEnergie_XIX_BMC_HV_03_XIX_HCP5_CANFD01: start 168, 16 bit, little-endian, data-type-policy=OVERRIDE, i-signal-type=PRIMITIVE, init-value=65534, base-type=BT_BMC_Bidi_GenutzteEnergie, invalid-value=Invalid_BMC_Bidi_GenutzteEnergie_XIX_BMC_HV_03_XIX_HCP5_CANFD01:65535, compu-method=CM_BMC_Bidi_GenutzteEnergie, data-constr=DC_BMC_Bidi_GenutzteEnergie, unit=Unit_Unit_KiloWattHour, transfer-property=PENDING  # Beschreibt den bereits verwendeten Energiedurchsatz (Absolutwert, für Entladen) für die Funktion Bidi.
          signal BMC_Bidi_Veto_Temp_XIX_BMC_HV_03_XIX_HCP5_CANFD01: start 184, 1 bit, little-endian, data-type-policy=OVERRIDE, i-signal-type=PRIMITIVE, init-value=0, base-type=BT_BMC_Bidi_Veto_Temp, compu-method=CM_BMC_Bidi_Veto_Temp, data-constr=DC_BMC_Bidi_Veto_Temp, transfer-property=PENDING  # Freigabestatus der Funktion Bidi in Abhängigkeit der Ist-Temperatur
          signal BMC_Bidi_Max_SoC_XIX_BMC_HV_03_XIX_HCP5_CANFD01: start 185, 7 bit, little-endian, data-type-policy=OVERRIDE, i-signal-type=PRIMITIVE, init-value=126, base-type=BT_BMC_Bidi_Max_SoC, invalid-value=Invalid_BMC_Bidi_Max_SoC_XIX_BMC_HV_03_XIX_HCP5_CANFD01:127, compu-method=CM_BMC_Bidi_Max_SoC, data-constr=DC_BMC_Bidi_Max_SoC, unit=Unit_Unit_PerCent, transfer-property=PENDING  # Wertebereich: 0 - 100% Defaultwert: 80%
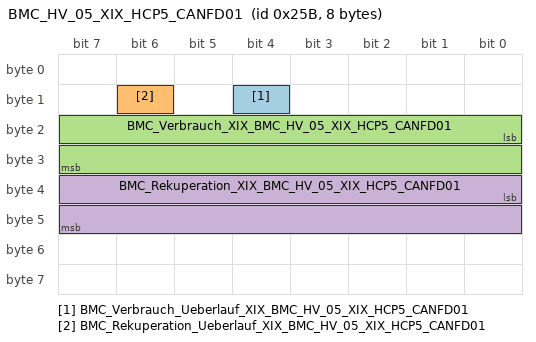
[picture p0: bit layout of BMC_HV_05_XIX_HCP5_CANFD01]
      frame BMC_HV_05_XIX_HCP5_CANFD01: id 0x25B, from BMC_HV, frame-length=8, can-addressing-mode=STANDARD, can-frame-rx-behavior=CAN-FD, can-frame-tx-behavior=CAN-FD
        pdu BMC_HV_05_XIX_HCP5_CANFD01: length=8, transmission-mode-true-timing=cyclic-timing={time-offset=0, time-period=0.05}, unused-bit-pattern=0
          signal BMC_Verbrauch_Ueberlauf_XIX_BMC_HV_05_XIX_HCP5_CANFD01: start 12, 1 bit, little-endian, data-type-policy=OVERRIDE, i-signal-type=PRIMITIVE, init-value=0, base-type=BT_BMC_Verbrauch_Ueberlauf, compu-method=CM_BMC_Verbrauch_Ueberlauf, data-constr=DC_BMC_Verbrauch_Ueberlauf, transfer-property=PENDING  # Signalisiert ob der Überlauf einen physikalischer Ursprung hat (0 = kein Überlauf oder Überlauf mit keinem physikalischem Ursprung)
          signal BMC_Rekuperation_Ueberlauf_XIX_BMC_HV_05_XIX_HCP5_CANFD01: start 14, 1 bit, little-endian, data-type-policy=OVERRIDE, i-signal-type=PRIMITIVE, init-value=0, base-type=BT_BMC_Rekuperation_Ueberlauf, compu-method=CM_BMC_Rekuperation_Ueberlauf, data-constr=DC_BMC_Rekuperation_Ueberlauf, transfer-property=PENDING  # Signalisiert ob der Überlauf einen physikalischer Ursprung hat (0 = kein Überlauf oder Überlauf mit keinem physikalischem Ursprung)
          signal BMC_Verbrauch_XIX_BMC_HV_05_XIX_HCP5_CANFD01: start 16, 16 bit, little-endian, data-type-policy=OVERRIDE, i-signal-type=PRIMITIVE, init-value=0, base-type=BT_BMC_Verbrauch, compu-method=CM_BMC_Verbrauch, data-constr=DC_BMC_Verbrauch, unit=Unit_Unit_WattSecond, transfer-property=PENDING  # Zähler: Energieentnahme aus der HV-Batterie
          signal BMC_Rekuperation_XIX_BMC_HV_05_XIX_HCP5_CANFD01: start 32, 16 bit, little-endian, data-type-policy=OVERRIDE, i-signal-type=PRIMITIVE, init-value=0, base-type=BT_BMC_Rekuperation, compu-method=CM_BMC_Rekuperation, data-constr=DC_BMC_Rekuperation, unit=Unit_Unit_WattSecond, transfer-property=PENDING  # Zähler: Anzeigesignal: Energiezufuhr in die HV-Batterie (Reku). Darf nicht durch Laden der Batterie bedatet werden
